VERSION ""

NS_ :

BS_:

BU_: PowertrainControlModule AtmosphericSensor SafetyRestraintSystem2 Aftertreatment_2_GasOutlet Aftertreatment_2_GasIntake DieselParticulateFilterControl Turbocharger SafetyRestraintSystem1 CabDisplay2 Aftertreatment_1_GasOutlet Aftertreatment_1_GasIntake OnBoardDataLogger OffBoardDiagnosticTool2 OffBoardDiagnosticTool1 FileServer ParkingBrakeController SeatController2 FanDriveController SteeringColumnUnit CommunicationUnitRadio CommunicationUnitSatellite CommunicationUnitCellular PropulsionBatteryCharger ChassisController2 ChassisController1 EngineValveControl AuxiliaryHeater2 AuxiliaryHeater1 ClutchUnit RampControl InformationSystem1 SuspensionSystemController2 OilSensor VehicleDynamicStability ExhaustEmissionController TransmissionDisplay2 TransmissionDisplay1 ClimateControl2 WaterPumpController RearAxleSteeringController LightingOperatorControl SeatController1 IgnitionController2 IgnitionController1 TirePressureController CabController2 CabController1 PneumaticSystemController SuspensionSystemController1 HydraulicPumpController EnduranceBrakingSystem RetarderExhaustEngine2 OnBoardDiagnosticUnit HeadwayController RetarderExhaustEngine1 CabDisplay1 ManagementComputer VirtualTerminal OffVehicleGateway PowerTakeOffFront HitchControl AuxiliaryValveControl BodyController TractorTrailerBridge1 StarterSystem ElectricalSystem VehicleSecurity VehicleNavigation AerodynamicControl ElectricalChargingSystem ClimateControl1 TripRecorder InstrumentCluster SuspensionDriveAxle2 SuspensionDriveAxle1 SuspensionSteerAxle SteeringController FuelSystem CruiseControl RetarderDriveline RetarderEngine BrakesDriveAxle2 BrakesDriveAxle1 BrakesSystemController BrakesSteerAxle AxleDrive2 AxleDrive1 AxleSteering PowerTakeOff ShiftConsoleSecondary ShiftConsolePrimary Transmission2 Transmission1 Engine2 Engine1

BO_ 2566697982 FPOC: 64 Vector__XXX
 SG_ FusedOutput32Current : 496|16@1+ (0.005,0) [0|321.275] "A" Vector__XXX
 SG_ FusedOutput31Current : 480|16@1+ (0.005,0) [0|321.275] "A" Vector__XXX
 SG_ FusedOutput30Current : 464|16@1+ (0.005,0) [0|321.275] "A" Vector__XXX
 SG_ FusedOutput29Current : 448|16@1+ (0.005,0) [0|321.275] "A" Vector__XXX
 SG_ FusedOutput28Current : 432|16@1+ (0.005,0) [0|321.275] "A" Vector__XXX
 SG_ FusedOutput27Current : 416|16@1+ (0.005,0) [0|321.275] "A" Vector__XXX
 SG_ FusedOutput26Current : 400|16@1+ (0.005,0) [0|321.275] "A" Vector__XXX
 SG_ FusedOutput25Current : 384|16@1+ (0.005,0) [0|321.275] "A" Vector__XXX
 SG_ FusedOutput24Current : 368|16@1+ (0.005,0) [0|321.275] "A" Vector__XXX
 SG_ FusedOutput23Current : 352|16@1+ (0.005,0) [0|321.275] "A" Vector__XXX
 SG_ FusedOutput22Current : 336|16@1+ (0.005,0) [0|321.275] "A" Vector__XXX
 SG_ FusedOutput21Current : 320|16@1+ (0.005,0) [0|321.275] "A" Vector__XXX
 SG_ FusedOutput20Current : 304|16@1+ (0.005,0) [0|321.275] "A" Vector__XXX
 SG_ FusedOutput19Current : 288|16@1+ (0.005,0) [0|321.275] "A" Vector__XXX
 SG_ FusedOutput18Current : 272|16@1+ (0.005,0) [0|321.275] "A" Vector__XXX
 SG_ FusedOutput17Current : 256|16@1+ (0.005,0) [0|321.275] "A" Vector__XXX
 SG_ FusedOutput16Current : 240|16@1+ (0.005,0) [0|321.275] "A" Vector__XXX
 SG_ FusedOutput15Current : 224|16@1+ (0.005,0) [0|321.275] "A" Vector__XXX
 SG_ FusedOutput14Current : 208|16@1+ (0.005,0) [0|321.275] "A" Vector__XXX
 SG_ FusedOutput13Current : 192|16@1+ (0.005,0) [0|321.275] "A" Vector__XXX
 SG_ FusedOutput12Current : 176|16@1+ (0.005,0) [0|321.275] "A" Vector__XXX
 SG_ FusedOutput11Current : 160|16@1+ (0.005,0) [0|321.275] "A" Vector__XXX
 SG_ FusedOutput10Current : 144|16@1+ (0.005,0) [0|321.275] "A" Vector__XXX
 SG_ FusedOutput9Current : 128|16@1+ (0.005,0) [0|321.275] "A" Vector__XXX
 SG_ FusedOutput8Current : 112|16@1+ (0.005,0) [0|321.275] "A" Vector__XXX
 SG_ FusedOutput7Current : 96|16@1+ (0.005,0) [0|321.275] "A" Vector__XXX
 SG_ FusedOutput6Current : 80|16@1+ (0.005,0) [0|321.275] "A" Vector__XXX
 SG_ FusedOutput5Current : 64|16@1+ (0.005,0) [0|321.275] "A" Vector__XXX
 SG_ FusedOutput4Current : 48|16@1+ (0.005,0) [0|321.275] "A" Vector__XXX
 SG_ FusedOutput3Current : 32|16@1+ (0.005,0) [0|321.275] "A" Vector__XXX
 SG_ FusedOutput2Current : 16|16@1+ (0.005,0) [0|321.275] "A" Vector__XXX
 SG_ FusedOutput1Current : 0|16@1+ (0.005,0) [0|321.275] "A" Vector__XXX

BO_ 2566697726 SPOC1: 64 Vector__XXX
 SG_ SwitchedOutput32Current : 496|16@1+ (0.005,0) [0|321.275] "A" Vector__XXX
 SG_ SwitchedOutput31Current : 480|16@1+ (0.005,0) [0|321.275] "A" Vector__XXX
 SG_ SwitchedOutput30Current : 464|16@1+ (0.005,0) [0|321.275] "A" Vector__XXX
 SG_ SwitchedOutput29Current : 448|16@1+ (0.005,0) [0|321.275] "A" Vector__XXX
 SG_ SwitchedOutput28Current : 432|16@1+ (0.005,0) [0|321.275] "A" Vector__XXX
 SG_ SwitchedOutput27Current : 416|16@1+ (0.005,0) [0|321.275] "A" Vector__XXX
 SG_ SwitchedOutput26Current : 400|16@1+ (0.005,0) [0|321.275] "A" Vector__XXX
 SG_ SwitchedOutput25Current : 384|16@1+ (0.005,0) [0|321.275] "A" Vector__XXX
 SG_ SwitchedOutput24Current : 368|16@1+ (0.005,0) [0|321.275] "A" Vector__XXX
 SG_ SwitchedOutput23Current : 352|16@1+ (0.005,0) [0|321.275] "A" Vector__XXX
 SG_ SwitchedOutput22Current : 336|16@1+ (0.005,0) [0|321.275] "A" Vector__XXX
 SG_ SwitchedOutput21Current : 320|16@1+ (0.005,0) [0|321.275] "A" Vector__XXX
 SG_ SwitchedOutput20Current : 304|16@1+ (0.005,0) [0|321.275] "A" Vector__XXX
 SG_ SwitchedOutput19Current : 288|16@1+ (0.005,0) [0|321.275] "A" Vector__XXX
 SG_ SwitchedOutput18Current : 272|16@1+ (0.005,0) [0|321.275] "A" Vector__XXX
 SG_ SwitchedOutput17Current : 256|16@1+ (0.005,0) [0|321.275] "A" Vector__XXX
 SG_ SwitchedOutput16Current : 240|16@1+ (0.005,0) [0|321.275] "A" Vector__XXX
 SG_ SwitchedOutput15Current : 224|16@1+ (0.005,0) [0|321.275] "A" Vector__XXX
 SG_ SwitchedOutput14Current : 208|16@1+ (0.005,0) [0|321.275] "A" Vector__XXX
 SG_ SwitchedOutput13Current : 192|16@1+ (0.005,0) [0|321.275] "A" Vector__XXX
 SG_ SwitchedOutput12Current : 176|16@1+ (0.005,0) [0|321.275] "A" Vector__XXX
 SG_ SwitchedOutput11Current : 160|16@1+ (0.005,0) [0|321.275] "A" Vector__XXX
 SG_ SwitchedOutput10Current : 144|16@1+ (0.005,0) [0|321.275] "A" Vector__XXX
 SG_ SwitchedOutput9Current : 128|16@1+ (0.005,0) [0|321.275] "A" Vector__XXX
 SG_ SwitchedOutput8Current : 112|16@1+ (0.005,0) [0|321.275] "A" Vector__XXX
 SG_ SwitchedOutput7Current : 96|16@1+ (0.005,0) [0|321.275] "A" Vector__XXX
 SG_ SwitchedOutput6Current : 80|16@1+ (0.005,0) [0|321.275] "A" Vector__XXX
 SG_ SwitchedOutput5Current : 64|16@1+ (0.005,0) [0|321.275] "A" Vector__XXX
 SG_ SwitchedOutput4Current : 48|16@1+ (0.005,0) [0|321.275] "A" Vector__XXX
 SG_ SwitchedOutput3Current : 32|16@1+ (0.005,0) [0|321.275] "A" Vector__XXX
 SG_ SwitchedOutput2Current : 16|16@1+ (0.005,0) [0|321.275] "A" Vector__XXX
 SG_ SwitchedOutput1Current : 0|16@1+ (0.005,0) [0|321.275] "A" Vector__XXX

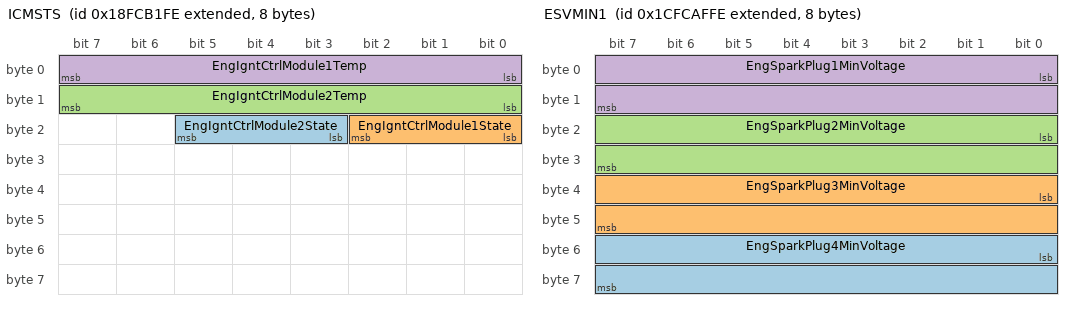
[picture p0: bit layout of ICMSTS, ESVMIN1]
BO_ 2566697470 ICMSTS: 8 Vector__XXX
 SG_ EngIgntCtrlModule2State : 19|3@1+ (1,0) [0|7] "" Vector__XXX
 SG_ EngIgntCtrlModule1State : 16|3@1+ (1,0) [0|7] "" Vector__XXX
 SG_ EngIgntCtrlModule2Temp : 8|8@1+ (1,-40) [-40|210] "°C" Vector__XXX
 SG_ EngIgntCtrlModule1Temp : 0|8@1+ (1,-40) [-40|210] "°C" Vector__XXX

BO_ 2633806078 EICMH: 8 Vector__XXX
 SG_ EngIgntCtrlModule2TimeRemaining : 32|32@1+ (0.05,0) [0|210554060.75] "h" Vector__XXX
 SG_ EngIgntCtrlModule1TimeRemaining : 0|32@1+ (0.05,0) [0|210554060.75] "h" Vector__XXX

BO_ 2633805822 ESVMIN1: 8 Vector__XXX
 SG_ EngSparkPlug4MinVoltage : 48|16@1+ (1,0) [0|64255] "V" Vector__XXX
 SG_ EngSparkPlug3MinVoltage : 32|16@1+ (1,0) [0|64255] "V" Vector__XXX
 SG_ EngSparkPlug2MinVoltage : 16|16@1+ (1,0) [0|64255] "V" Vector__XXX
 SG_ EngSparkPlug1MinVoltage : 0|16@1+ (1,0) [0|64255] "V" Vector__XXX

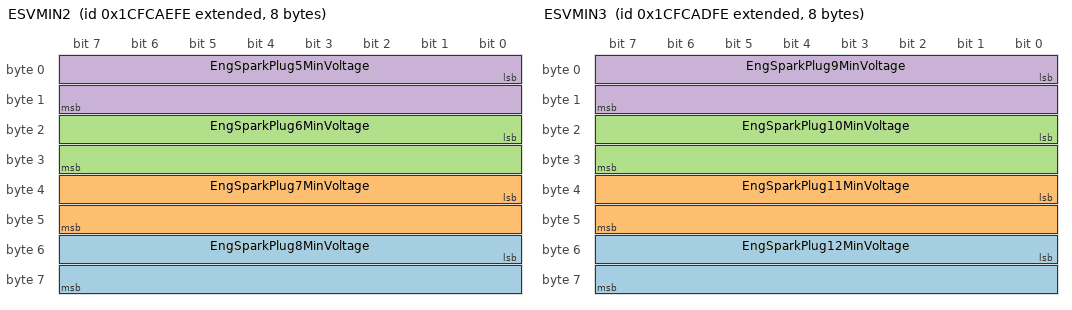
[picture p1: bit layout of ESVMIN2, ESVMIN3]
BO_ 2633805566 ESVMIN2: 8 Vector__XXX
 SG_ EngSparkPlug8MinVoltage : 48|16@1+ (1,0) [0|64255] "V" Vector__XXX
 SG_ EngSparkPlug7MinVoltage : 32|16@1+ (1,0) [0|64255] "V" Vector__XXX
 SG_ EngSparkPlug6MinVoltage : 16|16@1+ (1,0) [0|64255] "V" Vector__XXX
 SG_ EngSparkPlug5MinVoltage : 0|16@1+ (1,0) [0|64255] "V" Vector__XXX

BO_ 2633805310 ESVMIN3: 8 Vector__XXX
 SG_ EngSparkPlug12MinVoltage : 48|16@1+ (1,0) [0|64255] "V" Vector__XXX
 SG_ EngSparkPlug11MinVoltage : 32|16@1+ (1,0) [0|64255] "V" Vector__XXX
 SG_ EngSparkPlug10MinVoltage : 16|16@1+ (1,0) [0|64255] "V" Vector__XXX
 SG_ EngSparkPlug9MinVoltage : 0|16@1+ (1,0) [0|64255] "V" Vector__XXX

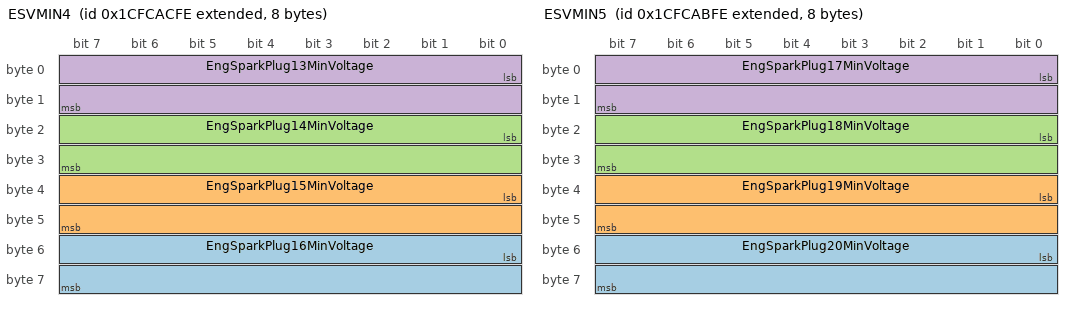
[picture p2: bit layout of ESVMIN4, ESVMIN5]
BO_ 2633805054 ESVMIN4: 8 Vector__XXX
 SG_ EngSparkPlug16MinVoltage : 48|16@1+ (1,0) [0|64255] "V" Vector__XXX
 SG_ EngSparkPlug15MinVoltage : 32|16@1+ (1,0) [0|64255] "V" Vector__XXX
 SG_ EngSparkPlug14MinVoltage : 16|16@1+ (1,0) [0|64255] "V" Vector__XXX
 SG_ EngSparkPlug13MinVoltage : 0|16@1+ (1,0) [0|64255] "V" Vector__XXX

BO_ 2633804798 ESVMIN5: 8 Vector__XXX
 SG_ EngSparkPlug20MinVoltage : 48|16@1+ (1,0) [0|64255] "V" Vector__XXX
 SG_ EngSparkPlug19MinVoltage : 32|16@1+ (1,0) [0|64255] "V" Vector__XXX
 SG_ EngSparkPlug18MinVoltage : 16|16@1+ (1,0) [0|64255] "V" Vector__XXX
 SG_ EngSparkPlug17MinVoltage : 0|16@1+ (1,0) [0|64255] "V" Vector__XXX

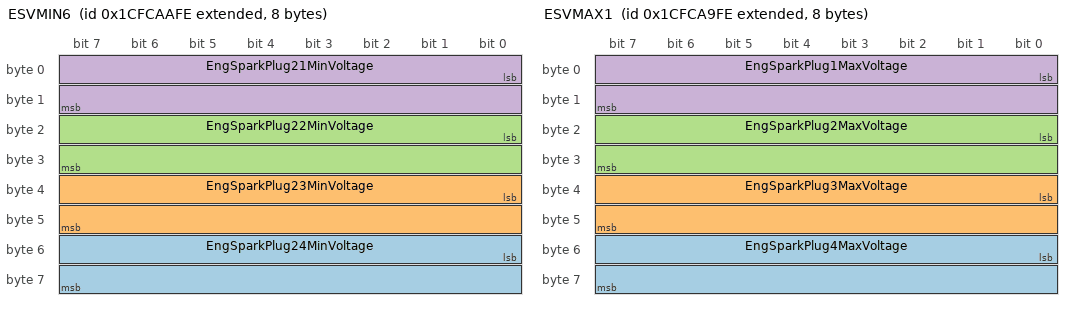
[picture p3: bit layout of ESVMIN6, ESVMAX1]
BO_ 2633804542 ESVMIN6: 8 Vector__XXX
 SG_ EngSparkPlug24MinVoltage : 48|16@1+ (1,0) [0|64255] "V" Vector__XXX
 SG_ EngSparkPlug23MinVoltage : 32|16@1+ (1,0) [0|64255] "V" Vector__XXX
 SG_ EngSparkPlug22MinVoltage : 16|16@1+ (1,0) [0|64255] "V" Vector__XXX
 SG_ EngSparkPlug21MinVoltage : 0|16@1+ (1,0) [0|64255] "V" Vector__XXX

BO_ 2633804286 ESVMAX1: 8 Vector__XXX
 SG_ EngSparkPlug4MaxVoltage : 48|16@1+ (1,0) [0|64255] "V" Vector__XXX
 SG_ EngSparkPlug3MaxVoltage : 32|16@1+ (1,0) [0|64255] "V" Vector__XXX
 SG_ EngSparkPlug2MaxVoltage : 16|16@1+ (1,0) [0|64255] "V" Vector__XXX
 SG_ EngSparkPlug1MaxVoltage : 0|16@1+ (1,0) [0|64255] "V" Vector__XXX

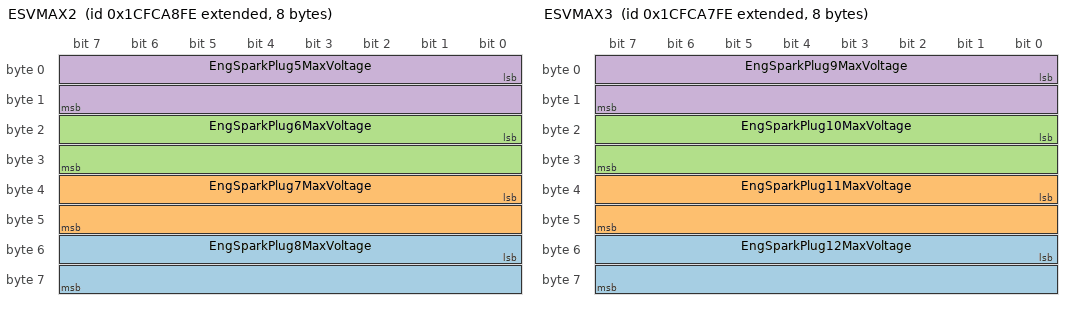
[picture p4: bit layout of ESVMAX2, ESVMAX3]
BO_ 2633804030 ESVMAX2: 8 Vector__XXX
 SG_ EngSparkPlug8MaxVoltage : 48|16@1+ (1,0) [0|64255] "V" Vector__XXX
 SG_ EngSparkPlug7MaxVoltage : 32|16@1+ (1,0) [0|64255] "V" Vector__XXX
 SG_ EngSparkPlug6MaxVoltage : 16|16@1+ (1,0) [0|64255] "V" Vector__XXX
 SG_ EngSparkPlug5MaxVoltage : 0|16@1+ (1,0) [0|64255] "V" Vector__XXX

BO_ 2633803774 ESVMAX3: 8 Vector__XXX
 SG_ EngSparkPlug12MaxVoltage : 48|16@1+ (1,0) [0|64255] "V" Vector__XXX
 SG_ EngSparkPlug11MaxVoltage : 32|16@1+ (1,0) [0|64255] "V" Vector__XXX
 SG_ EngSparkPlug10MaxVoltage : 16|16@1+ (1,0) [0|64255] "V" Vector__XXX
 SG_ EngSparkPlug9MaxVoltage : 0|16@1+ (1,0) [0|64255] "V" Vector__XXX

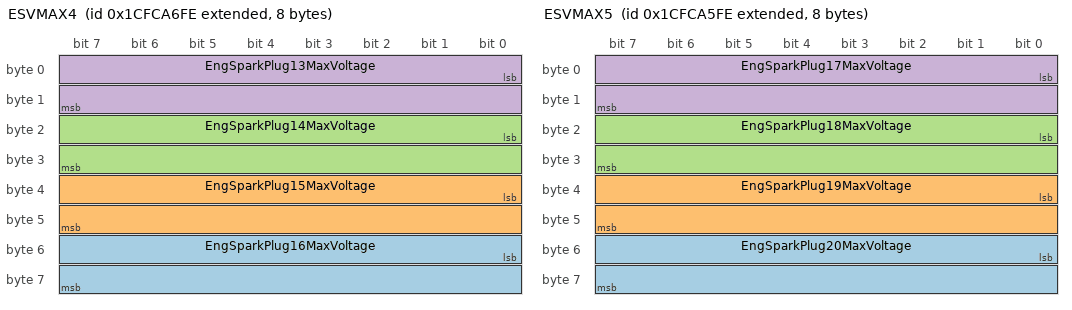
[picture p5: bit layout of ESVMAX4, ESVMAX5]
BO_ 2633803518 ESVMAX4: 8 Vector__XXX
 SG_ EngSparkPlug16MaxVoltage : 48|16@1+ (1,0) [0|64255] "V" Vector__XXX
 SG_ EngSparkPlug15MaxVoltage : 32|16@1+ (1,0) [0|64255] "V" Vector__XXX
 SG_ EngSparkPlug14MaxVoltage : 16|16@1+ (1,0) [0|64255] "V" Vector__XXX
 SG_ EngSparkPlug13MaxVoltage : 0|16@1+ (1,0) [0|64255] "V" Vector__XXX

BO_ 2633803262 ESVMAX5: 8 Vector__XXX
 SG_ EngSparkPlug20MaxVoltage : 48|16@1+ (1,0) [0|64255] "V" Vector__XXX
 SG_ EngSparkPlug19MaxVoltage : 32|16@1+ (1,0) [0|64255] "V" Vector__XXX
 SG_ EngSparkPlug18MaxVoltage : 16|16@1+ (1,0) [0|64255] "V" Vector__XXX
 SG_ EngSparkPlug17MaxVoltage : 0|16@1+ (1,0) [0|64255] "V" Vector__XXX

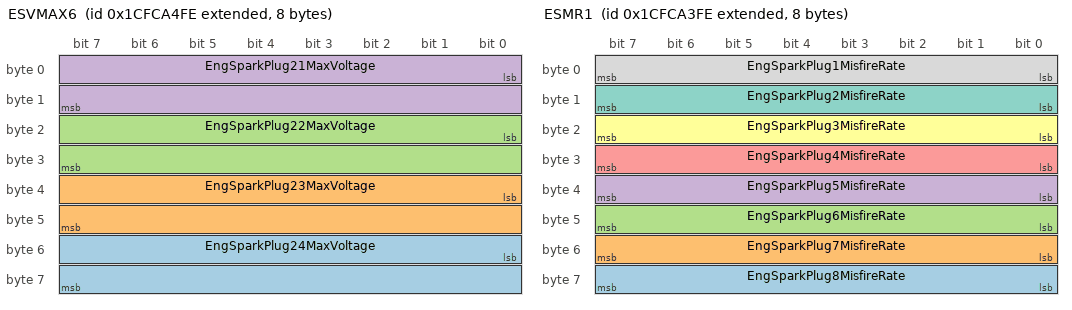
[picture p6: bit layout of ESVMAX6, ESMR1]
BO_ 2633803006 ESVMAX6: 8 Vector__XXX
 SG_ EngSparkPlug24MaxVoltage : 48|16@1+ (1,0) [0|64255] "V" Vector__XXX
 SG_ EngSparkPlug23MaxVoltage : 32|16@1+ (1,0) [0|64255] "V" Vector__XXX
 SG_ EngSparkPlug22MaxVoltage : 16|16@1+ (1,0) [0|64255] "V" Vector__XXX
 SG_ EngSparkPlug21MaxVoltage : 0|16@1+ (1,0) [0|64255] "V" Vector__XXX

BO_ 2633802750 ESMR1: 8 Vector__XXX
 SG_ EngSparkPlug8MisfireRate : 56|8@1+ (0.4,0) [0|100] "%" Vector__XXX
 SG_ EngSparkPlug7MisfireRate : 48|8@1+ (0.4,0) [0|100] "%" Vector__XXX
 SG_ EngSparkPlug6MisfireRate : 40|8@1+ (0.4,0) [0|100] "%" Vector__XXX
 SG_ EngSparkPlug5MisfireRate : 32|8@1+ (0.4,0) [0|100] "%" Vector__XXX
 SG_ EngSparkPlug4MisfireRate : 24|8@1+ (0.4,0) [0|100] "%" Vector__XXX
 SG_ EngSparkPlug3MisfireRate : 16|8@1+ (0.4,0) [0|100] "%" Vector__XXX
 SG_ EngSparkPlug2MisfireRate : 8|8@1+ (0.4,0) [0|100] "%" Vector__XXX
 SG_ EngSparkPlug1MisfireRate : 0|8@1+ (0.4,0) [0|100] "%" Vector__XXX

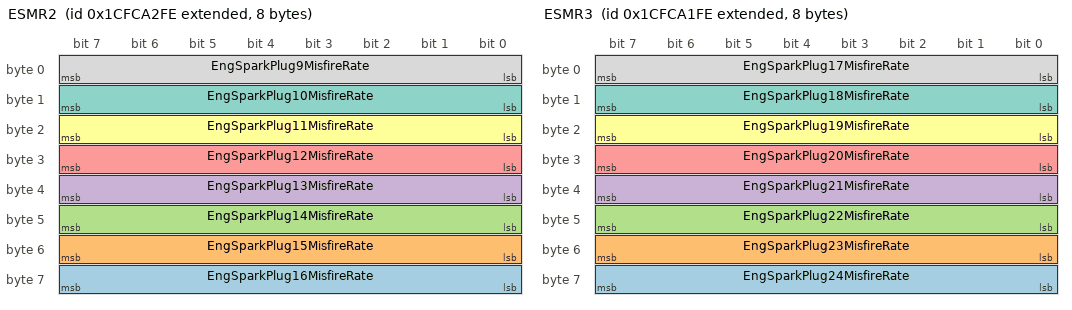
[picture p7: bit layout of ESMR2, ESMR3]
BO_ 2633802494 ESMR2: 8 Vector__XXX
 SG_ EngSparkPlug16MisfireRate : 56|8@1+ (0.4,0) [0|100] "%" Vector__XXX
 SG_ EngSparkPlug15MisfireRate : 48|8@1+ (0.4,0) [0|100] "%" Vector__XXX
 SG_ EngSparkPlug14MisfireRate : 40|8@1+ (0.4,0) [0|100] "%" Vector__XXX
 SG_ EngSparkPlug13MisfireRate : 32|8@1+ (0.4,0) [0|100] "%" Vector__XXX
 SG_ EngSparkPlug12MisfireRate : 24|8@1+ (0.4,0) [0|100] "%" Vector__XXX
 SG_ EngSparkPlug11MisfireRate : 16|8@1+ (0.4,0) [0|100] "%" Vector__XXX
 SG_ EngSparkPlug10MisfireRate : 8|8@1+ (0.4,0) [0|100] "%" Vector__XXX
 SG_ EngSparkPlug9MisfireRate : 0|8@1+ (0.4,0) [0|100] "%" Vector__XXX

BO_ 2633802238 ESMR3: 8 Vector__XXX
 SG_ EngSparkPlug24MisfireRate : 56|8@1+ (0.4,0) [0|100] "%" Vector__XXX
 SG_ EngSparkPlug23MisfireRate : 48|8@1+ (0.4,0) [0|100] "%" Vector__XXX
 SG_ EngSparkPlug22MisfireRate : 40|8@1+ (0.4,0) [0|100] "%" Vector__XXX
 SG_ EngSparkPlug21MisfireRate : 32|8@1+ (0.4,0) [0|100] "%" Vector__XXX
 SG_ EngSparkPlug20MisfireRate : 24|8@1+ (0.4,0) [0|100] "%" Vector__XXX
 SG_ EngSparkPlug19MisfireRate : 16|8@1+ (0.4,0) [0|100] "%" Vector__XXX
 SG_ EngSparkPlug18MisfireRate : 8|8@1+ (0.4,0) [0|100] "%" Vector__XXX
 SG_ EngSparkPlug17MisfireRate : 0|8@1+ (0.4,0) [0|100] "%" Vector__XXX

BO_ 2633801982 MFEH: 8 Vector__XXX
 SG_ EngTtlHoursOfDieselFuelOperation : 32|32@1+ (0.05,0) [0|210554060.75] "h" Vector__XXX
 SG_ EngTotalHoursOfGasFuelOperation : 0|32@1+ (0.05,0) [0|210554060.75] "h" Vector__XXX

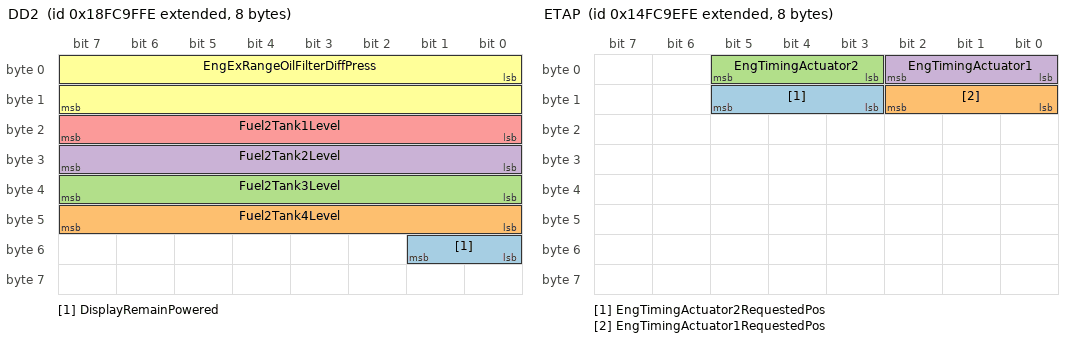
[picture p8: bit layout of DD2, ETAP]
BO_ 2566692862 DD2: 8 Vector__XXX
 SG_ DisplayRemainPowered : 48|2@1+ (1,0) [0|3] "" Vector__XXX
 SG_ Fuel2Tank4Level : 40|8@1+ (0.4,0) [0|100] "%" Vector__XXX
 SG_ Fuel2Tank3Level : 32|8@1+ (0.4,0) [0|100] "%" Vector__XXX
 SG_ Fuel2Tank2Level : 24|8@1+ (0.4,0) [0|100] "%" Vector__XXX
 SG_ Fuel2Tank1Level : 16|8@1+ (0.4,0) [0|100] "%" Vector__XXX
 SG_ EngExRangeOilFilterDiffPress : 0|16@1+ (0.0078125,-250) [-250|251.99] "kPa" Vector__XXX

BO_ 2499583742 ETAP: 8 Vector__XXX
 SG_ EngTimingActuator2RequestedPos : 11|3@1+ (1,0) [0|7] "" Vector__XXX
 SG_ EngTimingActuator1RequestedPos : 8|3@1+ (1,0) [0|7] "" Vector__XXX
 SG_ EngTimingActuator2 : 3|3@1+ (1,0) [0|7] "" Vector__XXX
 SG_ EngTimingActuator1 : 0|3@1+ (1,0) [0|7] "" Vector__XXX

BO_ 2499583486 ETAPC: 8 Vector__XXX
 SG_ EngTimingActuator2PosCmd : 3|3@1+ (1,0) [0|7] "" Vector__XXX
 SG_ EngTimingActuator1PosCmd : 0|3@1+ (1,0) [0|7] "" Vector__XXX

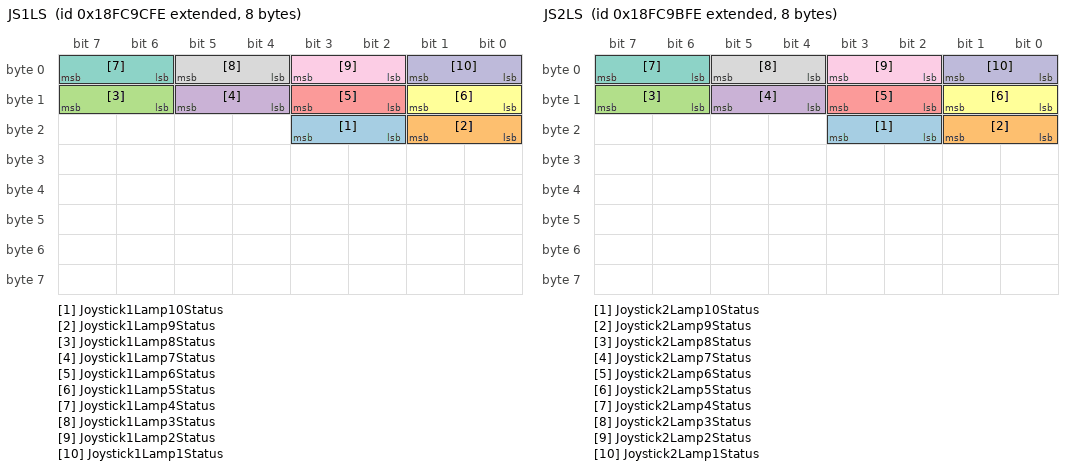
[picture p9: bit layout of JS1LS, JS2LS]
BO_ 2566692094 JS1LS: 8 Vector__XXX
 SG_ Joystick1Lamp10Status : 18|2@1+ (1,0) [0|3] "" Vector__XXX
 SG_ Joystick1Lamp9Status : 16|2@1+ (1,0) [0|3] "" Vector__XXX
 SG_ Joystick1Lamp8Status : 14|2@1+ (1,0) [0|3] "" Vector__XXX
 SG_ Joystick1Lamp7Status : 12|2@1+ (1,0) [0|3] "" Vector__XXX
 SG_ Joystick1Lamp6Status : 10|2@1+ (1,0) [0|3] "" Vector__XXX
 SG_ Joystick1Lamp5Status : 8|2@1+ (1,0) [0|3] "" Vector__XXX
 SG_ Joystick1Lamp4Status : 6|2@1+ (1,0) [0|3] "" Vector__XXX
 SG_ Joystick1Lamp3Status : 4|2@1+ (1,0) [0|3] "" Vector__XXX
 SG_ Joystick1Lamp2Status : 2|2@1+ (1,0) [0|3] "" Vector__XXX
 SG_ Joystick1Lamp1Status : 0|2@1+ (1,0) [0|3] "" Vector__XXX

BO_ 2566691838 JS2LS: 8 Vector__XXX
 SG_ Joystick2Lamp10Status : 18|2@1+ (1,0) [0|3] "" Vector__XXX
 SG_ Joystick2Lamp9Status : 16|2@1+ (1,0) [0|3] "" Vector__XXX
 SG_ Joystick2Lamp8Status : 14|2@1+ (1,0) [0|3] "" Vector__XXX
 SG_ Joystick2Lamp7Status : 12|2@1+ (1,0) [0|3] "" Vector__XXX
 SG_ Joystick2Lamp6Status : 10|2@1+ (1,0) [0|3] "" Vector__XXX
 SG_ Joystick2Lamp5Status : 8|2@1+ (1,0) [0|3] "" Vector__XXX
 SG_ Joystick2Lamp4Status : 6|2@1+ (1,0) [0|3] "" Vector__XXX
 SG_ Joystick2Lamp3Status : 4|2@1+ (1,0) [0|3] "" Vector__XXX
 SG_ Joystick2Lamp2Status : 2|2@1+ (1,0) [0|3] "" Vector__XXX
 SG_ Joystick2Lamp1Status : 0|2@1+ (1,0) [0|3] "" Vector__XXX

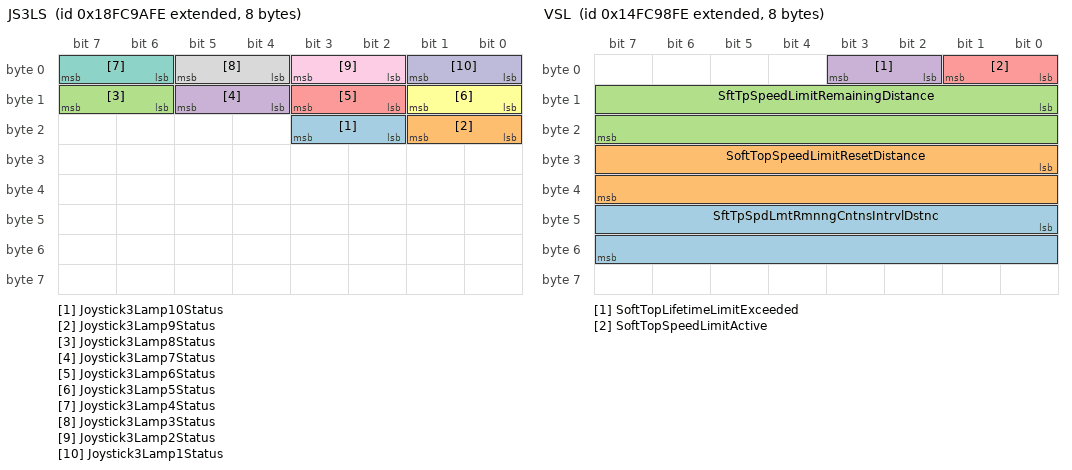
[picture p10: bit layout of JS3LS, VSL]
BO_ 2566691582 JS3LS: 8 Vector__XXX
 SG_ Joystick3Lamp10Status : 18|2@1+ (1,0) [0|3] "" Vector__XXX
 SG_ Joystick3Lamp9Status : 16|2@1+ (1,0) [0|3] "" Vector__XXX
 SG_ Joystick3Lamp8Status : 14|2@1+ (1,0) [0|3] "" Vector__XXX
 SG_ Joystick3Lamp7Status : 12|2@1+ (1,0) [0|3] "" Vector__XXX
 SG_ Joystick3Lamp6Status : 10|2@1+ (1,0) [0|3] "" Vector__XXX
 SG_ Joystick3Lamp5Status : 8|2@1+ (1,0) [0|3] "" Vector__XXX
 SG_ Joystick3Lamp4Status : 6|2@1+ (1,0) [0|3] "" Vector__XXX
 SG_ Joystick3Lamp3Status : 4|2@1+ (1,0) [0|3] "" Vector__XXX
 SG_ Joystick3Lamp2Status : 2|2@1+ (1,0) [0|3] "" Vector__XXX
 SG_ Joystick3Lamp1Status : 0|2@1+ (1,0) [0|3] "" Vector__XXX

BO_ 2566691326 AUI: 8 Vector__XXX
 SG_ AssemblyUnitIdentification : 8|8@1+ (1,0) [0|255] "" Vector__XXX
 SG_ NmbrOfAssmblyUntIdntfctionFields : 0|8@1+ (1,0) [0|250] "" Vector__XXX

BO_ 2499582206 VSL: 8 Vector__XXX
 SG_ SftTpSpdLmtRmnngCntnsIntrvlDstnc : 40|16@1+ (1,0) [0|64255] "km" Vector__XXX
 SG_ SoftTopSpeedLimitResetDistance : 24|16@1+ (1,0) [0|64255] "km" Vector__XXX
 SG_ SftTpSpeedLimitRemainingDistance : 8|16@1+ (1,0) [0|64255] "km" Vector__XXX
 SG_ SoftTopLifetimeLimitExceeded : 2|2@1+ (1,0) [0|3] "" Vector__XXX
 SG_ SoftTopSpeedLimitActive : 0|2@1+ (1,0) [0|3] "" Vector__XXX

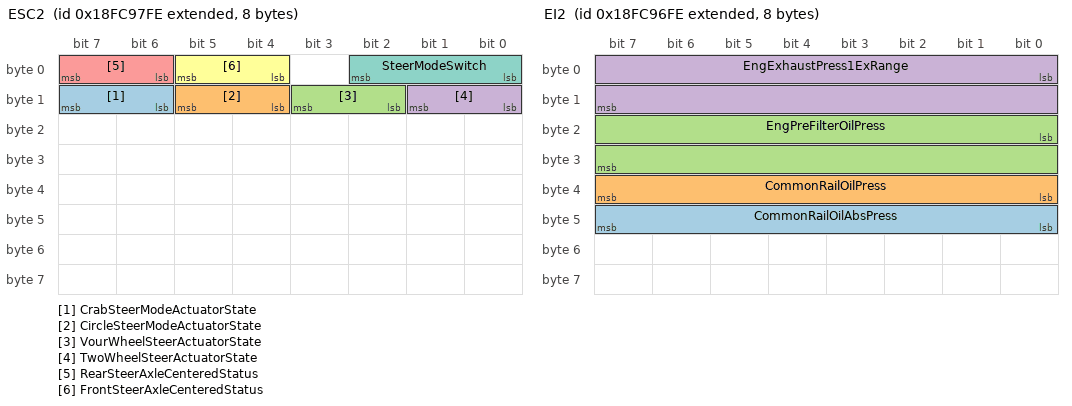
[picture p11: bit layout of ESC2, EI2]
BO_ 2566690814 ESC2: 8 Vector__XXX
 SG_ CrabSteerModeActuatorState : 14|2@1+ (1,0) [0|3] "" Vector__XXX
 SG_ CircleSteerModeActuatorState : 12|2@1+ (1,0) [0|3] "" Vector__XXX
 SG_ VourWheelSteerActuatorState : 10|2@1+ (1,0) [0|3] "" Vector__XXX
 SG_ TwoWheelSteerActuatorState : 8|2@1+ (1,0) [0|3] "" Vector__XXX
 SG_ RearSteerAxleCenteredStatus : 6|2@1+ (1,0) [0|3] "" Vector__XXX
 SG_ FrontSteerAxleCenteredStatus : 4|2@1+ (1,0) [0|3] "" Vector__XXX
 SG_ SteerModeSwitch : 0|3@1+ (1,0) [0|7] "" Vector__XXX

BO_ 2566690558 EI2: 8 Vector__XXX
 SG_ CommonRailOilAbsPress : 40|8@1+ (4,0) [0|1000] "kPa" Vector__XXX
 SG_ CommonRailOilPress : 32|8@1+ (4,0) [0|1000] "kPa" Vector__XXX
 SG_ EngPreFilterOilPress : 16|16@1+ (0.1,0) [0|6425.5] "kPa" Vector__XXX
 SG_ EngExhaustPress1ExRange : 0|16@1+ (0.125,0) [0|8031.875] "kPa" Vector__XXX

BO_ 2365363710 ECPMSI: 8 Vector__XXX
 SG_ EngCylPrssMonitor2PreliminaryFMI : 8|5@1+ (1,0) [0|31] "" Vector__XXX
 SG_ EngCylPrssMonitor1PreliminaryFMI : 0|5@1+ (1,0) [0|31] "" Vector__XXX

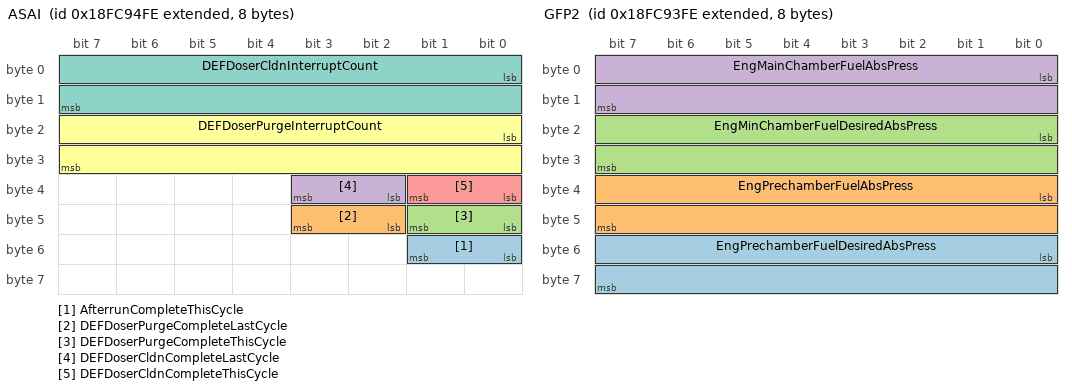
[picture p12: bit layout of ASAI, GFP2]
BO_ 2566690046 ASAI: 8 Vector__XXX
 SG_ AfterrunCompleteThisCycle : 48|2@1+ (1,0) [0|3] "" Vector__XXX
 SG_ DEFDoserPurgeCompleteLastCycle : 42|2@1+ (1,0) [0|3] "" Vector__XXX
 SG_ DEFDoserPurgeCompleteThisCycle : 40|2@1+ (1,0) [0|3] "" Vector__XXX
 SG_ DEFDoserCldnCompleteLastCycle : 34|2@1+ (1,0) [0|3] "" Vector__XXX
 SG_ DEFDoserCldnCompleteThisCycle : 32|2@1+ (1,0) [0|3] "" Vector__XXX
 SG_ DEFDoserPurgeInterruptCount : 16|16@1+ (1,0) [0|64255] "" Vector__XXX
 SG_ DEFDoserCldnInterruptCount : 0|16@1+ (1,0) [0|64255] "" Vector__XXX

BO_ 2566689790 GFP2: 8 Vector__XXX
 SG_ EngPrechamberFuelDesiredAbsPress : 48|16@1+ (0.1,0) [0|6425.5] "kPa" Vector__XXX
 SG_ EngPrechamberFuelAbsPress : 32|16@1+ (0.1,0) [0|6425.5] "kPa" Vector__XXX
 SG_ EngMinChamberFuelDesiredAbsPress : 16|16@1+ (0.1,0) [0|6425.5] "kPa" Vector__XXX
 SG_ EngMainChamberFuelAbsPress : 0|16@1+ (0.1,0) [0|6425.5] "kPa" Vector__XXX

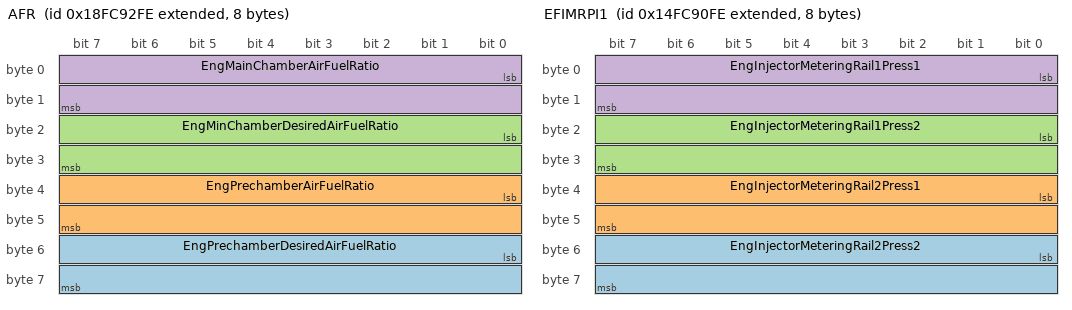
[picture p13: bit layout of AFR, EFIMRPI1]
BO_ 2566689534 AFR: 8 Vector__XXX
 SG_ EngPrechamberDesiredAirFuelRatio : 48|16@1+ (0.001,0) [0|64.255] "" Vector__XXX
 SG_ EngPrechamberAirFuelRatio : 32|16@1+ (0.001,0) [0|64.255] "" Vector__XXX
 SG_ EngMinChamberDesiredAirFuelRatio : 16|16@1+ (0.001,0) [0|64.255] "" Vector__XXX
 SG_ EngMainChamberAirFuelRatio : 0|16@1+ (0.001,0) [0|64.255] "" Vector__XXX

BO_ 2566689278 EEN: 8 Vector__XXX
 SG_ EngExhaustDesiredNOx : 16|16@1+ (0.05,-200) [-200|3012.75] "ppm" Vector__XXX
 SG_ EngExhaustNOx : 0|16@1+ (0.05,-200) [-200|3012.75] "ppm" Vector__XXX

BO_ 2499580158 EFIMRPI1: 8 Vector__XXX
 SG_ EngInjectorMeteringRail2Press2 : 48|16@1+ (0.00390625,0) [0|250.996] "MPa" Vector__XXX
 SG_ EngInjectorMeteringRail2Press1 : 32|16@1+ (0.00390625,0) [0|250.996] "MPa" Vector__XXX
 SG_ EngInjectorMeteringRail1Press2 : 16|16@1+ (0.00390625,0) [0|250.996] "MPa" Vector__XXX
 SG_ EngInjectorMeteringRail1Press1 : 0|16@1+ (0.00390625,0) [0|250.996] "MPa" Vector__XXX

BO_ 2432471038 AF3: 8 Vector__XXX
 SG_ GasFuelAccumulatorTemp : 24|8@1+ (1,-40) [-40|210] "°C" Vector__XXX
 SG_ EngFuelVaporizer1DischargeTemp : 16|8@1+ (1,-40) [-40|210] "°C" Vector__XXX
 SG_ EngGasFuelSupplyPress : 0|16@1+ (0.00390625,0) [0|250.996] "MPa" Vector__XXX

BO_ 2566688510 CFF: 8 Vector__XXX

BO_ 2566688254 PII: 8 Vector__XXX
 SG_ ProductIdentificationModel : 16|8@1+ (1,0) [0|0] "" Vector__XXX
 SG_ ProductIdentificationBrand : 8|8@1+ (1,0) [0|0] "" Vector__XXX
 SG_ ProductIdentificationCode : 0|8@1+ (1,0) [0|0] "" Vector__XXX

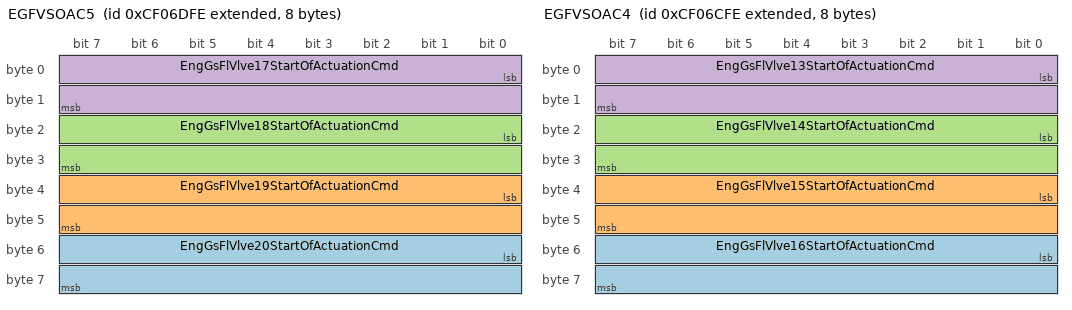
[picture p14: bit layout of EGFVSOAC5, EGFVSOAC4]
BO_ 2364567038 EGFVSOAC5: 8 Vector__XXX
 SG_ EngGsFlVlve20StartOfActuationCmd : 48|16@1+ (0.0078125,-400) [-400|101.99] "deg" Vector__XXX
 SG_ EngGsFlVlve19StartOfActuationCmd : 32|16@1+ (0.0078125,-400) [-400|101.99] "deg" Vector__XXX
 SG_ EngGsFlVlve18StartOfActuationCmd : 16|16@1+ (0.0078125,-400) [-400|101.99] "deg" Vector__XXX
 SG_ EngGsFlVlve17StartOfActuationCmd : 0|16@1+ (0.0078125,-400) [-400|101.99] "deg" Vector__XXX

BO_ 2364566782 EGFVSOAC4: 8 Vector__XXX
 SG_ EngGsFlVlve16StartOfActuationCmd : 48|16@1+ (0.0078125,-400) [-400|101.99] "deg" Vector__XXX
 SG_ EngGsFlVlve15StartOfActuationCmd : 32|16@1+ (0.0078125,-400) [-400|101.99] "deg" Vector__XXX
 SG_ EngGsFlVlve14StartOfActuationCmd : 16|16@1+ (0.0078125,-400) [-400|101.99] "deg" Vector__XXX
 SG_ EngGsFlVlve13StartOfActuationCmd : 0|16@1+ (0.0078125,-400) [-400|101.99] "deg" Vector__XXX

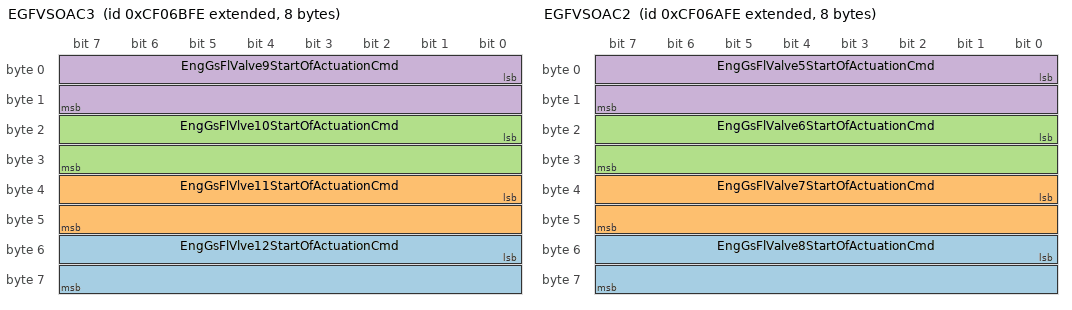
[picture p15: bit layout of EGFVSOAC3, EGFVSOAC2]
BO_ 2364566526 EGFVSOAC3: 8 Vector__XXX
 SG_ EngGsFlVlve12StartOfActuationCmd : 48|16@1+ (0.0078125,-400) [-400|101.99] "deg" Vector__XXX
 SG_ EngGsFlVlve11StartOfActuationCmd : 32|16@1+ (0.0078125,-400) [-400|101.99] "deg" Vector__XXX
 SG_ EngGsFlVlve10StartOfActuationCmd : 16|16@1+ (0.0078125,-400) [-400|101.99] "deg" Vector__XXX
 SG_ EngGsFlValve9StartOfActuationCmd : 0|16@1+ (0.0078125,-400) [-400|101.99] "deg" Vector__XXX

BO_ 2364566270 EGFVSOAC2: 8 Vector__XXX
 SG_ EngGsFlValve8StartOfActuationCmd : 48|16@1+ (0.0078125,-400) [-400|101.99] "deg" Vector__XXX
 SG_ EngGsFlValve7StartOfActuationCmd : 32|16@1+ (0.0078125,-400) [-400|101.99] "deg" Vector__XXX
 SG_ EngGsFlValve6StartOfActuationCmd : 16|16@1+ (0.0078125,-400) [-400|101.99] "deg" Vector__XXX
 SG_ EngGsFlValve5StartOfActuationCmd : 0|16@1+ (0.0078125,-400) [-400|101.99] "deg" Vector__XXX

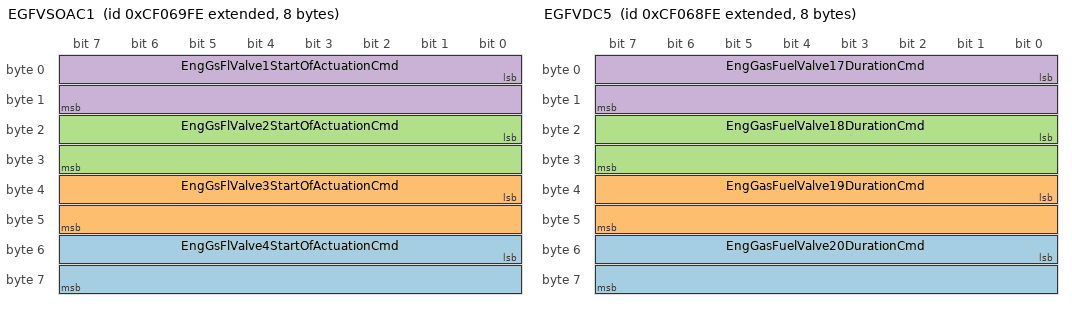
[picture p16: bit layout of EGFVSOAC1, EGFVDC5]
BO_ 2364566014 EGFVSOAC1: 8 Vector__XXX
 SG_ EngGsFlValve4StartOfActuationCmd : 48|16@1+ (0.0078125,-400) [-400|101.99] "deg" Vector__XXX
 SG_ EngGsFlValve3StartOfActuationCmd : 32|16@1+ (0.0078125,-400) [-400|101.99] "deg" Vector__XXX
 SG_ EngGsFlValve2StartOfActuationCmd : 16|16@1+ (0.0078125,-400) [-400|101.99] "deg" Vector__XXX
 SG_ EngGsFlValve1StartOfActuationCmd : 0|16@1+ (0.0078125,-400) [-400|101.99] "deg" Vector__XXX

BO_ 2364565758 EGFVDC5: 8 Vector__XXX
 SG_ EngGasFuelValve20DurationCmd : 48|16@1+ (2,0) [0|128510] "µs" Vector__XXX
 SG_ EngGasFuelValve19DurationCmd : 32|16@1+ (2,0) [0|128510] "µs" Vector__XXX
 SG_ EngGasFuelValve18DurationCmd : 16|16@1+ (2,0) [0|128510] "µs" Vector__XXX
 SG_ EngGasFuelValve17DurationCmd : 0|16@1+ (2,0) [0|128510] "µs" Vector__XXX

BO_ 2364565502 EGFVDC4: 8 Vector__XXX
 SG_ EngGasFuelValve16DurationCmd : 48|16@1+ (2,0) [0|128510] "µs" Vector__XXX
 SG_ EngGasFuelValve15DurationCmd : 32|16@1+ (2,0) [0|128510] "µs" Vector__XXX
 SG_ EngGasFuelValve14DurationCmd : 16|16@1+ (2,0) [0|128510] "µs" Vector__XXX
 SG_ EngGasFuelValve13DurationCmd : 0|16@1+ (2,0) [0|128510] "µs" Vector__XXX

BO_ 2364565246 EGFVDC3: 8 Vector__XXX
 SG_ EngGasFuelValve12DurationCmd : 48|16@1+ (2,0) [0|128510] "µs" Vector__XXX
 SG_ EngGasFuelValve11DurationCmd : 32|16@1+ (2,0) [0|128510] "µs" Vector__XXX
 SG_ EngGasFuelValve10DurationCmd : 16|16@1+ (2,0) [0|128510] "µs" Vector__XXX
 SG_ EngGasFuelValve9DurationCmd : 0|16@1+ (2,0) [0|128510] "µs" Vector__XXX

BO_ 2364564990 EGFVDC2: 8 Vector__XXX
 SG_ EngGasFuelValve8DurationCmd : 48|16@1+ (2,0) [0|128510] "µs" Vector__XXX
 SG_ EngGasFuelValve7DurationCmd : 32|16@1+ (2,0) [0|128510] "µs" Vector__XXX
 SG_ EngGasFuelValve6DurationCmd : 16|16@1+ (2,0) [0|128510] "µs" Vector__XXX
 SG_ EngGasFuelValve5DurationCmd : 0|16@1+ (2,0) [0|128510] "µs" Vector__XXX

BO_ 2364564734 EGFVDC1: 8 Vector__XXX
 SG_ EngGasFuelValve4DurationCmd : 48|16@1+ (2,0) [0|128510] "µs" Vector__XXX
 SG_ EngGasFuelValve3DurationCmd : 32|16@1+ (2,0) [0|128510] "µs" Vector__XXX
 SG_ EngGasFuelValve2DurationCmd : 16|16@1+ (2,0) [0|128510] "µs" Vector__XXX
 SG_ EngGasFuelValve1DurationCmd : 0|16@1+ (2,0) [0|128510] "µs" Vector__XXX

BO_ 2364564478 GFI5: 8 Vector__XXX
 SG_ EngGsFlVlvNmnlStrtOfActuationCmd : 16|16@1+ (0.0078125,-400) [-400|101.99] "deg" Vector__XXX
 SG_ EngGsFuelValveNominalDurationCmd : 0|16@1+ (2,0) [0|128510] "µs" Vector__XXX

BO_ 2297455358 ETC12: 8 Vector__XXX
 SG_ TransDirectionalOutputShaftSpeed : 32|16@1+ (1,-32127) [-32127|32128] "rpm" Vector__XXX
 SG_ TransHydrostaticLoop2Press : 16|16@1+ (1,0) [0|64255] "kPa" Vector__XXX
 SG_ TransHydrostaticLoop1Press : 0|16@1+ (1,0) [0|64255] "kPa" Vector__XXX

BO_ 2498781694 ECCAI20: 8 Vector__XXX
 SG_ EngCyl20AvrageCombustionDuration : 48|16@1+ (0.0078125,0) [0|501.99] "deg" Vector__XXX
 SG_ EngCyl20AvrgCntrOfCmbstionTiming : 32|16@1+ (0.0078125,-250) [-250|250.992] "deg" Vector__XXX
 SG_ EngCyl20AvrgStrtOfCmbstionTiming : 16|16@1+ (0.0078125,-250) [-250|250.992] "deg" Vector__XXX
 SG_ EngCyl20IndctdMeanEffectivePress : 0|16@1+ (0.0001220703125,-1) [-1|6.84362793] "MPa" Vector__XXX

BO_ 2498781438 ECCAI19: 8 Vector__XXX
 SG_ EngCyl19AvrageCombustionDuration : 48|16@1+ (0.0078125,0) [0|501.99] "deg" Vector__XXX
 SG_ EngCyl19AvrgCntrOfCmbstionTiming : 32|16@1+ (0.0078125,-250) [-250|250.992] "deg" Vector__XXX
 SG_ EngCyl19AvrgStrtOfCmbstionTiming : 16|16@1+ (0.0078125,-250) [-250|250.992] "deg" Vector__XXX
 SG_ EngCyl19IndctdMeanEffectivePress : 0|16@1+ (0.0001220703125,-1) [-1|6.84362793] "MPa" Vector__XXX

BO_ 2498781182 ECCAI18: 8 Vector__XXX
 SG_ EngCyl18AvrageCombustionDuration : 48|16@1+ (0.0078125,0) [0|501.99] "deg" Vector__XXX
 SG_ EngCyl18AvrgCntrOfCmbstionTiming : 32|16@1+ (0.0078125,-250) [-250|250.992] "deg" Vector__XXX
 SG_ EngCyl18AvrgStrtOfCmbstionTiming : 16|16@1+ (0.0078125,-250) [-250|250.992] "deg" Vector__XXX
 SG_ EngCyl18IndctdMeanEffectivePress : 0|16@1+ (0.0001220703125,-1) [-1|6.84362793] "MPa" Vector__XXX

BO_ 2498780926 ECCAI17: 8 Vector__XXX
 SG_ EngCyl17AvrageCombustionDuration : 48|16@1+ (0.0078125,0) [0|501.99] "deg" Vector__XXX
 SG_ EngCyl17AvrgCntrOfCmbstionTiming : 32|16@1+ (0.0078125,-250) [-250|250.992] "deg" Vector__XXX
 SG_ EngCyl17AvrgStrtOfCmbstionTiming : 16|16@1+ (0.0078125,-250) [-250|250.992] "deg" Vector__XXX
 SG_ EngCyl17IndctdMeanEffectivePress : 0|16@1+ (0.0001220703125,-1) [-1|6.84362793] "MPa" Vector__XXX

BO_ 2498780670 ECCAI16: 8 Vector__XXX
 SG_ EngCyl16AvrageCombustionDuration : 48|16@1+ (0.0078125,0) [0|501.99] "deg" Vector__XXX
 SG_ EngCyl16AvrgCntrOfCmbstionTiming : 32|16@1+ (0.0078125,-250) [-250|250.992] "deg" Vector__XXX
 SG_ EngCyl16AvrgStrtOfCmbstionTiming : 16|16@1+ (0.0078125,-250) [-250|250.992] "deg" Vector__XXX
 SG_ EngCyl16IndctdMeanEffectivePress : 0|16@1+ (0.0001220703125,-1) [-1|6.84362793] "MPa" Vector__XXX

BO_ 2498780414 ECCAI15: 8 Vector__XXX
 SG_ EngCyl15AvrageCombustionDuration : 48|16@1+ (0.0078125,0) [0|501.99] "deg" Vector__XXX
 SG_ EngCyl15AvrgCntrOfCmbstionTiming : 32|16@1+ (0.0078125,-250) [-250|250.992] "deg" Vector__XXX
 SG_ EngCyl15AvrgStrtOfCmbstionTiming : 16|16@1+ (0.0078125,-250) [-250|250.992] "deg" Vector__XXX
 SG_ EngCyl15IndctdMeanEffectivePress : 0|16@1+ (0.0001220703125,-1) [-1|6.84362793] "MPa" Vector__XXX

BO_ 2498780158 ECCAI14: 8 Vector__XXX
 SG_ EngCyl14AvrageCombustionDuration : 48|16@1+ (0.0078125,0) [0|501.99] "deg" Vector__XXX
 SG_ EngCyl14AvrgCntrOfCmbstionTiming : 32|16@1+ (0.0078125,-250) [-250|250.992] "deg" Vector__XXX
 SG_ EngCyl14AvrgStrtOfCmbstionTiming : 16|16@1+ (0.0078125,-250) [-250|250.992] "deg" Vector__XXX
 SG_ EngCyl14IndctdMeanEffectivePress : 0|16@1+ (0.0001220703125,-1) [-1|6.84362793] "MPa" Vector__XXX

BO_ 2498779902 ECCAI13: 8 Vector__XXX
 SG_ EngCyl13AvrageCombustionDuration : 48|16@1+ (0.0078125,0) [0|501.99] "deg" Vector__XXX
 SG_ EngCyl13AvrgCntrOfCmbstionTiming : 32|16@1+ (0.0078125,-250) [-250|250.992] "deg" Vector__XXX
 SG_ EngCyl13AvrgStrtOfCmbstionTiming : 16|16@1+ (0.0078125,-250) [-250|250.992] "deg" Vector__XXX
 SG_ EngCyl13IndctdMeanEffectivePress : 0|16@1+ (0.0001220703125,-1) [-1|6.84362793] "MPa" Vector__XXX

BO_ 2498779646 ECCAI12: 8 Vector__XXX
 SG_ EngCyl12AvrageCombustionDuration : 48|16@1+ (0.0078125,0) [0|501.99] "deg" Vector__XXX
 SG_ EngCyl12AvrgCntrOfCmbstionTiming : 32|16@1+ (0.0078125,-250) [-250|250.992] "deg" Vector__XXX
 SG_ EngCyl12AvrgStrtOfCmbstionTiming : 16|16@1+ (0.0078125,-250) [-250|250.992] "deg" Vector__XXX
 SG_ EngCyl12IndctdMeanEffectivePress : 0|16@1+ (0.0001220703125,-1) [-1|6.84362793] "MPa" Vector__XXX

BO_ 2498779390 ECCAI11: 8 Vector__XXX
 SG_ EngCyl11AvrageCombustionDuration : 48|16@1+ (0.0078125,0) [0|501.99] "deg" Vector__XXX
 SG_ EngCyl11AvrgCntrOfCmbstionTiming : 32|16@1+ (0.0078125,-250) [-250|250.992] "deg" Vector__XXX
 SG_ EngCyl11AvrgStrtOfCmbstionTiming : 16|16@1+ (0.0078125,-250) [-250|250.992] "deg" Vector__XXX
 SG_ EngCyl11IndctdMeanEffectivePress : 0|16@1+ (0.0001220703125,-1) [-1|6.84362793] "MPa" Vector__XXX

BO_ 2498779134 ECCAI10: 8 Vector__XXX
 SG_ EngCyl10AvrageCombustionDuration : 48|16@1+ (0.0078125,0) [0|501.99] "deg" Vector__XXX
 SG_ EngCyl10AvrgCntrOfCmbstionTiming : 32|16@1+ (0.0078125,-250) [-250|250.992] "deg" Vector__XXX
 SG_ EngCyl10AvrgStrtOfCmbstionTiming : 16|16@1+ (0.0078125,-250) [-250|250.992] "deg" Vector__XXX
 SG_ EngCyl10IndctdMeanEffectivePress : 0|16@1+ (0.0001220703125,-1) [-1|6.84362793] "MPa" Vector__XXX

BO_ 2498778878 ECCAI9: 8 Vector__XXX
 SG_ EngCyl9AverageCombustionDuration : 48|16@1+ (0.0078125,0) [0|501.99] "deg" Vector__XXX
 SG_ EngCyl9AvrgCntrOfCmbustionTiming : 32|16@1+ (0.0078125,-250) [-250|250.992] "deg" Vector__XXX
 SG_ EngCyl9AvrgStrtOfCmbustionTiming : 16|16@1+ (0.0078125,-250) [-250|250.992] "deg" Vector__XXX
 SG_ EngCyl9IndctedMeanEffectivePress : 0|16@1+ (0.0001220703125,-1) [-1|6.84362793] "MPa" Vector__XXX

BO_ 2566757118 EBS24: 8 Vector__XXX

BO_ 2559246078 RGE12: 8 Vector__XXX

BO_ 2559180542 RGE24: 8 Vector__XXX

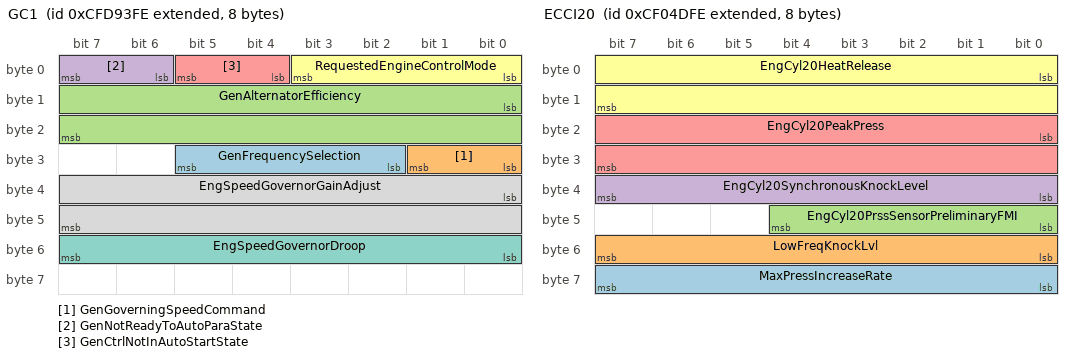
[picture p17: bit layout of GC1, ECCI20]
BO_ 2365428734 GC1: 8 Vector__XXX
 SG_ GenFrequencySelection : 26|4@1+ (1,0) [0|15] "" Vector__XXX
 SG_ GenGoverningSpeedCommand : 24|2@1+ (1,0) [0|3] "" Vector__XXX
 SG_ GenAlternatorEfficiency : 8|16@1+ (0.0025,0) [0|100] "%" Vector__XXX
 SG_ GenNotReadyToAutoParaState : 6|2@1+ (1,0) [0|3] "" Vector__XXX
 SG_ GenCtrlNotInAutoStartState : 4|2@1+ (1,0) [0|3] "" Vector__XXX
 SG_ RequestedEngineControlMode : 0|4@1+ (1,0) [0|15] "" Vector__XXX
 SG_ EngSpeedGovernorDroop : 48|8@1+ (0.04,0) [0|10] "%" Vector__XXX
 SG_ EngSpeedGovernorGainAdjust : 32|16@1+ (1,-32128) [-32128|32127] "" Vector__XXX

BO_ 2566702846 DM57: 8 Vector__XXX
 SG_ EngOBDWarmUpSequence : 0|2@1+ (1,0) [0|3] "" Vector__XXX

BO_ 2566703102 DM56: 208 Vector__XXX
 SG_ CertificationEngineFamilyName : 64|64@1+ (1,0) [0|255] "" Vector__XXX
 SG_ ModelYear : 0|64@1+ (1,0) [0|255] "" Vector__XXX

BO_ 2566705918 DM54: 22 Vector__XXX
 SG_ DTC1 : 16|32@1+ (1,0) [0|4294967295] "" Vector__XXX
 SG_ FlashProtectLamp : 8|2@1+ (1,0) [0|3] "" Vector__XXX
 SG_ FlashAmberWarningLamp : 10|2@1+ (1,0) [0|3] "" Vector__XXX
 SG_ FlashRedStopLamp : 12|2@1+ (1,0) [0|3] "" Vector__XXX
 SG_ FlashMalfuncIndicatorLamp : 14|2@1+ (1,0) [0|3] "" Vector__XXX
 SG_ ProtectLampStatus : 0|2@1+ (1,0) [0|3] "" Vector__XXX
 SG_ AmberWarningLampStatus : 2|2@1+ (1,0) [0|3] "" Vector__XXX
 SG_ RedStopLampState : 4|2@1+ (1,0) [0|3] "" Vector__XXX
 SG_ MalfunctionIndicatorLampStatus : 6|2@1+ (1,0) [0|3] "" Vector__XXX
 SG_ DTC5 : 144|32@1+ (1,0) [0|4294967295] "" Vector__XXX
 SG_ DTC4 : 112|32@1+ (1,0) [0|4294967295] "" Vector__XXX
 SG_ DTC3 : 80|32@1+ (1,0) [0|4294967295] "" Vector__XXX
 SG_ DTC2 : 48|32@1+ (1,0) [0|4294967295] "" Vector__XXX

BO_ 2566705662 DM53: 22 Vector__XXX
 SG_ DTC1 : 16|32@1+ (1,0) [0|4294967295] "" Vector__XXX
 SG_ FlashProtectLamp : 8|2@1+ (1,0) [0|3] "" Vector__XXX
 SG_ FlashAmberWarningLamp : 10|2@1+ (1,0) [0|3] "" Vector__XXX
 SG_ FlashRedStopLamp : 12|2@1+ (1,0) [0|3] "" Vector__XXX
 SG_ FlashMalfuncIndicatorLamp : 14|2@1+ (1,0) [0|3] "" Vector__XXX
 SG_ ProtectLampStatus : 0|2@1+ (1,0) [0|3] "" Vector__XXX
 SG_ AmberWarningLampStatus : 2|2@1+ (1,0) [0|3] "" Vector__XXX
 SG_ RedStopLampState : 4|2@1+ (1,0) [0|3] "" Vector__XXX
 SG_ MalfunctionIndicatorLampStatus : 6|2@1+ (1,0) [0|3] "" Vector__XXX
 SG_ DTC5 : 144|32@1+ (1,0) [0|4294967295] "" Vector__XXX
 SG_ DTC4 : 112|32@1+ (1,0) [0|4294967295] "" Vector__XXX
 SG_ DTC3 : 80|32@1+ (1,0) [0|4294967295] "" Vector__XXX
 SG_ DTC2 : 48|32@1+ (1,0) [0|4294967295] "" Vector__XXX

BO_ 2566706174 DM55: 0 Vector__XXX

BO_ 2349465342 SRASI: 8 Vector__XXX
 SG_ StaticRollAngleStatus : 8|3@1+ (1,0) [0|7] "" Vector__XXX
 SG_ StaticRollAngle : 0|8@1+ (1,-125) [-90|90] "deg" Vector__XXX

BO_ 2498777086 ECCAI2: 8 Vector__XXX
 SG_ EngCyl2AverageCombustionDuration : 48|16@1+ (0.0078125,0) [0|501.99] "deg" Vector__XXX
 SG_ EngCyl2AvrgCntrOfCmbustionTiming : 32|16@1+ (0.0078125,-250) [-250|250.992] "deg" Vector__XXX
 SG_ EngCyl2AvrgStrtOfCmbustionTiming : 16|16@1+ (0.0078125,-250) [-250|250.992] "deg" Vector__XXX
 SG_ EngCyl2IndctedMeanEffectivePress : 0|16@1+ (0.0001220703125,-1) [-1|6.84362793] "MPa" Vector__XXX

BO_ 2498776830 ECCAI1: 8 Vector__XXX
 SG_ EngCyl1AverageCombustionDuration : 48|16@1+ (0.0078125,0) [0|501.99] "deg" Vector__XXX
 SG_ EngCyl1AvrgCntrOfCmbustionTiming : 32|16@1+ (0.0078125,-250) [-250|250.992] "deg" Vector__XXX
 SG_ EngCyl1AvrgStrtOfCmbustionTiming : 16|16@1+ (0.0078125,-250) [-250|250.992] "deg" Vector__XXX
 SG_ EngCyl1IndctedMeanEffectivePress : 0|16@1+ (0.0001220703125,-1) [-1|6.84362793] "MPa" Vector__XXX

BO_ 2364558846 ECCI20: 8 Vector__XXX
 SG_ MaxPressIncreaseRate : 56|8@1+ (16,0) [0|4000] "kPa/deg crank angle" Vector__XXX
 SG_ LowFreqKnockLvl : 48|8@1+ (1,0) [0|250] "%" Vector__XXX
 SG_ EngCyl20PrssSensorPreliminaryFMI : 40|5@1+ (1,0) [0|31] "" Vector__XXX
 SG_ EngCyl20SynchronousKnockLevel : 32|8@1+ (1,0) [0|250] "%" Vector__XXX
 SG_ EngCyl20PeakPress : 16|16@1+ (0.0009765625,0) [0|62.74902344] "MPa" Vector__XXX
 SG_ EngCyl20HeatRelease : 0|16@1+ (0.0001220703125,-1) [-1|6.84362793] "kJ/l" Vector__XXX

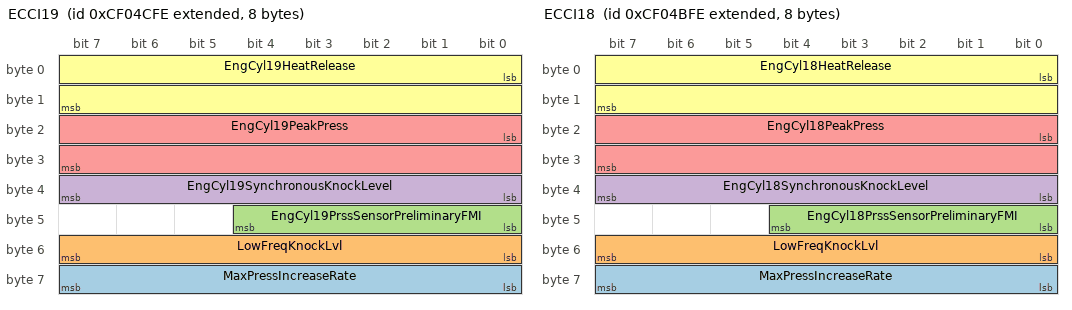
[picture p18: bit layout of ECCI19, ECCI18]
BO_ 2364558590 ECCI19: 8 Vector__XXX
 SG_ MaxPressIncreaseRate : 56|8@1+ (16,0) [0|4000] "kPa/deg crank angle" Vector__XXX
 SG_ LowFreqKnockLvl : 48|8@1+ (1,0) [0|250] "%" Vector__XXX
 SG_ EngCyl19PrssSensorPreliminaryFMI : 40|5@1+ (1,0) [0|31] "" Vector__XXX
 SG_ EngCyl19SynchronousKnockLevel : 32|8@1+ (1,0) [0|250] "%" Vector__XXX
 SG_ EngCyl19PeakPress : 16|16@1+ (0.0009765625,0) [0|62.74902344] "MPa" Vector__XXX
 SG_ EngCyl19HeatRelease : 0|16@1+ (0.0001220703125,-1) [-1|6.84362793] "kJ/l" Vector__XXX

BO_ 2364558334 ECCI18: 8 Vector__XXX
 SG_ MaxPressIncreaseRate : 56|8@1+ (16,0) [0|4000] "kPa/deg crank angle" Vector__XXX
 SG_ LowFreqKnockLvl : 48|8@1+ (1,0) [0|250] "%" Vector__XXX
 SG_ EngCyl18PrssSensorPreliminaryFMI : 40|5@1+ (1,0) [0|31] "" Vector__XXX
 SG_ EngCyl18SynchronousKnockLevel : 32|8@1+ (1,0) [0|250] "%" Vector__XXX
 SG_ EngCyl18PeakPress : 16|16@1+ (0.0009765625,0) [0|62.74902344] "MPa" Vector__XXX
 SG_ EngCyl18HeatRelease : 0|16@1+ (0.0001220703125,-1) [-1|6.84362793] "kJ/l" Vector__XXX

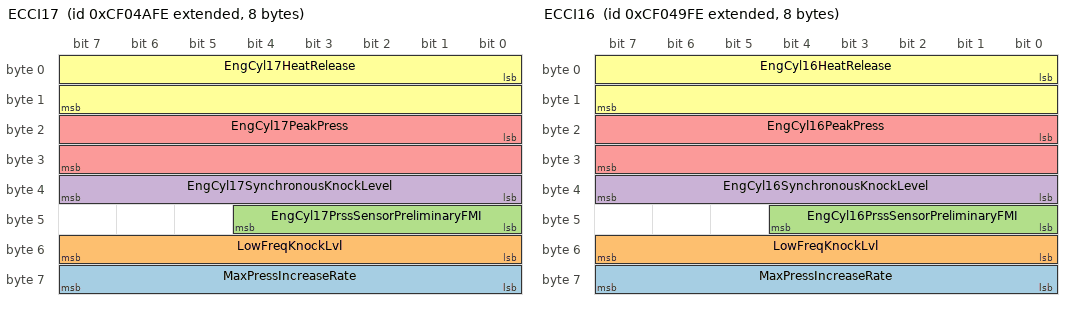
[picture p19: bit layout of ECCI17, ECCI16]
BO_ 2364558078 ECCI17: 8 Vector__XXX
 SG_ MaxPressIncreaseRate : 56|8@1+ (16,0) [0|4000] "kPa/deg crank angle" Vector__XXX
 SG_ LowFreqKnockLvl : 48|8@1+ (1,0) [0|250] "%" Vector__XXX
 SG_ EngCyl17PrssSensorPreliminaryFMI : 40|5@1+ (1,0) [0|31] "" Vector__XXX
 SG_ EngCyl17SynchronousKnockLevel : 32|8@1+ (1,0) [0|250] "%" Vector__XXX
 SG_ EngCyl17PeakPress : 16|16@1+ (0.0009765625,0) [0|62.74902344] "MPa" Vector__XXX
 SG_ EngCyl17HeatRelease : 0|16@1+ (0.0001220703125,-1) [-1|6.84362793] "kJ/l" Vector__XXX

BO_ 2364557822 ECCI16: 8 Vector__XXX
 SG_ MaxPressIncreaseRate : 56|8@1+ (16,0) [0|4000] "kPa/deg crank angle" Vector__XXX
 SG_ LowFreqKnockLvl : 48|8@1+ (1,0) [0|250] "%" Vector__XXX
 SG_ EngCyl16PrssSensorPreliminaryFMI : 40|5@1+ (1,0) [0|31] "" Vector__XXX
 SG_ EngCyl16SynchronousKnockLevel : 32|8@1+ (1,0) [0|250] "%" Vector__XXX
 SG_ EngCyl16PeakPress : 16|16@1+ (0.0009765625,0) [0|62.74902344] "MPa" Vector__XXX
 SG_ EngCyl16HeatRelease : 0|16@1+ (0.0001220703125,-1) [-1|6.84362793] "kJ/l" Vector__XXX

CM_ BO_ 2566697982 "Fused Power Output Current
Fused power output current reports the measured electrical current flowing out of all fused outputs on the Power Distribution Module (PDM).";
CM_ SG_ 2566697982 FusedOutput32Current "Measured electrical current flowing out of Power Distribution Module (PDM) Fused Output #32.";
CM_ SG_ 2566697982 FusedOutput31Current "Measured electrical current flowing out of Power Distribution Module (PDM) Fused Output #31.";
CM_ SG_ 2566697982 FusedOutput30Current "Measured electrical current flowing out of Power Distribution Module (PDM) Fused Output #30.";
CM_ SG_ 2566697982 FusedOutput29Current "Measured electrical current flowing out of Power Distribution Module (PDM) Fused Output #29.";
CM_ SG_ 2566697982 FusedOutput28Current "Measured electrical current flowing out of Power Distribution Module (PDM) Fused Output #28.";
CM_ SG_ 2566697982 FusedOutput27Current "Measured electrical current flowing out of Power Distribution Module (PDM) Fused Output #27.";
CM_ SG_ 2566697982 FusedOutput26Current "Measured electrical current flowing out of Power Distribution Module (PDM) Fused Output #26.";
CM_ SG_ 2566697982 FusedOutput25Current "Measured electrical current flowing out of Power Distribution Module (PDM) Fused Output #25.";
CM_ SG_ 2566697982 FusedOutput24Current "Measured electrical current flowing out of Power Distribution Module (PDM) Fused Output #24.";
CM_ SG_ 2566697982 FusedOutput23Current "Measured electrical current flowing out of Power Distribution Module (PDM) Fused Output #23.";
CM_ SG_ 2566697982 FusedOutput22Current "Measured electrical current flowing out of Power Distribution Module (PDM) Fused Output #22.";
CM_ SG_ 2566697982 FusedOutput21Current "Measured electrical current flowing out of Power Distribution Module (PDM) Fused Output #21.";
CM_ SG_ 2566697982 FusedOutput20Current "Measured electrical current flowing out of Power Distribution Module (PDM) Fused Output #20.";
CM_ SG_ 2566697982 FusedOutput19Current "Measured electrical current flowing out of Power Distribution Module (PDM) Fused Output #19.";
CM_ SG_ 2566697982 FusedOutput18Current "Measured electrical current flowing out of Power Distribution Module (PDM) Fused Output #18.";
CM_ SG_ 2566697982 FusedOutput17Current "Measured electrical current flowing out of Power Distribution Module (PDM) Fused Output #17.";
CM_ SG_ 2566697982 FusedOutput16Current "Measured electrical current flowing out of Power Distribution Module (PDM) Fused Output #16.";
CM_ SG_ 2566697982 FusedOutput15Current "Measured electrical current flowing out of Power Distribution Module (PDM) Fused Output #15.";
CM_ SG_ 2566697982 FusedOutput14Current "Measured electrical current flowing out of Power Distribution Module (PDM) Fused Output #14.";
CM_ SG_ 2566697982 FusedOutput13Current "Measured electrical current flowing out of Power Distribution Module (PDM) Fused Output #13.";
CM_ SG_ 2566697982 FusedOutput12Current "Measured electrical current flowing out of Power Distribution Module (PDM) Fused Output #12.";
CM_ SG_ 2566697982 FusedOutput11Current "Measured electrical current flowing out of Power Distribution Module (PDM) Fused Output #11.";
CM_ SG_ 2566697982 FusedOutput10Current "Measured electrical current flowing out of Power Distribution Module (PDM) Fused Output #10.";
CM_ SG_ 2566697982 FusedOutput9Current "Measured electrical current flowing out of Power Distribution Module (PDM) Fused Output #9.";
CM_ SG_ 2566697982 FusedOutput8Current "Measured electrical current flowing out of Power Distribution Module (PDM) Fused Output #8.";
CM_ SG_ 2566697982 FusedOutput7Current "Measured electrical current flowing out of Power Distribution Module (PDM) Fused Output #7.";
CM_ SG_ 2566697982 FusedOutput6Current "Measured electrical current flowing out of Power Distribution Module (PDM) Fused Output #6.";
CM_ SG_ 2566697982 FusedOutput5Current "Measured electrical current flowing out of Power Distribution Module (PDM) Fused Output #5.";
CM_ SG_ 2566697982 FusedOutput4Current "Measured electrical current flowing out of Power Distribution Module (PDM) Fused Output #4.";
CM_ SG_ 2566697982 FusedOutput3Current "Measured electrical current flowing out of Power Distribution Module (PDM) Fused Output #3.";
CM_ SG_ 2566697982 FusedOutput2Current "Measured electrical current flowing out of Power Distribution Module (PDM) Fused Output #2.";
CM_ SG_ 2566697982 FusedOutput1Current "Measured electrical current flowing out of Power Distribution Module (PDM) Fused Output #1.";
CM_ BO_ 2566697726 "Switched Power Output Current
Switched power output current reports the measured electrical current flowing out of all switched
outputs on the Power Distribution Module (PDM).";
CM_ SG_ 2566697726 SwitchedOutput32Current "Measured electrical current flowing out of Power Distribution Module (PDM) Switched Output #32.";
CM_ SG_ 2566697726 SwitchedOutput31Current "Measured electrical current flowing out of Power Distribution Module (PDM) Switched Output #31.";
CM_ SG_ 2566697726 SwitchedOutput30Current "Measured electrical current flowing out of Power Distribution Module (PDM) Switched Output #30.";
CM_ SG_ 2566697726 SwitchedOutput29Current "Measured electrical current flowing out of Power Distribution Module (PDM) Switched Output #29.";
CM_ SG_ 2566697726 SwitchedOutput28Current "Measured electrical current flowing out of Power Distribution Module (PDM) Switched Output #28.";
CM_ SG_ 2566697726 SwitchedOutput27Current "Measured electrical current flowing out of Power Distribution Module (PDM) Switched Output #27.";
CM_ SG_ 2566697726 SwitchedOutput26Current "Measured electrical current flowing out of Power Distribution Module (PDM) Switched Output #26.";
CM_ SG_ 2566697726 SwitchedOutput25Current "Measured electrical current flowing out of Power Distribution Module (PDM) Switched Output #25.";
CM_ SG_ 2566697726 SwitchedOutput24Current "Measured electrical current flowing out of Power Distribution Module (PDM) Switched Output #24.";
CM_ SG_ 2566697726 SwitchedOutput23Current "Measured electrical current flowing out of Power Distribution Module (PDM) Switched Output #23.";
CM_ SG_ 2566697726 SwitchedOutput22Current "Measured electrical current flowing out of Power Distribution Module (PDM) Switched Output #22.";
CM_ SG_ 2566697726 SwitchedOutput21Current "Measured electrical current flowing out of Power Distribution Module (PDM) Switched Output #21.";
CM_ SG_ 2566697726 SwitchedOutput20Current "Measured electrical current flowing out of Power Distribution Module (PDM) Switched Output #20.";
CM_ SG_ 2566697726 SwitchedOutput19Current "Measured electrical current flowing out of Power Distribution Module (PDM) Switched Output #19.";
CM_ SG_ 2566697726 SwitchedOutput18Current "Measured electrical current flowing out of Power Distribution Module (PDM) Switched Output #18.";
CM_ SG_ 2566697726 SwitchedOutput17Current "Measured electrical current flowing out of Power Distribution Module (PDM) Switched Output #17.";
CM_ SG_ 2566697726 SwitchedOutput16Current "Measured electrical current flowing out of Power Distribution Module (PDM) Switched Output #16.";
CM_ SG_ 2566697726 SwitchedOutput15Current "Measured electrical current flowing out of Power Distribution Module (PDM) Switched Output #15.";
CM_ SG_ 2566697726 SwitchedOutput14Current "Measured electrical current flowing out of Power Distribution Module (PDM) Switched Output #14.";
CM_ SG_ 2566697726 SwitchedOutput13Current "Measured electrical current flowing out of Power Distribution Module (PDM) Switched Output #13.";
CM_ SG_ 2566697726 SwitchedOutput12Current "Measured electrical current flowing out of Power Distribution Module (PDM) Switched Output #12.";
CM_ SG_ 2566697726 SwitchedOutput11Current "Measured electrical current flowing out of Power Distribution Module (PDM) Switched Output #11.";
CM_ SG_ 2566697726 SwitchedOutput10Current "Measured electrical current flowing out of Power Distribution Module (PDM) Switched Output #10.";
CM_ SG_ 2566697726 SwitchedOutput9Current "Measured electrical current flowing out of Power Distribution Module (PDM) Switched Output #9.";
CM_ SG_ 2566697726 SwitchedOutput8Current "Measured electrical current flowing out of Power Distribution Module (PDM) Switched Output #8.";
CM_ SG_ 2566697726 SwitchedOutput7Current "Measured electrical current flowing out of Power Distribution Module (PDM) Switched Output #7.";
CM_ SG_ 2566697726 SwitchedOutput6Current "Measured electrical current flowing out of Power Distribution Module (PDM) Switched Output #6.";
CM_ SG_ 2566697726 SwitchedOutput5Current "Measured electrical current flowing out of Power Distribution Module (PDM) Switched Output #5.";
CM_ SG_ 2566697726 SwitchedOutput4Current "Measured electrical current flowing out of Power Distribution Module (PDM) Switched Output #4.";
CM_ SG_ 2566697726 SwitchedOutput3Current "Measured electrical current flowing out of Power Distribution Module (PDM) Switched Output #3.";
CM_ SG_ 2566697726 SwitchedOutput2Current "Measured electrical current flowing out of Power Distribution Module (PDM) Switched Output #2.";
CM_ SG_ 2566697726 SwitchedOutput1Current "Measured electrical current flowing out of Power Distribution Module (PDM) Switched Output #1.";
CM_ BO_ 2566697470 "Engine Ignition Control Module Status
Contains Operating Status, Control State, and Physical Status of the Engine Ignition Control Module";
CM_ SG_ 2566697470 EngIgntCtrlModule2State "This parameter is used to indicate the current state of Engine Ignition Control Module 2.
000 - Disabled (by user)
001 - Shutdown (due to alarm)
010 - Stalled (waiting for timing signals)
011 - Firing Ignition in Test Mode
100 - Firing Ignition ...";
CM_ SG_ 2566697470 EngIgntCtrlModule1State "This parameter is used to indicate the current state of Engine Ignition Control Module 1.
000 - Disabled (by user)
001 - Shutdown (due to alarm)
010 - Stalled (waiting for timing signals)
011 - Firing Ignition in Test Mode
100 - Firing Ignition ...";
CM_ SG_ 2566697470 EngIgntCtrlModule2Temp "Measured internal temperature of the Engine Ignition Control Module 2 circuitry.";
CM_ SG_ 2566697470 EngIgntCtrlModule1Temp "Measured internal temperature of the Engine Ignition Control Module 1 circuitry.";
CM_ BO_ 2633806078 "Engine Ignition Controller Maintenance Hours
Contains Maintenance Hours of the Engine Ignition Control Module";
CM_ SG_ 2633806078 EngIgntCtrlModule2TimeRemaining "This parameter reports the time remaining before maintenance should be performed on engine ignition control module instance 2.  Upon maintenance, the time is reset to its starting value using Reset PGN 56832, Ignition Control Maintenance Hours ...";
CM_ SG_ 2633806078 EngIgntCtrlModule1TimeRemaining "This parameter reports the time remaining before maintenance should be performed on engine ignition control module instance 1.  Upon maintenance, the time is reset to its starting value using Reset PGN 56832, Ignition Control Maintenance Hours ...";
CM_ BO_ 2633805822 "Engine Spark Minimum Voltage 1
The PGN contains information about minimum spark voltage values for cylinders 1 through 4. This is the secondary voltage of the combustion event.
This PGN may be used together with PGN 64887 which conveys the average ...";
CM_ SG_ 2633805822 EngSparkPlug4MinVoltage "The smallest measured spark voltage of all measured spark events on Cylinder #4 since the last time this tracking data was reset.  It is reset using Reset PGN 56832, Engine Spark Plug Secondary Voltage Tracking Reset SPN 6218.";
CM_ SG_ 2633805822 EngSparkPlug3MinVoltage "The smallest measured spark voltage of all measured spark events on Cylinder #3 since the last time this tracking data was reset.  It is reset using Reset PGN 56832, Engine Spark Plug Secondary Voltage Tracking Reset SPN 6218.";
CM_ SG_ 2633805822 EngSparkPlug2MinVoltage "The smallest measured spark voltage of all measured spark events on Cylinder #2 since the last time this tracking data was reset.  It is reset using Reset PGN 56832, Engine Spark Plug Secondary Voltage Tracking Reset SPN 6218.";
CM_ SG_ 2633805822 EngSparkPlug1MinVoltage "The smallest measured spark voltage of all measured spark events on Cylinder #1 since the last time this tracking data was reset.  It is reset using Reset PGN 56832, Engine Spark Plug Secondary Voltage Tracking Reset SPN 6218.";
CM_ BO_ 2633805566 "Engine Spark Minimum Voltage 2
The PGN contains information about minimum spark voltage values for cylinders 5 through 8. This is the secondary voltage of the combustion event.
This PGN may be used together with PGN 64886 which conveys the average ...";
CM_ SG_ 2633805566 EngSparkPlug8MinVoltage "The smallest measured spark voltage of all measured spark events on Cylinder #8 since the last time this tracking data was reset.  It is reset using Reset PGN 56832, Engine Spark Plug Secondary Voltage Tracking Reset SPN 6218.";
CM_ SG_ 2633805566 EngSparkPlug7MinVoltage "The smallest measured spark voltage of all measured spark events on Cylinder #7 since the last time this tracking data was reset.  It is reset using Reset PGN 56832, Engine Spark Plug Secondary Voltage Tracking Reset SPN 6218.";
CM_ SG_ 2633805566 EngSparkPlug6MinVoltage "The smallest measured spark voltage of all measured spark events on Cylinder #6 since the last time this tracking data was reset.  It is reset using Reset PGN 56832, Engine Spark Plug Secondary Voltage Tracking Reset SPN 6218.";
CM_ SG_ 2633805566 EngSparkPlug5MinVoltage "The smallest measured spark voltage of all measured spark events on Cylinder #5 since the last time this tracking data was reset.  It is reset using Reset PGN 56832, Engine Spark Plug Secondary Voltage Tracking Reset SPN 6218.";
CM_ BO_ 2633805310 "Engine Spark Minimum Voltage 3
The PGN contains information about minimum spark voltage values for cylinders 9 through 12. This is the secondary voltage of the combustion event.
This PGN may be used together with PGN 64885 which conveys the ...";
CM_ SG_ 2633805310 EngSparkPlug12MinVoltage "The smallest measured spark voltage of all measured spark events on Cylinder #12 since the last time this tracking data was reset.  It is reset using Reset PGN 56832, Engine Spark Plug Secondary Voltage Tracking Reset SPN 6218.";
CM_ SG_ 2633805310 EngSparkPlug11MinVoltage "The smallest measured spark voltage of all measured spark events on Cylinder #11 since the last time this tracking data was reset.  It is reset using Reset PGN 56832, Engine Spark Plug Secondary Voltage Tracking Reset SPN 6218.";
CM_ SG_ 2633805310 EngSparkPlug10MinVoltage "The smallest measured spark voltage of all measured spark events on Cylinder #10 since the last time this tracking data was reset.  It is reset using Reset PGN 56832, Engine Spark Plug Secondary Voltage Tracking Reset SPN 6218.";
CM_ SG_ 2633805310 EngSparkPlug9MinVoltage "The smallest measured spark voltage of all measured spark events on Cylinder #9 since the last time this tracking data was reset.  It is reset using Reset PGN 56832, Engine Spark Plug Secondary Voltage Tracking Reset SPN 6218.";
CM_ BO_ 2633805054 "Engine Spark Minimum Voltage 4
The PGN contains information about minimum spark voltage values for cylinders 13 through 16. This is the secondary voltage of the combustion event.
This PGN may be used together with PGN 64884 which conveys the ...";
CM_ SG_ 2633805054 EngSparkPlug16MinVoltage "The smallest measured spark voltage of all measured spark events on Cylinder #16 since the last time this tracking data was reset.  It is reset using Reset PGN 56832, Engine Spark Plug Secondary Voltage Tracking Reset SPN 6218.";
CM_ SG_ 2633805054 EngSparkPlug15MinVoltage "The smallest measured spark voltage of all measured spark events on Cylinder #15 since the last time this tracking data was reset.  It is reset using Reset PGN 56832, Engine Spark Plug Secondary Voltage Tracking Reset SPN 6218.";
CM_ SG_ 2633805054 EngSparkPlug14MinVoltage "The smallest measured spark voltage of all measured spark events on Cylinder #14 since the last time this tracking data was reset.  It is reset using Reset PGN 56832, Engine Spark Plug Secondary Voltage Tracking Reset SPN 6218.";
CM_ SG_ 2633805054 EngSparkPlug13MinVoltage "The smallest measured spark voltage of all measured spark events on Cylinder #13 since the last time this tracking data was reset.  It is reset using Reset PGN 56832, Engine Spark Plug Secondary Voltage Tracking Reset SPN 6218.";
CM_ BO_ 2633804798 "Engine Spark Minimum Voltage 5
The PGN contains information about minimum spark voltage values for cylinders 17 through 20. This is the secondary voltage of the combustion event.
This PGN may be used together with PGN 64883 which conveys the ...";
CM_ SG_ 2633804798 EngSparkPlug20MinVoltage "The smallest measured spark voltage of all measured spark events on Cylinder #20 since the last time this tracking data was reset.  It is reset using Reset PGN 56832, Engine Spark Plug Secondary Voltage Tracking Reset SPN 6218.";
CM_ SG_ 2633804798 EngSparkPlug19MinVoltage "The smallest measured spark voltage of all measured spark events on Cylinder #19 since the last time this tracking data was reset.  It is reset using Reset PGN 56832, Engine Spark Plug Secondary Voltage Tracking Reset SPN 6218.";
CM_ SG_ 2633804798 EngSparkPlug18MinVoltage "The smallest measured spark voltage of all measured spark events on Cylinder #18 since the last time this tracking data was reset.  It is reset using Reset PGN 56832, Engine Spark Plug Secondary Voltage Tracking Reset SPN 6218.";
CM_ SG_ 2633804798 EngSparkPlug17MinVoltage "The smallest measured spark voltage of all measured spark events on Cylinder #17 since the last time this tracking data was reset.  It is reset using Reset PGN 56832, Engine Spark Plug Secondary Voltage Tracking Reset SPN 6218.";
CM_ BO_ 2633804542 "Engine Spark Minimum Voltage 6
The PGN contains information about minimum spark voltage values for cylinders 21 through 24. This is the secondary voltage of the combustion event.
This PGN may be used together with PGN 64882 which conveys the ...";
CM_ SG_ 2633804542 EngSparkPlug24MinVoltage "The smallest measured spark voltage of all measured spark events on Cylinder #24 since the last time this tracking data was reset.  It is reset using Reset PGN 56832, Engine Spark Plug Secondary Voltage Tracking Reset SPN 6218.";
CM_ SG_ 2633804542 EngSparkPlug23MinVoltage "The smallest measured spark voltage of all measured spark events on Cylinder #23 since the last time this tracking data was reset.  It is reset using Reset PGN 56832, Engine Spark Plug Secondary Voltage Tracking Reset SPN 6218.";
CM_ SG_ 2633804542 EngSparkPlug22MinVoltage "The smallest measured spark voltage of all measured spark events on Cylinder #22 since the last time this tracking data was reset.  It is reset using Reset PGN 56832, Engine Spark Plug Secondary Voltage Tracking Reset SPN 6218.";
CM_ SG_ 2633804542 EngSparkPlug21MinVoltage "The smallest measured spark voltage of all measured spark events on Cylinder #21 since the last time this tracking data was reset.  It is reset using Reset PGN 56832, Engine Spark Plug Secondary Voltage Tracking Reset SPN 6218.";
CM_ BO_ 2633804286 "Engine Spark Maximum Voltage 1
The PGN contains information about maximum spark voltage values for cylinders 1 through 4. This is the secondary voltage of the combustion event.
This PGN may be used together with PGN 64887 which conveys the average ...";
CM_ SG_ 2633804286 EngSparkPlug4MaxVoltage "The largest measured spark voltage of all measured spark events on Cylinder #4 since the last time this tracking data was reset.  It is reset using Reset PGN 56832, Engine Spark Plug Secondary Voltage Tracking Reset SPN 6218.";
CM_ SG_ 2633804286 EngSparkPlug3MaxVoltage "The largest measured spark voltage of all measured spark events on Cylinder #3 since the last time this tracking data was reset.  It is reset using Reset PGN 56832, Engine Spark Plug Secondary Voltage Tracking Reset SPN 6218.";
CM_ SG_ 2633804286 EngSparkPlug2MaxVoltage "The largest measured spark voltage of all measured spark events on Cylinder #2 since the last time this tracking data was reset.  It is reset using Reset PGN 56832, Engine Spark Plug Secondary Voltage Tracking Reset SPN 6218.";
CM_ SG_ 2633804286 EngSparkPlug1MaxVoltage "The largest measured spark voltage of all measured spark events on Cylinder #1 since the last time this tracking data was reset.  It is reset using Reset PGN 56832, Engine Spark Plug Secondary Voltage Tracking Reset SPN 6218.";
CM_ BO_ 2633804030 "Engine Spark Maximum Voltage 2
The PGN contains information about maximum spark voltage values for cylinders 5 through 8. This is the secondary voltage of the combustion event.
This PGN may be used together with PGN 64886 which conveys the average ...";
CM_ SG_ 2633804030 EngSparkPlug8MaxVoltage "The largest measured spark voltage of all measured spark events on Cylinder #8 since the last time this tracking data was reset.  It is reset using Reset PGN 56832, Engine Spark Plug Secondary Voltage Tracking Reset SPN 6218.";
CM_ SG_ 2633804030 EngSparkPlug7MaxVoltage "The largest measured spark voltage of all measured spark events on Cylinder #7 since the last time this tracking data was reset.  It is reset using Reset PGN 56832, Engine Spark Plug Secondary Voltage Tracking Reset SPN 6218.";
CM_ SG_ 2633804030 EngSparkPlug6MaxVoltage "The largest measured spark voltage of all measured spark events on Cylinder #6 since the last time this tracking data was reset.  It is reset using Reset PGN 56832, Engine Spark Plug Secondary Voltage Tracking Reset SPN 6218.";
CM_ SG_ 2633804030 EngSparkPlug5MaxVoltage "The largest measured spark voltage of all measured spark events on Cylinder #5 since the last time this tracking data was reset.  It is reset using Reset PGN 56832, Engine Spark Plug Secondary Voltage Tracking Reset SPN 6218.";
CM_ BO_ 2633803774 "Engine Spark Maximum Voltage 3
The PGN contains information about maximum spark voltage values for cylinders 9 through 12. This is the secondary voltage of the combustion event.
This PGN may be used together with PGN 64885 which conveys the ...";
CM_ SG_ 2633803774 EngSparkPlug12MaxVoltage "The largest measured spark voltage of all measured spark events on Cylinder #12 since the last time this tracking data was reset.  It is reset using Reset PGN 56832, Engine Spark Plug Secondary Voltage Tracking Reset SPN 6218.";
CM_ SG_ 2633803774 EngSparkPlug11MaxVoltage "The largest measured spark voltage of all measured spark events on Cylinder #11 since the last time this tracking data was reset.  It is reset using Reset PGN 56832, Engine Spark Plug Secondary Voltage Tracking Reset SPN 6218.";
CM_ SG_ 2633803774 EngSparkPlug10MaxVoltage "The largest measured spark voltage of all measured spark events on Cylinder #10 since the last time this tracking data was reset.  It is reset using Reset PGN 56832, Engine Spark Plug Secondary Voltage Tracking Reset SPN 6218.";
CM_ SG_ 2633803774 EngSparkPlug9MaxVoltage "The largest measured spark voltage of all measured spark events on Cylinder #9 since the last time this tracking data was reset.  It is reset using Reset PGN 56832, Engine Spark Plug Secondary Voltage Tracking Reset SPN 6218.";
CM_ BO_ 2633803518 "Engine Spark Maximum Voltage 4
The PGN contains information about maximum spark voltage values for cylinders 13 through 16.
This is the secondary voltage of the combustion event.
This PGN may be used together with PGN 64884 which conveys the ...";
CM_ SG_ 2633803518 EngSparkPlug16MaxVoltage "The largest measured spark voltage of all measured spark events on Cylinder #16 since the last time this tracking data was reset.  It is reset using Reset PGN 56832, Engine Spark Plug Secondary Voltage Tracking Reset SPN 6218.";
CM_ SG_ 2633803518 EngSparkPlug15MaxVoltage "The largest measured spark voltage of all measured spark events on Cylinder #15 since the last time this tracking data was reset.  It is reset using Reset PGN 56832, Engine Spark Plug Secondary Voltage Tracking Reset SPN 6218.";
CM_ SG_ 2633803518 EngSparkPlug14MaxVoltage "The largest measured spark voltage of all measured spark events on Cylinder #14 since the last time this tracking data was reset.  It is reset using Reset PGN 56832, Engine Spark Plug Secondary Voltage Tracking Reset SPN 6218.";
CM_ SG_ 2633803518 EngSparkPlug13MaxVoltage "The largest measured spark voltage of all measured spark events on Cylinder #13 since the last time this tracking data was reset.  It is reset using Reset PGN 56832, Engine Spark Plug Secondary Voltage Tracking Reset SPN 6218.";
CM_ BO_ 2633803262 "Engine Spark Maximum Voltage 5
The PGN contains information about maximum spark voltage values for cylinders 17 through 20.
This is the secondary voltage of the combustion event.
This PGN may be used together with PGN 64883 which conveys the ...";
CM_ SG_ 2633803262 EngSparkPlug20MaxVoltage "The largest measured spark voltage of all measured spark events on Cylinder #20 since the last time this tracking data was reset.  It is reset using Reset PGN 56832, Engine Spark Plug Secondary Voltage Tracking Reset SPN 6218.";
CM_ SG_ 2633803262 EngSparkPlug19MaxVoltage "The largest measured spark voltage of all measured spark events on Cylinder #19 since the last time this tracking data was reset.  It is reset using Reset PGN 56832, Engine Spark Plug Secondary Voltage Tracking Reset SPN 6218.";
CM_ SG_ 2633803262 EngSparkPlug18MaxVoltage "The largest measured spark voltage of all measured spark events on Cylinder #18 since the last time this tracking data was reset.  It is reset using Reset PGN 56832, Engine Spark Plug Secondary Voltage Tracking Reset SPN 6218.";
CM_ SG_ 2633803262 EngSparkPlug17MaxVoltage "The largest measured spark voltage of all measured spark events on Cylinder #17 since the last time this tracking data was reset.  It is reset using Reset PGN 56832, Engine Spark Plug Secondary Voltage Tracking Reset SPN 6218.";
CM_ BO_ 2633803006 "Engine Spark Maximum Voltage 6
The PGN contains information about maximum spark voltage values for cylinders 21 through 24.
This is the secondary voltage of the combustion event.
This PGN may be used together with PGN 64882 which conveys the ...";
CM_ SG_ 2633803006 EngSparkPlug24MaxVoltage "The largest measured spark voltage of all measured spark events on Cylinder #24 since the last time this tracking data was reset.  It is reset using Reset PGN 56832, Engine Spark Plug Secondary Voltage Tracking Reset SPN 6218.";
CM_ SG_ 2633803006 EngSparkPlug23MaxVoltage "The largest measured spark voltage of all measured spark events on Cylinder #23 since the last time this tracking data was reset.  It is reset using Reset PGN 56832, Engine Spark Plug Secondary Voltage Tracking Reset SPN 6218.";
CM_ SG_ 2633803006 EngSparkPlug22MaxVoltage "The largest measured spark voltage of all measured spark events on Cylinder #22 since the last time this tracking data was reset.  It is reset using Reset PGN 56832, Engine Spark Plug Secondary Voltage Tracking Reset SPN 6218.";
CM_ SG_ 2633803006 EngSparkPlug21MaxVoltage "The largest measured spark voltage of all measured spark events on Cylinder #21 since the last time this tracking data was reset.  It is reset using Reset PGN 56832, Engine Spark Plug Secondary Voltage Tracking Reset SPN 6218.";
CM_ BO_ 2633802750 "Engine Spark Misfire Rate 1
The PGN contains information about spark misfire rate for cylinders 1 through 8. The misfire rate is conveyed as the number of cylinder spark misfires divided by the number of in spark ignition events on the same ...";
CM_ SG_ 2633802750 EngSparkPlug8MisfireRate "The spark misfire rate for Cylinder #8. The misfire rate is conveyed as the percentage of total cylinder spark misfires compared to the total number of ignition events on Cylinder #8 since the last time this tracking data was reset.  Any averaging ...";
CM_ SG_ 2633802750 EngSparkPlug7MisfireRate "The spark misfire rate for Cylinder #7. The misfire rate is conveyed as the percentage of total cylinder spark misfires compared to the total number of ignition events on Cylinder #7 since the last time this tracking data was reset.  Any averaging ...";
CM_ SG_ 2633802750 EngSparkPlug6MisfireRate "The spark misfire rate for Cylinder #6. The misfire rate is conveyed as the percentage of total cylinder spark misfires compared to the total number of ignition events on Cylinder #6 since the last time this tracking data was reset.  Any averaging ...";
CM_ SG_ 2633802750 EngSparkPlug5MisfireRate "The spark misfire rate for Cylinder #5. The misfire rate is conveyed as the percentage of total cylinder spark misfires compared to the total number of ignition events on Cylinder #5 since the last time this tracking data was reset.  Any averaging ...";
CM_ SG_ 2633802750 EngSparkPlug4MisfireRate "The spark misfire rate for Cylinder #4. The misfire rate is conveyed as the percentage of total cylinder spark misfires compared to the total number of ignition events on Cylinder #4 since the last time this tracking data was reset.  Any averaging ...";
CM_ SG_ 2633802750 EngSparkPlug3MisfireRate "The spark misfire rate for Cylinder #3. The misfire rate is conveyed as the percentage of total cylinder spark misfires compared to the total number of ignition events on Cylinder #3 since the last time this tracking data was reset.  Any averaging ...";
CM_ SG_ 2633802750 EngSparkPlug2MisfireRate "The spark misfire rate for Cylinder #2. The misfire rate is conveyed as the percentage of total cylinder spark misfires compared to the total number of ignition events on Cylinder #2 since the last time this tracking data was reset.  Any averaging ...";
CM_ SG_ 2633802750 EngSparkPlug1MisfireRate "The spark misfire rate for Cylinder #1. The misfire rate is conveyed as the percentage of total cylinder spark misfires compared to the total number of ignition events on Cylinder #1 since the last time this tracking data was reset.  Any averaging ...";
CM_ BO_ 2633802494 "Engine Spark Misfire Rate 2
The PGN contains information about spark misfire rate for cylinders 9 through 16. The misfire rate is conveyed as the number of cylinder spark misfires divided by the number of in spark ignition events on the same ...";
CM_ SG_ 2633802494 EngSparkPlug16MisfireRate "The spark misfire rate for Cylinder #16. The misfire rate is conveyed as the percentage of total cylinder spark misfires compared to the total number of ignition events on Cylinder #16 since the last time this tracking data was reset.  Any averaging ...";
CM_ SG_ 2633802494 EngSparkPlug15MisfireRate "The spark misfire rate for Cylinder #15. The misfire rate is conveyed as the percentage of total cylinder spark misfires compared to the total number of ignition events on Cylinder #15 since the last time this tracking data was reset.  Any averaging ...";
CM_ SG_ 2633802494 EngSparkPlug14MisfireRate "The spark misfire rate for Cylinder #14. The misfire rate is conveyed as the percentage of total cylinder spark misfires compared to the total number of ignition events on Cylinder #14 since the last time this tracking data was reset.  Any averaging ...";
CM_ SG_ 2633802494 EngSparkPlug13MisfireRate "The spark misfire rate for Cylinder #13. The misfire rate is conveyed as the percentage of total cylinder spark misfires compared to the total number of ignition events on Cylinder #13 since the last time this tracking data was reset.  Any averaging ...";
CM_ SG_ 2633802494 EngSparkPlug12MisfireRate "The spark misfire rate for Cylinder #12. The misfire rate is conveyed as the percentage of total cylinder spark misfires compared to the total number of ignition events on Cylinder #12 since the last time this tracking data was reset.  Any averaging ...";
CM_ SG_ 2633802494 EngSparkPlug11MisfireRate "The spark misfire rate for Cylinder #11. The misfire rate is conveyed as the percentage of total cylinder spark misfires compared to the total number of ignition events on Cylinder #11 since the last time this tracking data was reset.  Any averaging ...";
CM_ SG_ 2633802494 EngSparkPlug10MisfireRate "The spark misfire rate for Cylinder #10. The misfire rate is conveyed as the percentage of total cylinder spark misfires compared to the total number of ignition events on Cylinder #10 since the last time this tracking data was reset.  Any averaging ...";
CM_ SG_ 2633802494 EngSparkPlug9MisfireRate "The spark misfire rate for Cylinder #9. The misfire rate is conveyed as the percentage of total cylinder spark misfires compared to the total number of ignition events on Cylinder #9 since the last time this tracking data was reset.  Any averaging ...";
CM_ BO_ 2633802238 "Engine Spark Misfire Rate 3
The PGN contains information about spark misfire rate for cylinders 17 through 24. The misfire rate is conveyed as the number of cylinder spark misfires divided by the number of in spark ignition events on the same ...";
CM_ SG_ 2633802238 EngSparkPlug24MisfireRate "The spark misfire rate for Cylinder #24. The misfire rate is conveyed as the percentage of total cylinder spark misfires compared to the total number of ignition events on Cylinder #24 since the last time this tracking data was reset.  Any averaging ...";
CM_ SG_ 2633802238 EngSparkPlug23MisfireRate "The spark misfire rate for Cylinder #23. The misfire rate is conveyed as the percentage of total cylinder spark misfires compared to the total number of ignition events on Cylinder #23 since the last time this tracking data was reset.  Any averaging ...";
CM_ SG_ 2633802238 EngSparkPlug22MisfireRate "The spark misfire rate for Cylinder #22. The misfire rate is conveyed as the percentage of total cylinder spark misfires compared to the total number of ignition events on Cylinder #22 since the last time this tracking data was reset.  Any averaging ...";
CM_ SG_ 2633802238 EngSparkPlug21MisfireRate "The spark misfire rate for Cylinder #21. The misfire rate is conveyed as the percentage of total cylinder spark misfires compared to the total number of ignition events on Cylinder #21 since the last time this tracking data was reset.  Any averaging ...";
CM_ SG_ 2633802238 EngSparkPlug20MisfireRate "The spark misfire rate for Cylinder #20. The misfire rate is conveyed as the percentage of total cylinder spark misfires compared to the total number of ignition events on Cylinder #20 since the last time this tracking data was reset.  Any averaging ...";
CM_ SG_ 2633802238 EngSparkPlug19MisfireRate "The spark misfire rate for Cylinder #19. The misfire rate is conveyed as the percentage of total cylinder spark misfires compared to the total number of ignition events on Cylinder #19 since the last time this tracking data was reset.  Any averaging ...";
CM_ SG_ 2633802238 EngSparkPlug18MisfireRate "The spark misfire rate for Cylinder #18. The misfire rate is conveyed as the percentage of total cylinder spark misfires compared to the total number of ignition events on Cylinder #18 since the last time this tracking data was reset.  Any averaging ...";
CM_ SG_ 2633802238 EngSparkPlug17MisfireRate "The spark misfire rate for Cylinder #17. The misfire rate is conveyed as the percentage of total cylinder spark misfires compared to the total number of ignition events on Cylinder #17 since the last time this tracking data was reset.  Any averaging ...";
CM_ BO_ 2633801982 "Multi-fuel Engine Hours
Engine hours parameters for multi-fuel engines";
CM_ SG_ 2633801982 EngTtlHoursOfDieselFuelOperation "Accumulated time of operation of engine when diesel fuel is used.  This parameter should be used only in multi-fuel engines.  See SPN 247 for single fuel engines and for total hours for multi-fuel engines.";
CM_ SG_ 2633801982 EngTotalHoursOfGasFuelOperation "Accumulated time of operation of engine when gaseous fuel is used.  This parameter should be used only in multi-fuel engines.  See SPN 247 for single fuel engines and for total hours for multi-fuel engines.";
CM_ BO_ 2566692862 "Dash Display 2
Dash Display for Status Information";
CM_ SG_ 2566692862 DisplayRemainPowered "Indicates the ECU needs the display (i.e. monitor device) to continue to remain powered after ignition key off. An ECU would use this when the ECU needs the display to remain powered after key off so the ECU can communicate to the operator while the ...";
CM_ SG_ 2566692862 Fuel2Tank4Level "Fuel level in tank 4 containing the second fuel type.";
CM_ SG_ 2566692862 Fuel2Tank3Level "Fuel level in tank 3 containing the second fuel type.";
CM_ SG_ 2566692862 Fuel2Tank2Level "Fuel level in tank 2 containing the second fuel type.";
CM_ SG_ 2566692862 Fuel2Tank1Level "Fuel level in tank 1 containing the second fuel type.
.";
CM_ SG_ 2566692862 EngExRangeOilFilterDiffPress "Change in engine oil differential pressure measured across the oil filter element. The differential pressure is the measured as the pressure at the filter intake with respect to the pressure at the filter outlet. This differential pressure ...";
CM_ BO_ 2499583742 "Engine Timing Actuator Position
Used to transmit position information of Engine Timing actuator 1 and 2";
CM_ SG_ 2499583742 EngTimingActuator2RequestedPos "The requested position of actuator 2 on the Engine Timing System, as determined by external system such as operator, monitoring or protection system. Requested position is sent to the Control Module sending the command the Engine Timing System ...";
CM_ SG_ 2499583742 EngTimingActuator1RequestedPos "The requested position of actuator 1 on the Engine Timing System, as determined by external system such as operator, monitoring, or protection system. Requested position is sent to the Control Module sending the command the Engine Timing System ...";
CM_ SG_ 2499583742 EngTimingActuator2 "The detected position of actuator 2 on the Engine Timing System, where the system has different timing positions depending on current operating status of the engine. Timing positions may be used to determine intake and outlet valve timings.
000 - ...";
CM_ SG_ 2499583742 EngTimingActuator1 "The detected position of actuator 1 on the Engine Timing System, where the system has different timing positions depending on current operating status of the engine. Timing positions may be used to determine intake and outlet valve timings.
000 - ...";
CM_ BO_ 2499583486 "Engine Timing Actuator Position Command
Used to trasmit the commanded position of Engine Timing actuator 1 and 2.";
CM_ SG_ 2499583486 EngTimingActuator2PosCmd "The commanded position of actuator 2 on the engine timing system by Engine Control Module.  The engine timing system has different timing positions and the timing positions may be used to determine intake and outlet valve timings.
000 - Reserved
 ...";
CM_ SG_ 2499583486 EngTimingActuator1PosCmd "The commanded position of actuator 1 on the engine timing system by Engine Control Module.  The engine timing system has different timing positions and the timing positions may be used to determine intake and outlet valve timings.
000 - Reserved
 ...";
CM_ BO_ 2566692094 "Joystick 1 Lamp Status
Feedback message to report the actual status of lamps on Joystick 1";
CM_ SG_ 2566692094 Joystick1Lamp10Status "Report the actual value of Joystick 1 Lamp 10

00 - Off
01 - On
10 - Flashing
11 - Not available";
CM_ SG_ 2566692094 Joystick1Lamp9Status "Report the actual value of Joystick 1 Lamp 9

00 - Off
01 - On
10 - Flashing
11 - Not available";
CM_ SG_ 2566692094 Joystick1Lamp8Status "Report the actual value of Joystick 1 Lamp 8

00 - Off
01 - On
10 - Flashing
11 - Not available";
CM_ SG_ 2566692094 Joystick1Lamp7Status "Report the actual value of Joystick 1 Lamp 7

00 - Off
01 - On
10 - Flashing
11 - Not available";
CM_ SG_ 2566692094 Joystick1Lamp6Status "Report the actual value of Joystick 1 Lamp 6

00 - Off
01 - On
10 - Flashing
11 - Not available";
CM_ SG_ 2566692094 Joystick1Lamp5Status "Report the actual value of Joystick 1 Lamp 5

00 - Off
01 - On
10 - Flashing
11 - Not available";
CM_ SG_ 2566692094 Joystick1Lamp4Status "Report the actual value of Joystick 1 Lamp 4

00 - Off
01 - On
10 - Flashing
11 - Not available";
CM_ SG_ 2566692094 Joystick1Lamp3Status "Report the actual value of Joystick 1 Lamp 3

00 - Off
01 - On
10 - Flashing
11 - Not available";
CM_ SG_ 2566692094 Joystick1Lamp2Status "Report the actual value of Joystick 1 Lamp 2

00 - Off
01 - On
10 - Flashing
11 - Not available";
CM_ SG_ 2566692094 Joystick1Lamp1Status "Report the actual value of Joystick 1 Lamp 1

00 - Off
01 - On
10 - Flashing
11 - Not available";
CM_ BO_ 2566691838 "Joystick 2 Lamp Status
Feedback message to report the actual status of lamps on Joystick 2";
CM_ SG_ 2566691838 Joystick2Lamp10Status "Report the actual value of Joystick 2 Lamp 10

00 - Off
01 - On
10 - Flashing
11 - Not available";
CM_ SG_ 2566691838 Joystick2Lamp9Status "Report the actual value of Joystick 2 Lamp 9

00 - Off
01 - On
10 - Flashing
11 - Not available";
CM_ SG_ 2566691838 Joystick2Lamp8Status "Report the actual value of Joystick 2 Lamp 8

00 - Off
01 - On
10 - Flashing
11 - Not available";
CM_ SG_ 2566691838 Joystick2Lamp7Status "Report the actual value of Joystick 2 Lamp 7

00 - Off
01 - On
10 - Flashing
11 - Not available";
CM_ SG_ 2566691838 Joystick2Lamp6Status "Report the actual value of Joystick 2 Lamp 6

00 - Off
01 - On
10 - Flashing
11 - Not available";
CM_ SG_ 2566691838 Joystick2Lamp5Status "Report the actual value of Joystick 2 Lamp 5

00 - Off
01 - On
10 - Flashing
11 - Not available";
CM_ SG_ 2566691838 Joystick2Lamp4Status "Report the actual value of Joystick 2 Lamp 4

00 - Off
01 - On
10 - Flashing
11 - Not available";
CM_ SG_ 2566691838 Joystick2Lamp3Status "Report the actual value of Joystick 2 Lamp 3

00 - Off
01 - On
10 - Flashing
11 - Not available";
CM_ SG_ 2566691838 Joystick2Lamp2Status "Report the actual value of Joystick 2 Lamp 2

00 - Off
01 - On
10 - Flashing
11 - Not available";
CM_ SG_ 2566691838 Joystick2Lamp1Status "Report the actual value of Joystick 2 Lamp 1

00 - Off
01 - On
10 - Flashing
11 - Not available";
CM_ BO_ 2566691582 "Joystick 3 Lamp Status
Feedback message to report the actual status of lamps on Joystick 3";
CM_ SG_ 2566691582 Joystick3Lamp10Status "Report the actual value of Joystick 3 Lamp 10

00 - Off
01 - On
10 - Flashing
11 - Not available";
CM_ SG_ 2566691582 Joystick3Lamp9Status "Report the actual value of Joystick 3 Lamp 9

00 - Off
01 - On
10 - Flashing
11 - Not available";
CM_ SG_ 2566691582 Joystick3Lamp8Status "Report the actual value of Joystick 3 Lamp 8

00 - Off
01 - On
10 - Flashing
11 - Not available";
CM_ SG_ 2566691582 Joystick3Lamp7Status "Report the actual value of Joystick 3 Lamp 7

00 - Off
01 - On
10 - Flashing
11 - Not available";
CM_ SG_ 2566691582 Joystick3Lamp6Status "Report the actual value of Joystick 3 Lamp 6

00 - Off
01 - On
10 - Flashing
11 - Not available";
CM_ SG_ 2566691582 Joystick3Lamp5Status "Report the actual value of Joystick 3 Lamp 5

00 - Off
01 - On
10 - Flashing
11 - Not available";
CM_ SG_ 2566691582 Joystick3Lamp4Status "Report the actual value of Joystick 3 Lamp 4

00 - Off
01 - On
10 - Flashing
11 - Not available";
CM_ SG_ 2566691582 Joystick3Lamp3Status "Report the actual value of Joystick 3 Lamp 3

00 - Off
01 - On
10 - Flashing
11 - Not available";
CM_ SG_ 2566691582 Joystick3Lamp2Status "Report the actual value of Joystick 3 Lamp 2

00 - Off
01 - On
10 - Flashing
11 - Not available";
CM_ SG_ 2566691582 Joystick3Lamp1Status "Report the actual value of Joystick 3 Lamp 1

00 - Off
01 - On
10 - Flashing
11 - Not available";
CM_ BO_ 2566691326 "Assembly Unit Identification
Used to transmit the identification of the assemblies fitted onto a component.
NOTE - The assembly unit identification field is variable in length. An ASCII “*” is used as a delimiter to separate multiple ...";
CM_ SG_ 2566691326 AssemblyUnitIdentification "A combination of alphanumeric characters representing the Identification number of an assembly unit installed on a component.  Multiple assembly unit IDs can be transmitted by appropriately setting Number of Assembly Unit Identification Fields (SPN ...";
CM_ SG_ 2566691326 NmbrOfAssmblyUntIdntfctionFields "Number of Assembly Unit Identification designators represented in the Assembly Unit Identification parameter group.";
CM_ BO_ 2499582206 "Vehicle Speed Limiter
Vehicle speed limiter information, including Soft Top Speed Limit information";
CM_ SG_ 2499582206 SftTpSpdLmtRmnngCntnsIntrvlDstnc "Indicates the remaining distance that the vehicle can continuously travel at the Soft Top Speed Limit.  This parameter will decrement while the Soft Top Speed Limit Active (SPN 6370) is 1 and will reset to its maximum allowed value when the Soft Top ...";
CM_ SG_ 2499582206 SoftTopSpeedLimitResetDistance "This parameter will decrement as long as the vehicle is moving. When this parameter reaches 0, it will be reset to its maximum value and continue to decrement.";
CM_ SG_ 2499582206 SftTpSpeedLimitRemainingDistance "Indicates the remaining distance that the vehicle can travel at the Soft Top Speed Limit within the larger reset window. The reset window may be distance (possibly indicated by SPN 6373), time, or something else as determined by the manufacturer.
 ...";
CM_ SG_ 2499582206 SoftTopLifetimeLimitExceeded "Greenhouse Gas Regulations limit the overall distance that Soft Top Speed can be used in relation to the total distance traveled. This parameter indicates the allowable ratio has been exceeded and Soft Top Speed is unavailable. It will become ...";
CM_ SG_ 2499582206 SoftTopSpeedLimitActive "Indicates that the current Maximum Vehicle Speed Limit (SPN 74) has been temporarily increased to the Soft Top Speed Limit. Under certain conditions, the legal speed limit allowed by the Greenhouse Gas Regulations can be increased to a speed ...";
CM_ BO_ 2566690814 "Electronic Steering Control 2
Group containing parameters relevant to the electronic control of an all wheel steering system, allowing the selection and actuation of different steer modes";
CM_ SG_ 2566690814 CrabSteerModeActuatorState "Signal which indicates the current state of the actuator that control the crab steering mode

00 - Crab Steer Mode actuator inactive
01 - Crab Steer Mode actuator active
10 - Error
11 - Not Available";
CM_ SG_ 2566690814 CircleSteerModeActuatorState "Signal which indicates the current state of the actuator that control the circle steering mode

00 - Circle Steer Mode actuator inactive
01 - Circle Steer Mode actuator active
10 - Error
11 - Not Available";
CM_ SG_ 2566690814 VourWheelSteerActuatorState "Signal which indicates the current state of the actuator that control the 4 wheel steering mode

00 - 4 Wheel Steer actuator inactive
01 - 4 Wheel Steer actuator active
10 - Error
11 - Not Available";
CM_ SG_ 2566690814 TwoWheelSteerActuatorState "The current state of the actuator that control the 2 wheel steering mode

00 - 2 Wheel Steer actuator inactive
01 - 2 Wheel Steer actuator active
10 - Error
11 - Not Available";
CM_ SG_ 2566690814 RearSteerAxleCenteredStatus "The status of the rear steering axle being centered. The axle is centered if the axle's centerline is parallel to the vehicle's X-axis, where the vehicle's X-axis is as defined in SAE J670
00 - Rear Axle Centered
01 - Rear Axle Not Centered
10 - ...";
CM_ SG_ 2566690814 FrontSteerAxleCenteredStatus "The status of the front steering axle being centered. The axle is centered if the axle's centerline is parallel to the vehicle's X-axis, where the vehicle's X-axis is as defined in SAE J670
00 - Front Axle Centered
01 - Front Axle Not Centered
10 ...";
CM_ SG_ 2566690814 SteerModeSwitch "Switch used as an input to the electronic steering controller to determine the operator's requested steering mode
000 - 2 Wheel Steer Mode
001 - Circle Steer Mode
011 - Crab Steer Mode
100-101 - Reserved for future use
110 - Error
111 - Not ...";
CM_ BO_ 2566690558 "Engine Information 2
Second PGN conveying engine information.";
CM_ SG_ 2566690558 CommonRailOilAbsPress "Absolute pressure of oil in common rail's lubrication system as provided by oil pump.";
CM_ SG_ 2566690558 CommonRailOilPress "Gage pressure of oil in common rail's lubrication system as provided by oil pump.";
CM_ SG_ 2566690558 EngPreFilterOilPress "Gage pressure of the engine oil before the oil reaches the oil filter. See SPN 1208 for alternate resolution.";
CM_ SG_ 2566690558 EngExhaustPress1ExRange "Gage pressure of the exhaust gasses as measured at the turbine intake of the turbocharger. This SPN to be used for inline engines or exhaust bank 1 of multiple bank engines.  

See SPN 1209 for alternate resolution.";
CM_ BO_ 2365363710 "Engine Cylinder Pressure Monitor Status Information
Used to trasmit the status information of Cylinder Pressure Monitor Unit.";
CM_ SG_ 2365363710 EngCylPrssMonitor2PreliminaryFMI "Used to identify the applicable J1939-73 FMI detected in the Engine Cylinder Pressure Monitor 2.  When there is no failure FMI 31 is sent. In the case of multiple failures the most severe is communicated.";
CM_ SG_ 2365363710 EngCylPrssMonitor1PreliminaryFMI "Used to identify the applicable J1939-73 FMI detected in the Engine Cylinder Pressure Monitor 1.  When there is no failure FMI 31 is sent. In the case of multiple failures the most severe is communicated.";
CM_ BO_ 2566690046 "Aftertreatment System Abuse Information
Current status of aftertreatment system cooldown and purge routines.";
CM_ SG_ 2566690046 AfterrunCompleteThisCycle "Indication of after-run routine completion in the current power cycle.
\"Complete This Cycle\" parameters are used to indicate to the engine controller that is powering the aftertreatment controller via relay that it is ok to remove power.
00 - Not ...";
CM_ SG_ 2566690046 DEFDoserPurgeCompleteLastCycle "Indication of purge routine completion in the previous power cycle
00 - Not complete
01 - Complete
10 - Error
11 - Not Supported
Note:  One purpose for tracking the status of the Diesel Exhaust Fluid doser purge on the previous cycle is related ...";
CM_ SG_ 2566690046 DEFDoserPurgeCompleteThisCycle "Indication of purge routine completion in the current power cycle.
\"Complete This Cycle\" parameters are used to indicate to the engine controller that is powering the aftertreatment controller via relay that it is ok to remove power.
00 - Not ...";
CM_ SG_ 2566690046 DEFDoserCldnCompleteLastCycle "Indication of cooldown routine completion in the previous power cycle.
00 - Not complete
01 - Complete
10 - Error
11 - Not Supported
Note:  One purpose for tracking the status of the Diesel Exhaust Fluid doser purge on the previous cycle is ...";
CM_ SG_ 2566690046 DEFDoserCldnCompleteThisCycle "Indication of cooldown routine completion in the current power cycle.
\"Complete This Cycle\" parameters are used to indicate to the engine controller that is powering the aftertreatment controller via relay that it is ok to remove power.
00 - Not ...";
CM_ SG_ 2566690046 DEFDoserPurgeInterruptCount "Non-volatile record of the number of interrupted purge routines since the last clear event.  The counter shall be reset by PGN 56832 request.";
CM_ SG_ 2566690046 DEFDoserCldnInterruptCount "Non-volatile record of the number of interrupted cooldown routines since the last clear event.  The counter shall be reset by PGN 56832 request.";
CM_ BO_ 2566689790 "Gaseous Fuel Pressure 2
Information on Gas fuel pressure";
CM_ SG_ 2566689790 EngPrechamberFuelDesiredAbsPress "Desired absolute pressure of the gaseous fuel in the separate cylinder pre-chamber rail. This parameter is intended for applications with pre and main chamber fuel systems, which report the pressure of more than one type of fuel.";
CM_ SG_ 2566689790 EngPrechamberFuelAbsPress "Absolute pressure of the gaseous fuel for the separate cylinder pre-chamber rail. This parameter is intended for applications, which use a pre and main chamber fuel systems, which report the pressure of more than one type of fuel.";
CM_ SG_ 2566689790 EngMinChamberFuelDesiredAbsPress "Desired absolute pressure of the gaseous fuel for the main chamber of the cylinder. This parameter is intended for applications with pre and main chamber fuel systems, which report the pressure of more than one type of fuel.Engine";
CM_ SG_ 2566689790 EngMainChamberFuelAbsPress "Absolute pressure of the gaseous fuel for the main chamber of the cylinder. This parameter is intended for applications, which use a pre and main chamber fuel systems, which report the pressure of more than one type of fuel.";
CM_ BO_ 2566689534 "Air Fuel Ratio
This PGN provides Air Fuel Ratio Information";
CM_ SG_ 2566689534 EngPrechamberDesiredAirFuelRatio "Desired air to fuel ratio of the charge entering the cylinder prechamber.";
CM_ SG_ 2566689534 EngPrechamberAirFuelRatio "Actual air to fuel ratio of the charge entering the cylinder prechamber.";
CM_ SG_ 2566689534 EngMinChamberDesiredAirFuelRatio "Desired air to fuel ratio of the charge entering the cylinder main chamber.";
CM_ SG_ 2566689534 EngMainChamberAirFuelRatio "Actual air to fuel ratio of the charge entering the cylinder main chamber.";
CM_ BO_ 2566689278 "Engine Exhaust NOx
This PGN provides cumulative Exhaust NOx information for engines using multiple sensors.";
CM_ SG_ 2566689278 EngExhaustDesiredNOx "Desired NOx concentration in the engine exhaust, prior to any aftertreatment of the exhaust.";
CM_ SG_ 2566689278 EngExhaustNOx "Calculated NOx concentration for the total engine exhaust, prior to any aftertreatment of the exhaust.  This parameter is primarily intended for engines that have separate NOx sensors in separate exhaust manifolds, but the engine does not have an ...";
CM_ BO_ 2499580158 "Engine Fuel Injector Metering Rail Pressure Information 1
Used to transmit the rail pressure information as measured by different rail pressure sensors.";
CM_ SG_ 2499580158 EngInjectorMeteringRail2Press2 "The pressure of fuel measured by second rail pressure sensor in the metering rail 2 as delivered from the supply pump to the injector metering intake.
Note:  This is for the rail pressure from the 2nd rail pressure sensor.  This may be different ...";
CM_ SG_ 2499580158 EngInjectorMeteringRail2Press1 "The pressure of fuel measured by first rail pressure sensor in the metering rail 2 as delivered from the supply pump to the injector metering intake.
Note:  This is for the rail pressure from the 1st rail pressure sensor.  This may be different ...";
CM_ SG_ 2499580158 EngInjectorMeteringRail1Press2 "The pressure of fuel measured by the second rail pressure sensor in the primary, or first, metering rail as delivered from the supply pump to the injector metering intake.
Note:  This is for the rail pressure from the 2nd rail pressure sensor ...";
CM_ SG_ 2499580158 EngInjectorMeteringRail1Press1 "The pressure of fuel measured by first rail pressure sensor in the primary, or first, metering rail as delivered from the supply pump to the injector metering intake.
Note:  This is for the rail pressure from the 1st rail pressure sensor.  This may ...";
CM_ BO_ 2432471038 "Alternate Fuel 3";
CM_ SG_ 2432471038 GasFuelAccumulatorTemp "Gaseous fuel temperature at the outlet of the Gas Filter.";
CM_ SG_ 2432471038 EngFuelVaporizer1DischargeTemp "The temperature of the fuel in its gaseous state at the outlet of the first fuel vaporizer";
CM_ SG_ 2432471038 EngGasFuelSupplyPress "Pressure of gaseous fuel supply to fuel metering device in systems where the pressure range defined for SPN 159 is not sufficient.";
CM_ BO_ 2566688510 "Control Function Functionalities
This message identifies all the functionalities, functionality generation and functionality options, supported by this control function.";
CM_ BO_ 2566688254 "Product Identification Information
Used by a Control Function to provide information in which product the Control Function is mounted.";
CM_ SG_ 2566688254 ProductIdentificationModel "The Product Identification Model specifies a unique product within a Brand.

Examples of Models are:
For Electronic components: SG2600, BT, ICC 230.
For Balers: Big Baler 230AB, XC 130 CV.
For Sprayers: 238i, 1962i, Explorer D.
Etc.";
CM_ SG_ 2566688254 ProductIdentificationBrand "The Product Identification Brand specifies the brand of a product.
 
The combination of the Product Identification Code and the Product Identification Brand shall make the product unique in the world.";
CM_ SG_ 2566688254 ProductIdentificationCode "The Product Identification Code as assigned by the manufacturer corresponds with the identification number on the type plate of a product. For vehicles this number may be the same as the VIN (Vehicle Identification Number) . For stand alone systems ...";
CM_ BO_ 2364567038 "Engine Gaseous Fuel Valve Start of Actuation Command 5
Used to transmit the gaseous fuel valve start of activation command information for valve 17 to valve 20.";
CM_ SG_ 2364567038 EngGsFlVlve20StartOfActuationCmd "The angle, relative to the TDC of cylinder 20, with 0 being the TDC before the power stroke commences, at the which gaseous fuel valve 20 is activated to open.
Timings after TDC are referred with positive values and timings before TDC are referred ...";
CM_ SG_ 2364567038 EngGsFlVlve19StartOfActuationCmd "The angle, relative to the TDC of cylinder 19, with 0 being the TDC before the power stroke commences, at the which gaseous fuel valve 19 is activated to open.
Timings after TDC are referred with positive values and timings before TDC are referred ...";
CM_ SG_ 2364567038 EngGsFlVlve18StartOfActuationCmd "The angle, relative to the TDC of cylinder 18, with 0 being the TDC before the power stroke commences, at the which gaseous fuel valve 18 is activated to open.
Timings after TDC are referred with positive values and timings before TDC are referred ...";
CM_ SG_ 2364567038 EngGsFlVlve17StartOfActuationCmd "The angle, relative to the TDC of cylinder 17, with 0 being the TDC before the power stroke commences, at the which gaseous fuel valve 17 is activated to open.
Timings after TDC are referred with positive values and timings before TDC are referred ...";
CM_ BO_ 2364566782 "Engine Gaseous Fuel Valve Start of Actuation Command 4
Used to transmit the gaseous fuel valve start of activation command information for valve 13 to valve 16.";
CM_ SG_ 2364566782 EngGsFlVlve16StartOfActuationCmd "The angle, relative to the TDC of cylinder 16, with 0 being the TDC before the power stroke commences, at the which gaseous fuel valve 16 is activated to open.
Timings after TDC are referred with positive values and timings before TDC are referred ...";
CM_ SG_ 2364566782 EngGsFlVlve15StartOfActuationCmd "The angle, relative to the TDC of cylinder 15, with 0 being the TDC before the power stroke commences, at the which gaseous fuel valve 15 is activated to open.
Timings after TDC are referred with positive values and timings before TDC are referred ...";
CM_ SG_ 2364566782 EngGsFlVlve14StartOfActuationCmd "The angle, relative to the TDC of cylinder 14, with 0 being the TDC before the power stroke commences, at the which gaseous fuel valve 14 is activated to open.
Timings after TDC are referred with positive values and timings before TDC are referred ...";
CM_ SG_ 2364566782 EngGsFlVlve13StartOfActuationCmd "The angle, relative to the TDC of cylinder 13, with 0 being the TDC before the power stroke commences, at the which gaseous fuel valve 13 is activated to open.
Timings after TDC are referred with positive values and timings before TDC are referred ...";
CM_ BO_ 2364566526 "Engine Gaseous Fuel Valve Start of Actuation Command 3
Used to transmit the gaseous fuel valve start of activation command information for valve 9 to valve 12.";
CM_ SG_ 2364566526 EngGsFlVlve12StartOfActuationCmd "The angle, relative to the TDC of cylinder 12, with 0 being the TDC before the power stroke commences, at the which gaseous fuel valve 12 is activated to open.
Timings after TDC are referred with positive values and timings before TDC are referred ...";
CM_ SG_ 2364566526 EngGsFlVlve11StartOfActuationCmd "The angle, relative to the TDC of cylinder 11, with 0 being the TDC before the power stroke commences, at the which gaseous fuel valve 11 is activated to open.
Timings after TDC are referred with positive values and timings before TDC are referred ...";
CM_ SG_ 2364566526 EngGsFlVlve10StartOfActuationCmd "The angle, relative to the TDC of cylinder 10, with 0 being the TDC before the power stroke commences, at the which gaseous fuel valve 10 is activated to open.
Timings after TDC are referred with positive values and timings before TDC are referred ...";
CM_ SG_ 2364566526 EngGsFlValve9StartOfActuationCmd "The angle, relative to the TDC of cylinder 9, with 0 being the TDC before the power stroke commences, at the which gaseous fuel valve 9 is activated to open.
Timings after TDC are referred with positive values and timings before TDC are referred ...";
CM_ BO_ 2364566270 "Engine Gaseous Fuel Valve Start of Actuation Command 2
Used to transmit the gaseous fuel valve start of activation command information for valve 5 to valve 8.";
CM_ SG_ 2364566270 EngGsFlValve8StartOfActuationCmd "The angle, relative to the TDC of cylinder 8, with 0 being the TDC before the power stroke commences, at the which gaseous fuel valve 8 is activated to open.
Timings after TDC are referred with positive values and timings before TDC are referred ...";
CM_ SG_ 2364566270 EngGsFlValve7StartOfActuationCmd "The angle, relative to the TDC of cylinder 7, with 0 being the TDC before the power stroke commences, at the which gaseous fuel valve 7 is activated to open.
Timings after TDC are referred with positive values and timings before TDC are referred ...";
CM_ SG_ 2364566270 EngGsFlValve6StartOfActuationCmd "The angle, relative to the TDC of cylinder 6, with 0 being the TDC before the power stroke commences, at the which gaseous fuel valve 6 is activated to open.
Timings after TDC are referred with positive values and timings before TDC are referred ...";
CM_ SG_ 2364566270 EngGsFlValve5StartOfActuationCmd "The angle, relative to the TDC of cylinder 5, with 0 being the TDC before the power stroke commences, at the which gaseous fuel valve 5 is activated to open.
Timings after TDC are referred with positive values and timings before TDC are referred ...";
CM_ BO_ 2364566014 "Engine Gaseous Fuel Valve Start of Actuation Command 1
Used to transmit the gaseous fuel valve start of activation command information for valve 1 to valve 4.";
CM_ SG_ 2364566014 EngGsFlValve4StartOfActuationCmd "The angle, relative to the TDC of cylinder 4, with 0 being the TDC before the power stroke commences, at the which gaseous fuel valve 4 is activated to open.
Timings after TDC are referred with positive values and timings before TDC are referred ...";
CM_ SG_ 2364566014 EngGsFlValve3StartOfActuationCmd "The angle, relative to the TDC of cylinder 3, with 0 being the TDC before the power stroke commences, at the which gaseous fuel valve 3 is activated to open.
Timings after TDC are referred with positive values and timings before TDC are referred ...";
CM_ SG_ 2364566014 EngGsFlValve2StartOfActuationCmd "The angle, relative to the TDC of cylinder 2, with 0 being the TDC before the power stroke commences, at the which gaseous fuel valve 2 is activated to open.
Timings after TDC are referred with positive values and timings before TDC are referred ...";
CM_ SG_ 2364566014 EngGsFlValve1StartOfActuationCmd "The angle, relative to the TDC of cylinder 1, with 0 being the TDC before the power stroke commences, at the which gaseous fuel valve 1 is activated to open.
Timings after TDC are referred with positive values and timings before TDC are referred ...";
CM_ BO_ 2364565758 "Engine Gaseous Fuel Valve Duration Command 5
Used to transmit the gaseous fuel valve duration command information for valve 17 to valve 20.";
CM_ SG_ 2364565758 EngGasFuelValve20DurationCmd "Amount of time the gaseous fuel valve 20 is activated.";
CM_ SG_ 2364565758 EngGasFuelValve19DurationCmd "Amount of time the gaseous fuel valve 19 is activated.";
CM_ SG_ 2364565758 EngGasFuelValve18DurationCmd "Amount of time the gaseous fuel valve 18 is activated.";
CM_ SG_ 2364565758 EngGasFuelValve17DurationCmd "Amount of time the gaseous fuel valve 17 is activated.";
CM_ BO_ 2364565502 "Engine Gaseous Fuel Valve Duration Command 4
Used to transmit the gaseous fuel valve duration command information for valve 13 to valve 16.";
CM_ SG_ 2364565502 EngGasFuelValve16DurationCmd "Amount of time the gaseous fuel valve 16 is activated.";
CM_ SG_ 2364565502 EngGasFuelValve15DurationCmd "Amount of time the gaseous fuel valve 15 is activated.";
CM_ SG_ 2364565502 EngGasFuelValve14DurationCmd "Amount of time the gaseous fuel valve 14 is activated.";
CM_ SG_ 2364565502 EngGasFuelValve13DurationCmd "Amount of time the gaseous fuel valve 13 is activated.";
CM_ BO_ 2364565246 "Engine Gaseous Fuel Valve Duration Command 3
Used to transmit the gaseous fuel valve duration command information for valve 9 to valve 12.";
CM_ SG_ 2364565246 EngGasFuelValve12DurationCmd "Amount of time the gaseous fuel valve 12 is activated.";
CM_ SG_ 2364565246 EngGasFuelValve11DurationCmd "Amount of time the gaseous fuel valve 11 is activated.";
CM_ SG_ 2364565246 EngGasFuelValve10DurationCmd "Amount of time the gaseous fuel valve 10 is activated.";
CM_ SG_ 2364565246 EngGasFuelValve9DurationCmd "Amount of time the gaseous fuel valve 9 is activated.";
CM_ BO_ 2364564990 "Engine Gaseous Fuel Valve Duration Command 2
Used to transmit the gaseous fuel valve duration command information for valve 5 to valve 8.";
CM_ SG_ 2364564990 EngGasFuelValve8DurationCmd "Amount of time the gaseous fuel valve 8 is activated.";
CM_ SG_ 2364564990 EngGasFuelValve7DurationCmd "Amount of time the gaseous fuel valve 7 is activated.";
CM_ SG_ 2364564990 EngGasFuelValve6DurationCmd "Amount of time the gaseous fuel valve 6 is activated.";
CM_ SG_ 2364564990 EngGasFuelValve5DurationCmd "Amount of time the gaseous fuel valve 5 is activated.";
CM_ BO_ 2364564734 "Engine Gaseous Fuel Valve Duration Command 1
Used to transmit the gaseous fuel valve duration command information for valve 1 to valve 4.";
CM_ SG_ 2364564734 EngGasFuelValve4DurationCmd "Amount of time the gaseous fuel valve 4 is activated.";
CM_ SG_ 2364564734 EngGasFuelValve3DurationCmd "Amount of time the gaseous fuel valve 3 is activated.";
CM_ SG_ 2364564734 EngGasFuelValve2DurationCmd "Amount of time the gaseous fuel valve 2 is activated.";
CM_ SG_ 2364564734 EngGasFuelValve1DurationCmd "Amount of time the gaseous fuel valve 1 is activated.";
CM_ BO_ 2364564478 "Fuel Information 5 (Gaseous)
Used to transmit the gaseous fuel valve command information.";
CM_ SG_ 2364564478 EngGsFlVlvNmnlStrtOfActuationCmd "The angle, relative to the TDC of each cylinder, with 0 being the TDC before the power stroke commences, at the which gaseous fuel valves are activated to open.  It's a nominal value used for all the gaseous fuel valves in the engine.
Timings after ...";
CM_ SG_ 2364564478 EngGsFuelValveNominalDurationCmd "Amount of time the gaseous fuel valves are activated.  It's a nominal value used for all the gaseous fuel valves in the engine.

Note: Please see SPNs 6658 - 6677 for duration command for each gaseous fuel valves";
CM_ BO_ 2297455358 "Electronic Transmission Controller #12
Electronic Transmission Controller #12";
CM_ SG_ 2297455358 TransDirectionalOutputShaftSpeed "The rotational velocity and direction of the output shaft. Positive values are used for forward vehicle motion, negative values for reverse vehicle motion.

SPN 191 should be used when direction is not used.";
CM_ SG_ 2297455358 TransHydrostaticLoop2Press "Oil pressure in the transmission hydrostatic loop #2 between the pump and motor.";
CM_ SG_ 2297455358 TransHydrostaticLoop1Press "Oil pressure in the transmission hydrostatic loop #1 between the pump and motor.";
CM_ BO_ 2498781694 "Engine Cylinder 20 Combustion Average Information
Used to transmit the average of combustion parameters of Engine Cylinder 20.
This PGN is transmitted at a defined ratio of the engine speed. The transmission rate is dependent on
SPN 6394 - Number ...";
CM_ SG_ 2498781694 EngCyl20AvrageCombustionDuration "Average duration of combustion calculated over defined number of combustion cycles for engine cylinder 20 with reference to the crank angle.  Combustion duration is the difference between end of combustion and start of combustion expressed, in this ...";
CM_ SG_ 2498781694 EngCyl20AvrgCntrOfCmbstionTiming "Average timing calculated over defined number of combustion cycles for the center of combustion in engine cylinder 20 with reference to the crank angle.  Center of Combustion is used to indicate the combustion efficiency.  When the combustion ...";
CM_ SG_ 2498781694 EngCyl20AvrgStrtOfCmbstionTiming "Average start of combustion timing calculated over defined number of combustion cycles for engine cylinder 20 with reference to the crank angle.  When the combustion happens after the TDC (Top Dead Center) of this cylinder, the timing is referred in ...";
CM_ SG_ 2498781694 EngCyl20IndctdMeanEffectivePress "Average cylinder pressure calculated over defined number of combustion cycles for engine cylinder 20.  Negative range is to cover thermodynamic behavior during misfire.";
CM_ BO_ 2498781438 "Engine Cylinder 19 Combustion Average Information
Used to transmit the average of combustion parameters of Engine Cylinder 19.
This PGN is transmitted at a defined ratio of the engine speed. The transmission rate is dependent on
SPN 6394 - Number ...";
CM_ SG_ 2498781438 EngCyl19AvrageCombustionDuration "Average duration of combustion calculated over defined number of combustion cycles for engine cylinder 19 with reference to the crank angle.  Combustion duration is the difference between end of combustion and start of combustion expressed, in this ...";
CM_ SG_ 2498781438 EngCyl19AvrgCntrOfCmbstionTiming "Average timing calculated over defined number of combustion cycles for the center of combustion in engine cylinder 19 with reference to the crank angle.  Center of Combustion is used to indicate the combustion efficiency.  When the combustion ...";
CM_ SG_ 2498781438 EngCyl19AvrgStrtOfCmbstionTiming "Average start of combustion timing calculated over defined number of combustion cycles for engine cylinder 19 with reference to the crank angle.  When the combustion happens after the TDC (Top Dead Center) of this cylinder, the timing is referred in ...";
CM_ SG_ 2498781438 EngCyl19IndctdMeanEffectivePress "Average cylinder pressure calculated over defined number of combustion cycles for engine cylinder 19.  Negative range is to cover thermodynamic behavior during misfire.";
CM_ BO_ 2498781182 "Engine Cylinder 18 Combustion Average Information
Used to transmit the average of combustion parameters of Engine Cylinder 18.
This PGN is transmitted at a defined ratio of the engine speed. The transmission rate is dependent on
SPN 6394 - Number ...";
CM_ SG_ 2498781182 EngCyl18AvrageCombustionDuration "Average duration of combustion calculated over defined number of combustion cycles for engine cylinder 18 with reference to the crank angle.  Combustion duration is the difference between end of combustion and start of combustion expressed, in this ...";
CM_ SG_ 2498781182 EngCyl18AvrgCntrOfCmbstionTiming "Average timing calculated over defined number of combustion cycles for the center of combustion in engine cylinder 18 with reference to the crank angle.  Center of Combustion is used to indicate the combustion efficiency.  When the combustion ...";
CM_ SG_ 2498781182 EngCyl18AvrgStrtOfCmbstionTiming "Average start of combustion timing calculated over defined number of combustion cycles for engine cylinder 18 with reference to the crank angle.  When the combustion happens after the TDC (Top Dead Center) of this cylinder, the timing is referred in ...";
CM_ SG_ 2498781182 EngCyl18IndctdMeanEffectivePress "Average cylinder pressure calculated over defined number of combustion cycles for engine cylinder 18.  Negative range is to cover thermodynamic behavior during misfire.";
CM_ BO_ 2498780926 "Engine Cylinder 17 Combustion Average Information
Used to transmit the average of combustion parameters of Engine Cylinder 17.
This PGN is transmitted at a defined ratio of the engine speed. The transmission rate is dependent on
SPN 6394 - Number ...";
CM_ SG_ 2498780926 EngCyl17AvrageCombustionDuration "Average duration of combustion calculated over defined number of combustion cycles for engine cylinder 17 with reference to the crank angle.  Combustion duration is the difference between end of combustion and start of combustion expressed, in this ...";
CM_ SG_ 2498780926 EngCyl17AvrgCntrOfCmbstionTiming "Average timing calculated over defined number of combustion cycles for the center of combustion in engine cylinder 17 with reference to the crank angle.  Center of Combustion is used to indicate the combustion efficiency.  When the combustion ...";
CM_ SG_ 2498780926 EngCyl17AvrgStrtOfCmbstionTiming "Average start of combustion timing calculated over defined number of combustion cycles for engine cylinder 17 with reference to the crank angle.  When the combustion happens after the TDC (Top Dead Center) of this cylinder, the timing is referred in ...";
CM_ SG_ 2498780926 EngCyl17IndctdMeanEffectivePress "Average cylinder pressure calculated over defined number of combustion cycles for engine cylinder 17.  Negative range is to cover thermodynamic behavior during misfire.";
CM_ BO_ 2498780670 "Engine Cylinder 16 Combustion Average Information
Used to transmit the average of combustion parameters of Engine Cylinder 16.
This PGN is transmitted at a defined ratio of the engine speed. The transmission rate is dependent on
SPN 6394 - Number ...";
CM_ SG_ 2498780670 EngCyl16AvrageCombustionDuration "Average duration of combustion calculated over defined number of combustion cycles for engine cylinder 16 with reference to the crank angle.  Combustion duration is the difference between end of combustion and start of combustion expressed, in this ...";
CM_ SG_ 2498780670 EngCyl16AvrgCntrOfCmbstionTiming "Average timing calculated over defined number of combustion cycles for the center of combustion in engine cylinder 16 with reference to the crank angle.  Center of Combustion is used to indicate the combustion efficiency.  When the combustion ...";
CM_ SG_ 2498780670 EngCyl16AvrgStrtOfCmbstionTiming "Average start of combustion timing calculated over defined number of combustion cycles for engine cylinder 16 with reference to the crank angle.  When the combustion happens after the TDC (Top Dead Center) of this cylinder, the timing is referred in ...";
CM_ SG_ 2498780670 EngCyl16IndctdMeanEffectivePress "Average cylinder pressure calculated over defined number of combustion cycles for engine cylinder 16.  Negative range is to cover thermodynamic behavior during misfire.";
CM_ BO_ 2498780414 "Engine Cylinder 15 Combustion Average Information
Used to transmit the average of combustion parameters of Engine Cylinder 15.
This PGN is transmitted at a defined ratio of the engine speed. The transmission rate is dependent on
SPN 6394 - Number ...";
CM_ SG_ 2498780414 EngCyl15AvrageCombustionDuration "Average duration of combustion calculated over defined number of combustion cycles for engine cylinder 15 with reference to the crank angle.  Combustion duration is the difference between end of combustion and start of combustion expressed, in this ...";
CM_ SG_ 2498780414 EngCyl15AvrgCntrOfCmbstionTiming "Average timing calculated over defined number of combustion cycles for the center of combustion in engine cylinder 15 with reference to the crank angle.  Center of Combustion is used to indicate the combustion efficiency.  When the combustion ...";
CM_ SG_ 2498780414 EngCyl15AvrgStrtOfCmbstionTiming "Average start of combustion timing calculated over defined number of combustion cycles for engine cylinder 15 with reference to the crank angle.  When the combustion happens after the TDC (Top Dead Center) of this cylinder, the timing is referred in ...";
CM_ SG_ 2498780414 EngCyl15IndctdMeanEffectivePress "Average cylinder pressure calculated over defined number of combustion cycles for engine cylinder 15.  Negative range is to cover thermodynamic behavior during misfire.";
CM_ BO_ 2498780158 "Engine Cylinder 14 Combustion Average Information
Used to transmit the average of combustion parameters of Engine Cylinder 14.
This PGN is transmitted at a defined ratio of the engine speed. The transmission rate is dependent on
SPN 6394 - Number ...";
CM_ SG_ 2498780158 EngCyl14AvrageCombustionDuration "Average duration of combustion calculated over defined number of combustion cycles for engine cylinder 14 with reference to the crank angle.  Combustion duration is the difference between end of combustion and start of combustion expressed, in this ...";
CM_ SG_ 2498780158 EngCyl14AvrgCntrOfCmbstionTiming "Average timing calculated over defined number of combustion cycles for the center of combustion in engine cylinder 14 with reference to the crank angle.  Center of Combustion is used to indicate the combustion efficiency.  When the combustion ...";
CM_ SG_ 2498780158 EngCyl14AvrgStrtOfCmbstionTiming "Average start of combustion timing calculated over defined number of combustion cycles for engine cylinder 14 with reference to the crank angle.  When the combustion happens after the TDC (Top Dead Center) of this cylinder, the timing is referred in ...";
CM_ SG_ 2498780158 EngCyl14IndctdMeanEffectivePress "Average cylinder pressure calculated over defined number of combustion cycles for engine cylinder 14.  Negative range is to cover thermodynamic behavior during misfire.";
CM_ BO_ 2498779902 "Engine Cylinder 13 Combustion Average Information
Used to transmit the average of combustion parameters of Engine Cylinder 13.
This PGN is transmitted at a defined ratio of the engine speed. The transmission rate is dependent on
SPN 6394 - Number ...";
CM_ SG_ 2498779902 EngCyl13AvrageCombustionDuration "Average duration of combustion calculated over defined number of combustion cycles for engine cylinder 13 with reference to the crank angle.  Combustion duration is the difference between end of combustion and start of combustion expressed, in this ...";
CM_ SG_ 2498779902 EngCyl13AvrgCntrOfCmbstionTiming "Average timing calculated over defined number of combustion cycles for the center of combustion in engine cylinder 13 with reference to the crank angle.  Center of Combustion is used to indicate the combustion efficiency.  When the combustion ...";
CM_ SG_ 2498779902 EngCyl13AvrgStrtOfCmbstionTiming "Average start of combustion timing calculated over defined number of combustion cycles for engine cylinder 13 with reference to the crank angle.  When the combustion happens after the TDC (Top Dead Center) of this cylinder, the timing is referred in ...";
CM_ SG_ 2498779902 EngCyl13IndctdMeanEffectivePress "Average cylinder pressure calculated over defined number of combustion cycles for engine cylinder 13.  Negative range is to cover thermodynamic behavior during misfire.";
CM_ BO_ 2498779646 "Engine Cylinder 12 Combustion Average Information
Used to transmit the average of combustion parameters of Engine Cylinder 12.
This PGN is transmitted at a defined ratio of the engine speed. The transmission rate is dependent on
SPN 6394 - Number ...";
CM_ SG_ 2498779646 EngCyl12AvrageCombustionDuration "Average duration of combustion calculated over defined number of combustion cycles for engine cylinder 12 with reference to the crank angle.  Combustion duration is the difference between end of combustion and start of combustion expressed, in this ...";
CM_ SG_ 2498779646 EngCyl12AvrgCntrOfCmbstionTiming "Average timing calculated over defined number of combustion cycles for the center of combustion in engine cylinder 12 with reference to the crank angle.  Center of Combustion is used to indicate the combustion efficiency.  When the combustion ...";
CM_ SG_ 2498779646 EngCyl12AvrgStrtOfCmbstionTiming "Average start of combustion timing calculated over defined number of combustion cycles for engine cylinder 12 with reference to the crank angle.  When the combustion happens after the TDC (Top Dead Center) of this cylinder, the timing is referred in ...";
CM_ SG_ 2498779646 EngCyl12IndctdMeanEffectivePress "Average cylinder pressure calculated over defined number of combustion cycles for engine cylinder 12.  Negative range is to cover thermodynamic behavior during misfire.";
CM_ BO_ 2498779390 "Engine Cylinder 11 Combustion Average Information
Used to transmit the average of combustion parameters of Engine Cylinder 11.
This PGN is transmitted at a defined ratio of the engine speed. The transmission rate is dependent on
SPN 6394 - Number ...";
CM_ SG_ 2498779390 EngCyl11AvrageCombustionDuration "Average duration of combustion calculated over defined number of combustion cycles for engine cylinder 11 with reference to the crank angle.  Combustion duration is the difference between end of combustion and start of combustion expressed, in this ...";
CM_ SG_ 2498779390 EngCyl11AvrgCntrOfCmbstionTiming "Average timing calculated over defined number of combustion cycles for the center of combustion in engine cylinder 11 with reference to the crank angle.  Center of Combustion is used to indicate the combustion efficiency.  When the combustion ...";
CM_ SG_ 2498779390 EngCyl11AvrgStrtOfCmbstionTiming "Average start of combustion timing calculated over defined number of combustion cycles for engine cylinder 11 with reference to the crank angle.  When the combustion happens after the TDC (Top Dead Center) of this cylinder, the timing is referred in ...";
CM_ SG_ 2498779390 EngCyl11IndctdMeanEffectivePress "Average cylinder pressure calculated over defined number of combustion cycles for engine cylinder 11.  Negative range is to cover thermodynamic behavior during misfire.";
CM_ BO_ 2498779134 "Engine Cylinder 10 Combustion Average Information
Used to transmit the average of combustion parameters of Engine Cylinder 10.
This PGN is transmitted at a defined ratio of the engine speed. The transmission rate is dependent on
SPN 6394 - Number ...";
CM_ SG_ 2498779134 EngCyl10AvrageCombustionDuration "Average duration of combustion calculated over defined number of combustion cycles for engine cylinder 10 with reference to the crank angle.  Combustion duration is the difference between end of combustion and start of combustion expressed, in this ...";
CM_ SG_ 2498779134 EngCyl10AvrgCntrOfCmbstionTiming "Average timing calculated over defined number of combustion cycles for the center of combustion in engine cylinder 10 with reference to the crank angle.  Center of Combustion is used to indicate the combustion efficiency.  When the combustion ...";
CM_ SG_ 2498779134 EngCyl10AvrgStrtOfCmbstionTiming "Average start of combustion timing calculated over defined number of combustion cycles for engine cylinder 10 with reference to the crank angle.  When the combustion happens after the TDC (Top Dead Center) of this cylinder, the timing is referred in ...";
CM_ SG_ 2498779134 EngCyl10IndctdMeanEffectivePress "Average cylinder pressure calculated over defined number of combustion cycles for engine cylinder 10.  Negative range is to cover thermodynamic behavior during misfire.";
CM_ BO_ 2498778878 "Engine Cylinder 9 Combustion Average Information
Used to transmit the average of combustion parameters of Engine Cylinder 9.
This PGN is transmitted at a defined ratio of the engine speed. The transmission rate is dependent on
SPN 6394 - Number ...";
CM_ SG_ 2498778878 EngCyl9AverageCombustionDuration "Average duration of combustion calculated over defined number of combustion cycles for engine cylinder 9 with reference to the crank angle.  Combustion duration is the difference between end of combustion and start of combustion expressed, in this ...";
CM_ SG_ 2498778878 EngCyl9AvrgCntrOfCmbustionTiming "Average timing calculated over defined number of combustion cycles for the center of combustion in engine cylinder 9 with reference to the crank angle.  Center of Combustion is used to indicate the combustion efficiency.  When the combustion happens ...";
CM_ SG_ 2498778878 EngCyl9AvrgStrtOfCmbustionTiming "Average start of combustion timing calculated over defined number of combustion cycles for engine cylinder 9 with reference to the crank angle.  When the combustion happens after the TDC (Top Dead Center) of this cylinder, the timing is referred in ...";
CM_ SG_ 2498778878 EngCyl9IndctedMeanEffectivePress "Average cylinder pressure calculated over defined number of combustion cycles for engine cylinder 9.  Negative range is to cover thermodynamic behavior during misfire.";
CM_ BO_ 2566757118 "Electronic Brake System #2/4
Message to transmit data of the towed vehicle to the towing vehicle. See ISO 11992-3.";
CM_ BO_ 2559246078 "Running Gear Equipment #1/2
Message to transmit data of the towing vehicle to the towed vehicle. See ISO 11992-2.";
CM_ BO_ 2559180542 "Running Gear Equipment #2/4
Message to transmit data of the towed vehicle to the towing vehicle. See ISO 11992-2.";
CM_ BO_ 2365428734 "Generator Control 1
Message for the generator set control to change or report the status of the generator system.";
CM_ SG_ 2365428734 GenFrequencySelection "Command from user and/or generator control system for the genset (engine) to target operations for 50 Hz, 60 Hz, or 400 Hz.

0000 = 50 Hz
0001 = 60 Hz
0010 = 400 Hz
0011 - 1101 = SAE Reserved
1110 = Unknown
1111= Don't care /take no action";
CM_ SG_ 2365428734 GenGoverningSpeedCommand "Command from user and/or generator control system for the genset (engine) to govern to low idle or rated base speed setpoints.  If this method of engine control is used, then the PGN 0 (TSC1) is not expected to be received by the engine controller ...";
CM_ SG_ 2365428734 GenAlternatorEfficiency "Measured, calculated, and/or estimated operating efficiency of the generator alternator.  Percentage reflects ratio of power output divided by power input, multiplied by 100.";
CM_ SG_ 2365428734 GenNotReadyToAutoParaState "This parameter indicates whether or not all systems required to start the engine and close to the bus are prepared to operate automatically. If not, the generator is not ready to automatically parallel, and the status parameter is in the ACTIVE ...";
CM_ SG_ 2365428734 GenCtrlNotInAutoStartState "This parameter indicates whether or not the generator set is in a condition to automatically start up and provide power. If not, this status parameter is in the ACTIVE state.
00 = inactive (ready to start automatically)
01 = active (not ready to ...";
CM_ SG_ 2365428734 RequestedEngineControlMode "This parameter is used to request a change to the engine control mode.  This is a status parameter.
Bit state 0000 = Normal Engine Shutdown
Bit state 0001 = Rapid Engine Shutdown
Bit state 0010 = Emergency Engine Shutdown
Bit state 0011 = Normal ...";
CM_ SG_ 2365428734 EngSpeedGovernorDroop "This is the percent speed droop adjustment relative to rated speed setpoint. The Engine Speed Droop is equal to the following equation:
100*[(Engine Speed at no load - Engine Speed at full rated load)/ (Engine Speed at full rated load)].
The ...";
CM_ SG_ 2365428734 EngSpeedGovernorGainAdjust "This parameter is used to adjust multiple gains at same time to attain engine stability across a broader range of applications.  

-32128 is least responsive
0 is normal
+32127 is most responsive";
CM_ BO_ 2566702846 "OBD Information";
CM_ SG_ 2566702846 EngOBDWarmUpSequence "Engine warm-up as defined by the applicable region's regulatory agency.  In the US, \"Engine OBD Warm-up\" or “Warm-up cycle” means sufficient vehicle operation such that coolant temperature rises by at least 22.2 °C (40 °F) from engine starting and ...";
CM_ BO_ 2566703102 "Engine Emissions Certification Information";
CM_ SG_ 2566703102 CertificationEngineFamilyName "The regulated family name per the applicable region's certification agency.  For engines certified in the US, this shall be the 12-character engine family name or test group as defined by EPA.  Up to 200 characters may be used.  The characters are ...";
CM_ SG_ 2566703102 ModelYear "The compliance model year of the OBD system of the engine and or vehicle.  For example in the US, this is associated with either a vehicle model year or an engine model year, depending on how the emissions and OBD are certified.  This message shall ...";
CM_ BO_ 2566705918 "Previously Active Service Only DTCs";
CM_ SG_ 2566705918 DTC1 "Diagnostic Trouble Code";
CM_ SG_ 2566705918 FlashProtectLamp "This parameter provides the capability to flash the engine protect lamp


00 - Slow Flash (1 Hz, 50 % duty cycle)
01 - Fast Flash (2 Hz or faster, 50% duty cycle)
10 - Reserved
11 - Unavailable / Do Not Flash";
CM_ SG_ 2566705918 FlashAmberWarningLamp "This parameter provides the capability to flash the AWL

00 - Slow Flash (1 Hz, 50 % duty cycle)
01 - Fast Flash (2 Hz or faster, 50% duty cycle)
10 - Reserved
11 - Unavailable / Do Not Flash";
CM_ SG_ 2566705918 FlashRedStopLamp "This parameter provides the capability to flash the RSL


00 - Slow Flash (1 Hz, 50 % duty cycle)
01 - Fast Flash (2 Hz or faster, 50% duty cycle)
10 - Reserved
11 - Unavailable / Do Not Flash";
CM_ SG_ 2566705918 FlashMalfuncIndicatorLamp "This parameter provides the capability to flash the MIL
00 - Slow Flash (1 Hz, 50 % duty cycle)
01 - Fast Flash (2 Hz or faster, 50% duty cycle)
10 - Class C DTC
11 - Unavailable / Do Not Flash
Note:  State 10 is for WWH OBD discriminatory ...";
CM_ SG_ 2566705918 ProtectLampStatus "This lamp is used to relay trouble code information that is reporting a problem with a vehicle system that is most probably not electronic subsystem related. For instance, engine coolant temperature is exceeding its prescribed temperature range.
00 ...";
CM_ SG_ 2566705918 AmberWarningLampStatus "This lamp is used to relay trouble code information that is reporting a problem with the vehicle system but the vehicle need not be immediately stopped. 

00     Lamp Off
01     Lamp On
10     Reserved
11     Not available";
CM_ SG_ 2566705918 RedStopLampState "This lamp is used to relay trouble code information that is of a severe enough condition that it warrants stopping the vehicle.

00     Lamp Off
01     Lamp On
10     Reserved
11     Not available";
CM_ SG_ 2566705918 MalfunctionIndicatorLampStatus "A lamp used to relay only emissions-related trouble code information. This lamp is only illuminated when there is an emission-related trouble code active.
00     Lamp Off
01     Lamp On
10     Short MIL for WWH OBD
11     Not available
Note ...";
CM_ SG_ 2566705918 DTC5 "Diagnostic Trouble Code";
CM_ SG_ 2566705918 DTC4 "Diagnostic Trouble Code";
CM_ SG_ 2566705918 DTC3 "Diagnostic Trouble Code";
CM_ SG_ 2566705918 DTC2 "Diagnostic Trouble Code";
CM_ BO_ 2566705662 "Active Service Only DTCs";
CM_ SG_ 2566705662 DTC1 "Diagnostic Trouble Code";
CM_ SG_ 2566705662 FlashProtectLamp "This parameter provides the capability to flash the engine protect lamp


00 - Slow Flash (1 Hz, 50 % duty cycle)
01 - Fast Flash (2 Hz or faster, 50% duty cycle)
10 - Reserved
11 - Unavailable / Do Not Flash";
CM_ SG_ 2566705662 FlashAmberWarningLamp "This parameter provides the capability to flash the AWL

00 - Slow Flash (1 Hz, 50 % duty cycle)
01 - Fast Flash (2 Hz or faster, 50% duty cycle)
10 - Reserved
11 - Unavailable / Do Not Flash";
CM_ SG_ 2566705662 FlashRedStopLamp "This parameter provides the capability to flash the RSL


00 - Slow Flash (1 Hz, 50 % duty cycle)
01 - Fast Flash (2 Hz or faster, 50% duty cycle)
10 - Reserved
11 - Unavailable / Do Not Flash";
CM_ SG_ 2566705662 FlashMalfuncIndicatorLamp "This parameter provides the capability to flash the MIL
00 - Slow Flash (1 Hz, 50 % duty cycle)
01 - Fast Flash (2 Hz or faster, 50% duty cycle)
10 - Class C DTC
11 - Unavailable / Do Not Flash
Note:  State 10 is for WWH OBD discriminatory ...";
CM_ SG_ 2566705662 ProtectLampStatus "This lamp is used to relay trouble code information that is reporting a problem with a vehicle system that is most probably not electronic subsystem related. For instance, engine coolant temperature is exceeding its prescribed temperature range.
00 ...";
CM_ SG_ 2566705662 AmberWarningLampStatus "This lamp is used to relay trouble code information that is reporting a problem with the vehicle system but the vehicle need not be immediately stopped. 

00     Lamp Off
01     Lamp On
10     Reserved
11     Not available";
CM_ SG_ 2566705662 RedStopLampState "This lamp is used to relay trouble code information that is of a severe enough condition that it warrants stopping the vehicle.

00     Lamp Off
01     Lamp On
10     Reserved
11     Not available";
CM_ SG_ 2566705662 MalfunctionIndicatorLampStatus "A lamp used to relay only emissions-related trouble code information. This lamp is only illuminated when there is an emission-related trouble code active.
00     Lamp Off
01     Lamp On
10     Short MIL for WWH OBD
11     Not available
Note ...";
CM_ SG_ 2566705662 DTC5 "Diagnostic Trouble Code";
CM_ SG_ 2566705662 DTC4 "Diagnostic Trouble Code";
CM_ SG_ 2566705662 DTC3 "Diagnostic Trouble Code";
CM_ SG_ 2566705662 DTC2 "Diagnostic Trouble Code";
CM_ BO_ 2566706174 "Diagnostic Data Clear/Reset for All Service Only DTCs
All of the diagnostic information pertaining to the active service only diagnostic trouble codes and previously active diagnostic trouble codes should be erased as well as the DTCs.";
CM_ BO_ 2349465342 "Static Roll Angle Sensor Information
Contains Static Roll Angle Data and Status of the Static Roll Angle Sensor";
CM_ SG_ 2349465342 StaticRollAngleStatus "Status of the transmitted roll angle data.

000 = Sensor Busy
001 = Sensor OK
010 = Sensor Defect
011 = Sensor Reboots
100 = Angle Data Invalid
101 = Reserved
110 = Error
111 = Not available";
CM_ SG_ 2349465342 StaticRollAngle "The measured static roll angle between the vehicle y-axis and the ground plane about the X-axis.  The sign of the roll angle is determined in accordance to the right-hand rule about the X-axis, as specified in SAE J670.  Roll angle is the same for ...";
CM_ BO_ 2498777086 "Engine Cylinder 2 Combustion Average Information
Used to transmit the average of combustion parameters of Engine Cylinder 2.
This PGN is transmitted at a defined ratio of the engine speed. The transmission rate is dependent on
SPN 6394 - Number ...";
CM_ SG_ 2498777086 EngCyl2AverageCombustionDuration "Average duration of combustion calculated over defined number of combustion cycles for engine cylinder 2 with reference to the crank angle.  Combustion duration is the difference between end of combustion and start of combustion expressed, in this ...";
CM_ SG_ 2498777086 EngCyl2AvrgCntrOfCmbustionTiming "Average timing calculated over defined number of combustion cycles for the center of combustion in engine cylinder 2 with reference to the crank angle.  Center of Combustion is used to indicate the combustion efficiency.  When the combustion happens ...";
CM_ SG_ 2498777086 EngCyl2AvrgStrtOfCmbustionTiming "Average start of combustion timing calculated over defined number of combustion cycles for engine cylinder 2 with reference to the crank angle.  When the combustion happens after the TDC (Top Dead Center) of this cylinder, the timing is referred in ...";
CM_ SG_ 2498777086 EngCyl2IndctedMeanEffectivePress "Average cylinder pressure calculated over defined number of combustion cycles for engine cylinder 2.  Negative range is to cover thermodynamic behavior during misfire.";
CM_ BO_ 2498776830 "Engine Cylinder 1 Combustion Average Information
Used to transmit the average of combustion parameters of Engine Cylinder 1.
This PGN is transmitted at a defined ratio of the engine speed. The transmission rate is dependent on
SPN 6394 - Number ...";
CM_ SG_ 2498776830 EngCyl1AverageCombustionDuration "Average duration of combustion calculated over defined number of combustion cycles for engine cylinder 1 with reference to the crank angle.  Combustion duration is the difference between end of combustion and start of combustion expressed, in this ...";
CM_ SG_ 2498776830 EngCyl1AvrgCntrOfCmbustionTiming "Average timing calculated over defined number of combustion cycles for the center of combustion in engine cylinder 1 with reference to the crank angle.  Center of Combustion is used to indicate the combustion efficiency.  When the combustion happens ...";
CM_ SG_ 2498776830 EngCyl1AvrgStrtOfCmbustionTiming "Average start of combustion timing calculated over defined number of combustion cycles for engine cylinder 1 with reference to the crank angle.  When the combustion happens after the TDC (Top Dead Center) of this cylinder, the timing is referred in ...";
CM_ SG_ 2498776830 EngCyl1IndctedMeanEffectivePress "Average cylinder pressure calculated over defined number of combustion cycles for engine cylinder 1.   Negative range is to cover thermodynamic behavior during misfire.";
CM_ BO_ 2364558846 "Engine Cylinder 20 Combustion Information
Used to communicate combustion information of Engine Cylinder 20. The PGN is transmitted at the end of every combustion in Cylinder 20.";
CM_ SG_ 2364558846 MaxPressIncreaseRate "The maximum slope, in degrees of crank angle, of the pressure increase in engine cylinder 20 during the combustion cycle.";
CM_ SG_ 2364558846 LowFreqKnockLvl "Indicates the level of low frequency knock for engine cylinder 20. This knock occurs at frequencies below the typical knock level reported on SPNs 1371 & 6474.  The level of low frequency knock is reported using a relative scale where 0% is least ...";
CM_ SG_ 2364558846 EngCyl20PrssSensorPreliminaryFMI "Used to identify the applicable J1939-73 FMI detected in the engine cylinder 20 pressure sensor.  When there is no failure FMI 31 is sent. In the case of multiple failures the most severe is communicated.";
CM_ SG_ 2364558846 EngCyl20SynchronousKnockLevel "Used to indicate the level of knock for engine cylinder 20. The level of knock is reported using a relative scale where 0% is least level of knock, and increasing levels indicate more knock until 100% indicates the most severe level of knock allowed ...";
CM_ SG_ 2364558846 EngCyl20PeakPress "Peak pressure in engine cylinder 20 in combustion cycle.";
CM_ SG_ 2364558846 EngCyl20HeatRelease "The amount of heat produced during combustion in engine cylinder 20.  The negative range is to cover thermodynamic behavior during misfire.";
CM_ BO_ 2364558590 "Engine Cylinder 19 Combustion Information
Used to communicate combustion information of Engine Cylinder 19. The PGN is transmitted at the end of every combustion in Cylinder 19.";
CM_ SG_ 2364558590 MaxPressIncreaseRate "The maximum slope, in degrees of crank angle, of the pressure increase in engine cylinder 19 during the combustion cycle.";
CM_ SG_ 2364558590 LowFreqKnockLvl "Indicates the level of low frequency knock for engine cylinder 19. This knock occurs at frequencies below the typical knock level reported on SPNs 1370 & 6470.  The level of low frequency knock is reported using a relative scale where 0% is least ...";
CM_ SG_ 2364558590 EngCyl19PrssSensorPreliminaryFMI "Used to identify the applicable J1939-73 FMI detected in the engine cylinder 19 pressure sensor.  When there is no failure FMI 31 is sent. In the case of multiple failures the most severe is communicated.";
CM_ SG_ 2364558590 EngCyl19SynchronousKnockLevel "Used to indicate the level of knock for engine cylinder 19. The level of knock is reported using a relative scale where 0% is least level of knock, and increasing levels indicate more knock until 100% indicates the most severe level of knock allowed ...";
CM_ SG_ 2364558590 EngCyl19PeakPress "Peak pressure in engine cylinder 19 in combustion cycle.";
CM_ SG_ 2364558590 EngCyl19HeatRelease "The amount of heat produced during combustion in engine cylinder 19.  The negative range is to cover thermodynamic behavior during misfire.";
CM_ BO_ 2364558334 "Engine Cylinder 18 Combustion Information
Used to communicate combustion information of Engine Cylinder 18. The PGN is transmitted at the end of every combustion in Cylinder 18.";
CM_ SG_ 2364558334 MaxPressIncreaseRate "The maximum slope, in degrees of crank angle, of the pressure increase in engine cylinder 18 during the combustion cycle.";
CM_ SG_ 2364558334 LowFreqKnockLvl "Indicates the level of low frequency knock for engine cylinder 18. This knock occurs at frequencies below the typical knock level reported on SPNs 1369 & 6466.  The level of low frequency knock is reported using a relative scale where 0% is least ...";
CM_ SG_ 2364558334 EngCyl18PrssSensorPreliminaryFMI "Used to identify the applicable J1939-73 FMI detected in the engine cylinder 18 pressure sensor.  When there is no failure FMI 31 is sent. In the case of multiple failures the most severe is communicated.";
CM_ SG_ 2364558334 EngCyl18SynchronousKnockLevel "Used to indicate the level of knock for engine cylinder 18. The level of knock is reported using a relative scale where 0% is least level of knock, and increasing levels indicate more knock until 100% indicates the most severe level of knock allowed ...";
CM_ SG_ 2364558334 EngCyl18PeakPress "Peak pressure in engine cylinder 18 in combustion cycle.";
CM_ SG_ 2364558334 EngCyl18HeatRelease "The amount of heat produced during combustion in engine cylinder 18.  The negative range is to cover thermodynamic behavior during misfire.";
CM_ BO_ 2364558078 "Engine Cylinder 17 Combustion Information
Used to communicate combustion information of Engine Cylinder 17. The PGN is transmitted at the end of every combustion in Cylinder 17.";
CM_ SG_ 2364558078 MaxPressIncreaseRate "The maximum slope, in degrees of crank angle, of the pressure increase in engine cylinder 17 during the combustion cycle.";
CM_ SG_ 2364558078 LowFreqKnockLvl "Indicates the level of low frequency knock for engine cylinder 17. This knock occurs at frequencies below the typical knock level reported on SPNs 1368 & 6462.  The level of low frequency knock is reported using a relative scale where 0% is least ...";
CM_ SG_ 2364558078 EngCyl17PrssSensorPreliminaryFMI "Used to identify the applicable J1939-73 FMI detected in the engine cylinder 17 pressure sensor.  When there is no failure FMI 31 is sent. In the case of multiple failures the most severe is communicated.";
CM_ SG_ 2364558078 EngCyl17SynchronousKnockLevel "Used to indicate the level of knock for engine cylinder 17. The level of knock is reported using a relative scale where 0% is least level of knock, and increasing levels indicate more knock until 100% indicates the most severe level of knock allowed ...";
CM_ SG_ 2364558078 EngCyl17PeakPress "Peak pressure in engine cylinder 17 in combustion cycle.";
CM_ SG_ 2364558078 EngCyl17HeatRelease "The amount of heat produced during combustion in engine cylinder 17.  The negative range is to cover thermodynamic behavior during misfire.";
CM_ BO_ 2364557822 "Engine Cylinder 16 Combustion Information
Used to communicate combustion information of Engine Cylinder 16. The PGN is transmitted at the end of every combustion in Cylinder 16.";
CM_ SG_ 2364557822 MaxPressIncreaseRate "The maximum slope, in degrees of crank angle, of the pressure increase in engine cylinder 16 during the combustion cycle.";
CM_ SG_ 2364557822 LowFreqKnockLvl "Indicates the level of low frequency knock for engine cylinder 16. This knock occurs at frequencies below the typical knock level reported on SPNs 1367 & 6458.  The level of low frequency knock is reported using a relative scale where 0% is least ...";
CM_ SG_ 2364557822 EngCyl16PrssSensorPreliminaryFMI "Used to identify the applicable J1939-73 FMI detected in the engine cylinder 16 pressure sensor.  When there is no failure FMI 31 is sent. In the case of multiple failures the most severe is communicated.";
CM_ SG_ 2364557822 EngCyl16SynchronousKnockLevel "Used to indicate the level of knock for engine cylinder 16. The level of knock is reported using a relative scale where 0% is least level of knock, and increasing levels indicate more knock until 100% indicates the most severe level of knock allowed ...";
CM_ SG_ 2364557822 EngCyl16PeakPress "Peak pressure in engine cylinder 16 in combustion cycle.";
CM_ SG_ 2364557822 EngCyl16HeatRelease "The amount of heat produced during combustion in engine cylinder 16.  The negative range is to cover thermodynamic behavior during misfire.";
BA_DEF_ SG_  "SigType" ENUM  "Default","Range","RangeSigned","ASCII","Discrete","Control","ReferencePGN","DTC","StringDelimiter","StringLength","StringLengthControl","MessageCounter","MessageChecksum";
BA_DEF_ SG_  "GenSigStartValue" INT 0 2147483647;
BA_DEF_ SG_  "GenSigSendType" ENUM  "Cyclic","OnWrite","OnWriteWithRepetition","OnChange","OnChangeWithRepetition","IfActive","IfActiveWithRepetition","NoSigSendType";
BA_DEF_ SG_  "GenSigILSupport" ENUM  "No","Yes";
BA_DEF_ SG_  "GenSigEVName" STRING ;
BA_DEF_ SG_  "SPN" INT 0 524287;
BA_DEF_ BO_  "TpJ1939VarDlc" ENUM  "No","Yes";
BA_DEF_ BO_  "GenMsgStartDelayTime" INT 0 100000;
BA_DEF_ BO_  "GenMsgILSupport" ENUM  "No","Yes";
BA_DEF_ BO_  "GenMsgDelayTime" INT 0 1000;
BA_DEF_ BO_  "GenMsgRequestable" INT 0 1;
BA_DEF_ BO_  "GenMsgSendType" ENUM  "cyclic","NotUsed","NotUsed","NotUsed","NotUsed","NotUsed","NotUsed","IfActive","noMsgSendType";
BA_DEF_ BO_  "VFrameFormat" ENUM  "StandardCAN","ExtendedCAN","reserved","J1939PG";
BA_DEF_ BO_  "GenMsgCycleTime" INT 0 3600000;
BA_DEF_ SG_  "SystemSignalLongSymbol" STRING ;
BA_DEF_DEF_  "SigType" "Default";
BA_DEF_DEF_  "GenSigStartValue" 0;
BA_DEF_DEF_  "GenSigSendType" "NoSigSendType";
BA_DEF_DEF_  "GenSigILSupport" "Yes";
BA_DEF_DEF_  "GenSigEVName" "Env@Nodename_@Signame";
BA_DEF_DEF_  "SPN" 0;
BA_DEF_DEF_  "TpJ1939VarDlc" "No";
BA_DEF_DEF_  "GenMsgStartDelayTime" 0;
BA_DEF_DEF_  "GenMsgILSupport" "Yes";
BA_DEF_DEF_  "GenMsgDelayTime" 0;
BA_DEF_DEF_  "GenMsgRequestable" 1;
BA_DEF_DEF_  "GenMsgSendType" "noMsgSendType";
BA_DEF_DEF_  "VFrameFormat" "J1939PG";
BA_DEF_DEF_  "GenMsgCycleTime" 0;
BA_DEF_DEF_  "SystemSignalLongSymbol" "";
BA_ "GenMsgSendType" BO_ 2566697470 0;
BA_ "GenMsgCycleTime" BO_ 2566697470 100;
BA_ "GenMsgSendType" BO_ 2566692862 0;
BA_ "GenMsgCycleTime" BO_ 2566692862 1000;
BA_ "GenMsgDelayTime" BO_ 2499583742 100;
BA_ "GenMsgSendType" BO_ 2499583742 0;
BA_ "GenMsgCycleTime" BO_ 2499583742 1000;
BA_ "GenMsgDelayTime" BO_ 2499583486 100;
BA_ "GenMsgSendType" BO_ 2499583486 0;
BA_ "GenMsgCycleTime" BO_ 2499583486 1000;
BA_ "TpJ1939VarDlc" BO_ 2566691326 1;
BA_ "GenMsgSendType" BO_ 2499582206 0;
BA_ "GenMsgCycleTime" BO_ 2499582206 500;
BA_ "GenMsgDelayTime" BO_ 2566690814 20;
BA_ "GenMsgSendType" BO_ 2566690814 0;
BA_ "GenMsgCycleTime" BO_ 2566690814 500;
BA_ "GenMsgSendType" BO_ 2566690558 0;
BA_ "GenMsgCycleTime" BO_ 2566690558 100;
BA_ "GenMsgSendType" BO_ 2365363710 0;
BA_ "GenMsgCycleTime" BO_ 2365363710 100;
BA_ "GenMsgSendType" BO_ 2566690046 0;
BA_ "GenMsgCycleTime" BO_ 2566690046 1000;
BA_ "GenMsgSendType" BO_ 2499580158 0;
BA_ "GenMsgCycleTime" BO_ 2499580158 500;
BA_ "GenMsgSendType" BO_ 2432471038 0;
BA_ "GenMsgCycleTime" BO_ 2432471038 100;
BA_ "TpJ1939VarDlc" BO_ 2566688254 1;
BA_ "GenMsgSendType" BO_ 2297455358 0;
BA_ "GenMsgCycleTime" BO_ 2297455358 10;
BA_ "GenMsgSendType" BO_ 2365428734 0;
BA_ "GenMsgCycleTime" BO_ 2365428734 100;
BA_ "TpJ1939VarDlc" BO_ 2566702846 1;
BA_ "TpJ1939VarDlc" BO_ 2566703102 1;
BA_ "TpJ1939VarDlc" BO_ 2566705918 1;
BA_ "TpJ1939VarDlc" BO_ 2566705662 1;
BA_ "GenMsgSendType" BO_ 2349465342 0;
BA_ "GenMsgCycleTime" BO_ 2349465342 100;
BA_ "SigType" SG_ 2566697982 FusedOutput32Current 1;
BA_ "SPN" SG_ 2566697982 FusedOutput32Current 6111;
BA_ "SigType" SG_ 2566697982 FusedOutput31Current 1;
BA_ "SPN" SG_ 2566697982 FusedOutput31Current 6110;
BA_ "SigType" SG_ 2566697982 FusedOutput30Current 1;
BA_ "SPN" SG_ 2566697982 FusedOutput30Current 6109;
BA_ "SigType" SG_ 2566697982 FusedOutput29Current 1;
BA_ "SPN" SG_ 2566697982 FusedOutput29Current 6108;
BA_ "SigType" SG_ 2566697982 FusedOutput28Current 1;
BA_ "SPN" SG_ 2566697982 FusedOutput28Current 6107;
BA_ "SigType" SG_ 2566697982 FusedOutput27Current 1;
BA_ "SPN" SG_ 2566697982 FusedOutput27Current 6106;
BA_ "SigType" SG_ 2566697982 FusedOutput26Current 1;
BA_ "SPN" SG_ 2566697982 FusedOutput26Current 6105;
BA_ "SigType" SG_ 2566697982 FusedOutput25Current 1;
BA_ "SPN" SG_ 2566697982 FusedOutput25Current 6104;
BA_ "SigType" SG_ 2566697982 FusedOutput24Current 1;
BA_ "SPN" SG_ 2566697982 FusedOutput24Current 6103;
BA_ "SigType" SG_ 2566697982 FusedOutput23Current 1;
BA_ "SPN" SG_ 2566697982 FusedOutput23Current 6102;
BA_ "SigType" SG_ 2566697982 FusedOutput22Current 1;
BA_ "SPN" SG_ 2566697982 FusedOutput22Current 6101;
BA_ "SigType" SG_ 2566697982 FusedOutput21Current 1;
BA_ "SPN" SG_ 2566697982 FusedOutput21Current 6100;
BA_ "SigType" SG_ 2566697982 FusedOutput20Current 1;
BA_ "SPN" SG_ 2566697982 FusedOutput20Current 6099;
BA_ "SigType" SG_ 2566697982 FusedOutput19Current 1;
BA_ "SPN" SG_ 2566697982 FusedOutput19Current 6098;
BA_ "SigType" SG_ 2566697982 FusedOutput18Current 1;
BA_ "SPN" SG_ 2566697982 FusedOutput18Current 6097;
BA_ "SigType" SG_ 2566697982 FusedOutput17Current 1;
BA_ "SPN" SG_ 2566697982 FusedOutput17Current 6096;
BA_ "SigType" SG_ 2566697982 FusedOutput16Current 1;
BA_ "SPN" SG_ 2566697982 FusedOutput16Current 6095;
BA_ "SigType" SG_ 2566697982 FusedOutput15Current 1;
BA_ "SPN" SG_ 2566697982 FusedOutput15Current 6094;
BA_ "SigType" SG_ 2566697982 FusedOutput14Current 1;
BA_ "SPN" SG_ 2566697982 FusedOutput14Current 6093;
BA_ "SigType" SG_ 2566697982 FusedOutput13Current 1;
BA_ "SPN" SG_ 2566697982 FusedOutput13Current 6092;
BA_ "SigType" SG_ 2566697982 FusedOutput12Current 1;
BA_ "SPN" SG_ 2566697982 FusedOutput12Current 6091;
BA_ "SigType" SG_ 2566697982 FusedOutput11Current 1;
BA_ "SPN" SG_ 2566697982 FusedOutput11Current 6090;
BA_ "SigType" SG_ 2566697982 FusedOutput10Current 1;
BA_ "SPN" SG_ 2566697982 FusedOutput10Current 6089;
BA_ "SigType" SG_ 2566697982 FusedOutput9Current 1;
BA_ "SPN" SG_ 2566697982 FusedOutput9Current 6088;
BA_ "SigType" SG_ 2566697982 FusedOutput8Current 1;
BA_ "SPN" SG_ 2566697982 FusedOutput8Current 6087;
BA_ "SigType" SG_ 2566697982 FusedOutput7Current 1;
BA_ "SPN" SG_ 2566697982 FusedOutput7Current 6086;
BA_ "SigType" SG_ 2566697982 FusedOutput6Current 1;
BA_ "SPN" SG_ 2566697982 FusedOutput6Current 6085;
BA_ "SigType" SG_ 2566697982 FusedOutput5Current 1;
BA_ "SPN" SG_ 2566697982 FusedOutput5Current 6084;
BA_ "SigType" SG_ 2566697982 FusedOutput4Current 1;
BA_ "SPN" SG_ 2566697982 FusedOutput4Current 6083;
BA_ "SigType" SG_ 2566697982 FusedOutput3Current 1;
BA_ "SPN" SG_ 2566697982 FusedOutput3Current 6082;
BA_ "SigType" SG_ 2566697982 FusedOutput2Current 1;
BA_ "SPN" SG_ 2566697982 FusedOutput2Current 6081;
BA_ "SigType" SG_ 2566697982 FusedOutput1Current 1;
BA_ "SPN" SG_ 2566697982 FusedOutput1Current 6080;
BA_ "SigType" SG_ 2566697726 SwitchedOutput32Current 1;
BA_ "SPN" SG_ 2566697726 SwitchedOutput32Current 6143;
BA_ "SigType" SG_ 2566697726 SwitchedOutput31Current 1;
BA_ "SPN" SG_ 2566697726 SwitchedOutput31Current 6142;
BA_ "SigType" SG_ 2566697726 SwitchedOutput30Current 1;
BA_ "SPN" SG_ 2566697726 SwitchedOutput30Current 6141;
BA_ "SigType" SG_ 2566697726 SwitchedOutput29Current 1;
BA_ "SPN" SG_ 2566697726 SwitchedOutput29Current 6140;
BA_ "SigType" SG_ 2566697726 SwitchedOutput28Current 1;
BA_ "SPN" SG_ 2566697726 SwitchedOutput28Current 6139;
BA_ "SigType" SG_ 2566697726 SwitchedOutput27Current 1;
BA_ "SPN" SG_ 2566697726 SwitchedOutput27Current 6138;
BA_ "SigType" SG_ 2566697726 SwitchedOutput26Current 1;
BA_ "SPN" SG_ 2566697726 SwitchedOutput26Current 6137;
BA_ "SigType" SG_ 2566697726 SwitchedOutput25Current 1;
BA_ "SPN" SG_ 2566697726 SwitchedOutput25Current 6136;
BA_ "SigType" SG_ 2566697726 SwitchedOutput24Current 1;
BA_ "SPN" SG_ 2566697726 SwitchedOutput24Current 6135;
BA_ "SigType" SG_ 2566697726 SwitchedOutput23Current 1;
BA_ "SPN" SG_ 2566697726 SwitchedOutput23Current 6134;
BA_ "SigType" SG_ 2566697726 SwitchedOutput22Current 1;
BA_ "SPN" SG_ 2566697726 SwitchedOutput22Current 6133;
BA_ "SigType" SG_ 2566697726 SwitchedOutput21Current 1;
BA_ "SPN" SG_ 2566697726 SwitchedOutput21Current 6132;
BA_ "SigType" SG_ 2566697726 SwitchedOutput20Current 1;
BA_ "SPN" SG_ 2566697726 SwitchedOutput20Current 6131;
BA_ "SigType" SG_ 2566697726 SwitchedOutput19Current 1;
BA_ "SPN" SG_ 2566697726 SwitchedOutput19Current 6130;
BA_ "SigType" SG_ 2566697726 SwitchedOutput18Current 1;
BA_ "SPN" SG_ 2566697726 SwitchedOutput18Current 6129;
BA_ "SigType" SG_ 2566697726 SwitchedOutput17Current 1;
BA_ "SPN" SG_ 2566697726 SwitchedOutput17Current 6128;
BA_ "SigType" SG_ 2566697726 SwitchedOutput16Current 1;
BA_ "SPN" SG_ 2566697726 SwitchedOutput16Current 6127;
BA_ "SigType" SG_ 2566697726 SwitchedOutput15Current 1;
BA_ "SPN" SG_ 2566697726 SwitchedOutput15Current 6126;
BA_ "SigType" SG_ 2566697726 SwitchedOutput14Current 1;
BA_ "SPN" SG_ 2566697726 SwitchedOutput14Current 6125;
BA_ "SigType" SG_ 2566697726 SwitchedOutput13Current 1;
BA_ "SPN" SG_ 2566697726 SwitchedOutput13Current 6124;
BA_ "SigType" SG_ 2566697726 SwitchedOutput12Current 1;
BA_ "SPN" SG_ 2566697726 SwitchedOutput12Current 6123;
BA_ "SigType" SG_ 2566697726 SwitchedOutput11Current 1;
BA_ "SPN" SG_ 2566697726 SwitchedOutput11Current 6122;
BA_ "SigType" SG_ 2566697726 SwitchedOutput10Current 1;
BA_ "SPN" SG_ 2566697726 SwitchedOutput10Current 6121;
BA_ "SigType" SG_ 2566697726 SwitchedOutput9Current 1;
BA_ "SPN" SG_ 2566697726 SwitchedOutput9Current 6120;
BA_ "SigType" SG_ 2566697726 SwitchedOutput8Current 1;
BA_ "SPN" SG_ 2566697726 SwitchedOutput8Current 6119;
BA_ "SigType" SG_ 2566697726 SwitchedOutput7Current 1;
BA_ "SPN" SG_ 2566697726 SwitchedOutput7Current 6118;
BA_ "SigType" SG_ 2566697726 SwitchedOutput6Current 1;
BA_ "SPN" SG_ 2566697726 SwitchedOutput6Current 6117;
BA_ "SigType" SG_ 2566697726 SwitchedOutput5Current 1;
BA_ "SPN" SG_ 2566697726 SwitchedOutput5Current 6116;
BA_ "SigType" SG_ 2566697726 SwitchedOutput4Current 1;
BA_ "SPN" SG_ 2566697726 SwitchedOutput4Current 6115;
BA_ "SigType" SG_ 2566697726 SwitchedOutput3Current 1;
BA_ "SPN" SG_ 2566697726 SwitchedOutput3Current 6114;
BA_ "SigType" SG_ 2566697726 SwitchedOutput2Current 1;
BA_ "SPN" SG_ 2566697726 SwitchedOutput2Current 6113;
BA_ "SigType" SG_ 2566697726 SwitchedOutput1Current 1;
BA_ "SPN" SG_ 2566697726 SwitchedOutput1Current 6112;
BA_ "SPN" SG_ 2566697470 EngIgntCtrlModule2State 6217;
BA_ "SPN" SG_ 2566697470 EngIgntCtrlModule1State 6216;
BA_ "SigType" SG_ 2566697470 EngIgntCtrlModule2Temp 1;
BA_ "SPN" SG_ 2566697470 EngIgntCtrlModule2Temp 6215;
BA_ "SigType" SG_ 2566697470 EngIgntCtrlModule1Temp 1;
BA_ "SPN" SG_ 2566697470 EngIgntCtrlModule1Temp 6214;
BA_ "SigType" SG_ 2633806078 EngIgntCtrlModule2TimeRemaining 1;
BA_ "SPN" SG_ 2633806078 EngIgntCtrlModule2TimeRemaining 6221;
BA_ "SigType" SG_ 2633806078 EngIgntCtrlModule1TimeRemaining 1;
BA_ "SPN" SG_ 2633806078 EngIgntCtrlModule1TimeRemaining 6220;
BA_ "SigType" SG_ 2633805822 EngSparkPlug4MinVoltage 1;
BA_ "SPN" SG_ 2633805822 EngSparkPlug4MinVoltage 6225;
BA_ "SigType" SG_ 2633805822 EngSparkPlug3MinVoltage 1;
BA_ "SPN" SG_ 2633805822 EngSparkPlug3MinVoltage 6224;
BA_ "SigType" SG_ 2633805822 EngSparkPlug2MinVoltage 1;
BA_ "SPN" SG_ 2633805822 EngSparkPlug2MinVoltage 6223;
BA_ "SigType" SG_ 2633805822 EngSparkPlug1MinVoltage 1;
BA_ "SPN" SG_ 2633805822 EngSparkPlug1MinVoltage 6222;
BA_ "SigType" SG_ 2633805566 EngSparkPlug8MinVoltage 1;
BA_ "SPN" SG_ 2633805566 EngSparkPlug8MinVoltage 6229;
BA_ "SigType" SG_ 2633805566 EngSparkPlug7MinVoltage 1;
BA_ "SPN" SG_ 2633805566 EngSparkPlug7MinVoltage 6228;
BA_ "SigType" SG_ 2633805566 EngSparkPlug6MinVoltage 1;
BA_ "SPN" SG_ 2633805566 EngSparkPlug6MinVoltage 6227;
BA_ "SigType" SG_ 2633805566 EngSparkPlug5MinVoltage 1;
BA_ "SPN" SG_ 2633805566 EngSparkPlug5MinVoltage 6226;
BA_ "SigType" SG_ 2633805310 EngSparkPlug12MinVoltage 1;
BA_ "SPN" SG_ 2633805310 EngSparkPlug12MinVoltage 6233;
BA_ "SigType" SG_ 2633805310 EngSparkPlug11MinVoltage 1;
BA_ "SPN" SG_ 2633805310 EngSparkPlug11MinVoltage 6232;
BA_ "SigType" SG_ 2633805310 EngSparkPlug10MinVoltage 1;
BA_ "SPN" SG_ 2633805310 EngSparkPlug10MinVoltage 6231;
BA_ "SigType" SG_ 2633805310 EngSparkPlug9MinVoltage 1;
BA_ "SPN" SG_ 2633805310 EngSparkPlug9MinVoltage 6230;
BA_ "SigType" SG_ 2633805054 EngSparkPlug16MinVoltage 1;
BA_ "SPN" SG_ 2633805054 EngSparkPlug16MinVoltage 6237;
BA_ "SigType" SG_ 2633805054 EngSparkPlug15MinVoltage 1;
BA_ "SPN" SG_ 2633805054 EngSparkPlug15MinVoltage 6236;
BA_ "SigType" SG_ 2633805054 EngSparkPlug14MinVoltage 1;
BA_ "SPN" SG_ 2633805054 EngSparkPlug14MinVoltage 6235;
BA_ "SigType" SG_ 2633805054 EngSparkPlug13MinVoltage 1;
BA_ "SPN" SG_ 2633805054 EngSparkPlug13MinVoltage 6234;
BA_ "SigType" SG_ 2633804798 EngSparkPlug20MinVoltage 1;
BA_ "SPN" SG_ 2633804798 EngSparkPlug20MinVoltage 6241;
BA_ "SigType" SG_ 2633804798 EngSparkPlug19MinVoltage 1;
BA_ "SPN" SG_ 2633804798 EngSparkPlug19MinVoltage 6240;
BA_ "SigType" SG_ 2633804798 EngSparkPlug18MinVoltage 1;
BA_ "SPN" SG_ 2633804798 EngSparkPlug18MinVoltage 6239;
BA_ "SigType" SG_ 2633804798 EngSparkPlug17MinVoltage 1;
BA_ "SPN" SG_ 2633804798 EngSparkPlug17MinVoltage 6238;
BA_ "SigType" SG_ 2633804542 EngSparkPlug24MinVoltage 1;
BA_ "SPN" SG_ 2633804542 EngSparkPlug24MinVoltage 6245;
BA_ "SigType" SG_ 2633804542 EngSparkPlug23MinVoltage 1;
BA_ "SPN" SG_ 2633804542 EngSparkPlug23MinVoltage 6244;
BA_ "SigType" SG_ 2633804542 EngSparkPlug22MinVoltage 1;
BA_ "SPN" SG_ 2633804542 EngSparkPlug22MinVoltage 6243;
BA_ "SigType" SG_ 2633804542 EngSparkPlug21MinVoltage 1;
BA_ "SPN" SG_ 2633804542 EngSparkPlug21MinVoltage 6242;
BA_ "SigType" SG_ 2633804286 EngSparkPlug4MaxVoltage 1;
BA_ "SPN" SG_ 2633804286 EngSparkPlug4MaxVoltage 6249;
BA_ "SigType" SG_ 2633804286 EngSparkPlug3MaxVoltage 1;
BA_ "SPN" SG_ 2633804286 EngSparkPlug3MaxVoltage 6248;
BA_ "SigType" SG_ 2633804286 EngSparkPlug2MaxVoltage 1;
BA_ "SPN" SG_ 2633804286 EngSparkPlug2MaxVoltage 6247;
BA_ "SigType" SG_ 2633804286 EngSparkPlug1MaxVoltage 1;
BA_ "SPN" SG_ 2633804286 EngSparkPlug1MaxVoltage 6246;
BA_ "SigType" SG_ 2633804030 EngSparkPlug8MaxVoltage 1;
BA_ "SPN" SG_ 2633804030 EngSparkPlug8MaxVoltage 6253;
BA_ "SigType" SG_ 2633804030 EngSparkPlug7MaxVoltage 1;
BA_ "SPN" SG_ 2633804030 EngSparkPlug7MaxVoltage 6252;
BA_ "SigType" SG_ 2633804030 EngSparkPlug6MaxVoltage 1;
BA_ "SPN" SG_ 2633804030 EngSparkPlug6MaxVoltage 6251;
BA_ "SigType" SG_ 2633804030 EngSparkPlug5MaxVoltage 1;
BA_ "SPN" SG_ 2633804030 EngSparkPlug5MaxVoltage 6250;
BA_ "SigType" SG_ 2633803774 EngSparkPlug12MaxVoltage 1;
BA_ "SPN" SG_ 2633803774 EngSparkPlug12MaxVoltage 6257;
BA_ "SigType" SG_ 2633803774 EngSparkPlug11MaxVoltage 1;
BA_ "SPN" SG_ 2633803774 EngSparkPlug11MaxVoltage 6256;
BA_ "SigType" SG_ 2633803774 EngSparkPlug10MaxVoltage 1;
BA_ "SPN" SG_ 2633803774 EngSparkPlug10MaxVoltage 6255;
BA_ "SigType" SG_ 2633803774 EngSparkPlug9MaxVoltage 1;
BA_ "SPN" SG_ 2633803774 EngSparkPlug9MaxVoltage 6254;
BA_ "SigType" SG_ 2633803518 EngSparkPlug16MaxVoltage 1;
BA_ "SPN" SG_ 2633803518 EngSparkPlug16MaxVoltage 6261;
BA_ "SigType" SG_ 2633803518 EngSparkPlug15MaxVoltage 1;
BA_ "SPN" SG_ 2633803518 EngSparkPlug15MaxVoltage 6260;
BA_ "SigType" SG_ 2633803518 EngSparkPlug14MaxVoltage 1;
BA_ "SPN" SG_ 2633803518 EngSparkPlug14MaxVoltage 6259;
BA_ "SigType" SG_ 2633803518 EngSparkPlug13MaxVoltage 1;
BA_ "SPN" SG_ 2633803518 EngSparkPlug13MaxVoltage 6258;
BA_ "SigType" SG_ 2633803262 EngSparkPlug20MaxVoltage 1;
BA_ "SPN" SG_ 2633803262 EngSparkPlug20MaxVoltage 6265;
BA_ "SigType" SG_ 2633803262 EngSparkPlug19MaxVoltage 1;
BA_ "SPN" SG_ 2633803262 EngSparkPlug19MaxVoltage 6264;
BA_ "SigType" SG_ 2633803262 EngSparkPlug18MaxVoltage 1;
BA_ "SPN" SG_ 2633803262 EngSparkPlug18MaxVoltage 6263;
BA_ "SigType" SG_ 2633803262 EngSparkPlug17MaxVoltage 1;
BA_ "SPN" SG_ 2633803262 EngSparkPlug17MaxVoltage 6262;
BA_ "SigType" SG_ 2633803006 EngSparkPlug24MaxVoltage 1;
BA_ "SPN" SG_ 2633803006 EngSparkPlug24MaxVoltage 6269;
BA_ "SigType" SG_ 2633803006 EngSparkPlug23MaxVoltage 1;
BA_ "SPN" SG_ 2633803006 EngSparkPlug23MaxVoltage 6268;
BA_ "SigType" SG_ 2633803006 EngSparkPlug22MaxVoltage 1;
BA_ "SPN" SG_ 2633803006 EngSparkPlug22MaxVoltage 6267;
BA_ "SigType" SG_ 2633803006 EngSparkPlug21MaxVoltage 1;
BA_ "SPN" SG_ 2633803006 EngSparkPlug21MaxVoltage 6266;
BA_ "SigType" SG_ 2633802750 EngSparkPlug8MisfireRate 1;
BA_ "SPN" SG_ 2633802750 EngSparkPlug8MisfireRate 6277;
BA_ "SigType" SG_ 2633802750 EngSparkPlug7MisfireRate 1;
BA_ "SPN" SG_ 2633802750 EngSparkPlug7MisfireRate 6276;
BA_ "SigType" SG_ 2633802750 EngSparkPlug6MisfireRate 1;
BA_ "SPN" SG_ 2633802750 EngSparkPlug6MisfireRate 6275;
BA_ "SigType" SG_ 2633802750 EngSparkPlug5MisfireRate 1;
BA_ "SPN" SG_ 2633802750 EngSparkPlug5MisfireRate 6274;
BA_ "SigType" SG_ 2633802750 EngSparkPlug4MisfireRate 1;
BA_ "SPN" SG_ 2633802750 EngSparkPlug4MisfireRate 6273;
BA_ "SigType" SG_ 2633802750 EngSparkPlug3MisfireRate 1;
BA_ "SPN" SG_ 2633802750 EngSparkPlug3MisfireRate 6272;
BA_ "SigType" SG_ 2633802750 EngSparkPlug2MisfireRate 1;
BA_ "SPN" SG_ 2633802750 EngSparkPlug2MisfireRate 6271;
BA_ "SigType" SG_ 2633802750 EngSparkPlug1MisfireRate 1;
BA_ "SPN" SG_ 2633802750 EngSparkPlug1MisfireRate 6270;
BA_ "SigType" SG_ 2633802494 EngSparkPlug16MisfireRate 1;
BA_ "SPN" SG_ 2633802494 EngSparkPlug16MisfireRate 6285;
BA_ "SigType" SG_ 2633802494 EngSparkPlug15MisfireRate 1;
BA_ "SPN" SG_ 2633802494 EngSparkPlug15MisfireRate 6284;
BA_ "SigType" SG_ 2633802494 EngSparkPlug14MisfireRate 1;
BA_ "SPN" SG_ 2633802494 EngSparkPlug14MisfireRate 6283;
BA_ "SigType" SG_ 2633802494 EngSparkPlug13MisfireRate 1;
BA_ "SPN" SG_ 2633802494 EngSparkPlug13MisfireRate 6282;
BA_ "SigType" SG_ 2633802494 EngSparkPlug12MisfireRate 1;
BA_ "SPN" SG_ 2633802494 EngSparkPlug12MisfireRate 6281;
BA_ "SigType" SG_ 2633802494 EngSparkPlug11MisfireRate 1;
BA_ "SPN" SG_ 2633802494 EngSparkPlug11MisfireRate 6280;
BA_ "SigType" SG_ 2633802494 EngSparkPlug10MisfireRate 1;
BA_ "SPN" SG_ 2633802494 EngSparkPlug10MisfireRate 6279;
BA_ "SigType" SG_ 2633802494 EngSparkPlug9MisfireRate 1;
BA_ "SPN" SG_ 2633802494 EngSparkPlug9MisfireRate 6278;
BA_ "SigType" SG_ 2633802238 EngSparkPlug24MisfireRate 1;
BA_ "SPN" SG_ 2633802238 EngSparkPlug24MisfireRate 6293;
BA_ "SigType" SG_ 2633802238 EngSparkPlug23MisfireRate 1;
BA_ "SPN" SG_ 2633802238 EngSparkPlug23MisfireRate 6292;
BA_ "SigType" SG_ 2633802238 EngSparkPlug22MisfireRate 1;
BA_ "SPN" SG_ 2633802238 EngSparkPlug22MisfireRate 6291;
BA_ "SigType" SG_ 2633802238 EngSparkPlug21MisfireRate 1;
BA_ "SPN" SG_ 2633802238 EngSparkPlug21MisfireRate 6290;
BA_ "SigType" SG_ 2633802238 EngSparkPlug20MisfireRate 1;
BA_ "SPN" SG_ 2633802238 EngSparkPlug20MisfireRate 6289;
BA_ "SigType" SG_ 2633802238 EngSparkPlug19MisfireRate 1;
BA_ "SPN" SG_ 2633802238 EngSparkPlug19MisfireRate 6288;
BA_ "SigType" SG_ 2633802238 EngSparkPlug18MisfireRate 1;
BA_ "SPN" SG_ 2633802238 EngSparkPlug18MisfireRate 6287;
BA_ "SigType" SG_ 2633802238 EngSparkPlug17MisfireRate 1;
BA_ "SPN" SG_ 2633802238 EngSparkPlug17MisfireRate 6286;
BA_ "SigType" SG_ 2633801982 EngTtlHoursOfDieselFuelOperation 1;
BA_ "SPN" SG_ 2633801982 EngTtlHoursOfDieselFuelOperation 6320;
BA_ "SigType" SG_ 2633801982 EngTotalHoursOfGasFuelOperation 1;
BA_ "SPN" SG_ 2633801982 EngTotalHoursOfGasFuelOperation 6319;
BA_ "SigType" SG_ 2566692862 DisplayRemainPowered 5;
BA_ "SPN" SG_ 2566692862 DisplayRemainPowered 6846;
BA_ "SigType" SG_ 2566692862 Fuel2Tank4Level 1;
BA_ "SPN" SG_ 2566692862 Fuel2Tank4Level 6645;
BA_ "SigType" SG_ 2566692862 Fuel2Tank3Level 1;
BA_ "SPN" SG_ 2566692862 Fuel2Tank3Level 6644;
BA_ "SigType" SG_ 2566692862 Fuel2Tank2Level 1;
BA_ "SPN" SG_ 2566692862 Fuel2Tank2Level 6643;
BA_ "SigType" SG_ 2566692862 Fuel2Tank1Level 1;
BA_ "SPN" SG_ 2566692862 Fuel2Tank1Level 6642;
BA_ "SigType" SG_ 2566692862 EngExRangeOilFilterDiffPress 1;
BA_ "SPN" SG_ 2566692862 EngExRangeOilFilterDiffPress 6321;
BA_ "SPN" SG_ 2499583742 EngTimingActuator2RequestedPos 6335;
BA_ "SPN" SG_ 2499583742 EngTimingActuator1RequestedPos 6334;
BA_ "SPN" SG_ 2499583742 EngTimingActuator2 1245;
BA_ "SPN" SG_ 2499583742 EngTimingActuator1 635;
BA_ "SPN" SG_ 2499583486 EngTimingActuator2PosCmd 6337;
BA_ "SPN" SG_ 2499583486 EngTimingActuator1PosCmd 6336;
BA_ "SigType" SG_ 2566692094 Joystick1Lamp10Status 5;
BA_ "SPN" SG_ 2566692094 Joystick1Lamp10Status 6347;
BA_ "SigType" SG_ 2566692094 Joystick1Lamp9Status 5;
BA_ "SPN" SG_ 2566692094 Joystick1Lamp9Status 6346;
BA_ "SigType" SG_ 2566692094 Joystick1Lamp8Status 5;
BA_ "SPN" SG_ 2566692094 Joystick1Lamp8Status 6345;
BA_ "SigType" SG_ 2566692094 Joystick1Lamp7Status 5;
BA_ "SPN" SG_ 2566692094 Joystick1Lamp7Status 6344;
BA_ "SigType" SG_ 2566692094 Joystick1Lamp6Status 5;
BA_ "SPN" SG_ 2566692094 Joystick1Lamp6Status 6343;
BA_ "SigType" SG_ 2566692094 Joystick1Lamp5Status 5;
BA_ "SPN" SG_ 2566692094 Joystick1Lamp5Status 6342;
BA_ "SigType" SG_ 2566692094 Joystick1Lamp4Status 5;
BA_ "SPN" SG_ 2566692094 Joystick1Lamp4Status 6341;
BA_ "SigType" SG_ 2566692094 Joystick1Lamp3Status 5;
BA_ "SPN" SG_ 2566692094 Joystick1Lamp3Status 6340;
BA_ "SigType" SG_ 2566692094 Joystick1Lamp2Status 5;
BA_ "SPN" SG_ 2566692094 Joystick1Lamp2Status 6339;
BA_ "SigType" SG_ 2566692094 Joystick1Lamp1Status 5;
BA_ "SPN" SG_ 2566692094 Joystick1Lamp1Status 6338;
BA_ "SigType" SG_ 2566691838 Joystick2Lamp10Status 5;
BA_ "SPN" SG_ 2566691838 Joystick2Lamp10Status 6357;
BA_ "SigType" SG_ 2566691838 Joystick2Lamp9Status 5;
BA_ "SPN" SG_ 2566691838 Joystick2Lamp9Status 6356;
BA_ "SigType" SG_ 2566691838 Joystick2Lamp8Status 5;
BA_ "SPN" SG_ 2566691838 Joystick2Lamp8Status 6355;
BA_ "SigType" SG_ 2566691838 Joystick2Lamp7Status 5;
BA_ "SPN" SG_ 2566691838 Joystick2Lamp7Status 6354;
BA_ "SigType" SG_ 2566691838 Joystick2Lamp6Status 5;
BA_ "SPN" SG_ 2566691838 Joystick2Lamp6Status 6353;
BA_ "SigType" SG_ 2566691838 Joystick2Lamp5Status 5;
BA_ "SPN" SG_ 2566691838 Joystick2Lamp5Status 6352;
BA_ "SigType" SG_ 2566691838 Joystick2Lamp4Status 5;
BA_ "SPN" SG_ 2566691838 Joystick2Lamp4Status 6351;
BA_ "SigType" SG_ 2566691838 Joystick2Lamp3Status 5;
BA_ "SPN" SG_ 2566691838 Joystick2Lamp3Status 6350;
BA_ "SigType" SG_ 2566691838 Joystick2Lamp2Status 5;
BA_ "SPN" SG_ 2566691838 Joystick2Lamp2Status 6349;
BA_ "SigType" SG_ 2566691838 Joystick2Lamp1Status 5;
BA_ "SPN" SG_ 2566691838 Joystick2Lamp1Status 6348;
BA_ "SigType" SG_ 2566691582 Joystick3Lamp10Status 5;
BA_ "SPN" SG_ 2566691582 Joystick3Lamp10Status 6367;
BA_ "SigType" SG_ 2566691582 Joystick3Lamp9Status 5;
BA_ "SPN" SG_ 2566691582 Joystick3Lamp9Status 6366;
BA_ "SigType" SG_ 2566691582 Joystick3Lamp8Status 5;
BA_ "SPN" SG_ 2566691582 Joystick3Lamp8Status 6365;
BA_ "SigType" SG_ 2566691582 Joystick3Lamp7Status 5;
BA_ "SPN" SG_ 2566691582 Joystick3Lamp7Status 6364;
BA_ "SigType" SG_ 2566691582 Joystick3Lamp6Status 5;
BA_ "SPN" SG_ 2566691582 Joystick3Lamp6Status 6363;
BA_ "SigType" SG_ 2566691582 Joystick3Lamp5Status 5;
BA_ "SPN" SG_ 2566691582 Joystick3Lamp5Status 6362;
BA_ "SigType" SG_ 2566691582 Joystick3Lamp4Status 5;
BA_ "SPN" SG_ 2566691582 Joystick3Lamp4Status 6361;
BA_ "SigType" SG_ 2566691582 Joystick3Lamp3Status 5;
BA_ "SPN" SG_ 2566691582 Joystick3Lamp3Status 6360;
BA_ "SigType" SG_ 2566691582 Joystick3Lamp2Status 5;
BA_ "SPN" SG_ 2566691582 Joystick3Lamp2Status 6359;
BA_ "SigType" SG_ 2566691582 Joystick3Lamp1Status 5;
BA_ "SPN" SG_ 2566691582 Joystick3Lamp1Status 6358;
BA_ "SigType" SG_ 2566691326 AssemblyUnitIdentification 8;
BA_ "SPN" SG_ 2566691326 AssemblyUnitIdentification 6369;
BA_ "SigType" SG_ 2566691326 NmbrOfAssmblyUntIdntfctionFields 1;
BA_ "SPN" SG_ 2566691326 NmbrOfAssmblyUntIdntfctionFields 6368;
BA_ "SigType" SG_ 2499582206 SftTpSpdLmtRmnngCntnsIntrvlDstnc 1;
BA_ "SPN" SG_ 2499582206 SftTpSpdLmtRmnngCntnsIntrvlDstnc 6914;
BA_ "SigType" SG_ 2499582206 SoftTopSpeedLimitResetDistance 1;
BA_ "SPN" SG_ 2499582206 SoftTopSpeedLimitResetDistance 6373;
BA_ "SigType" SG_ 2499582206 SftTpSpeedLimitRemainingDistance 1;
BA_ "SPN" SG_ 2499582206 SftTpSpeedLimitRemainingDistance 6372;
BA_ "SigType" SG_ 2499582206 SoftTopLifetimeLimitExceeded 5;
BA_ "SPN" SG_ 2499582206 SoftTopLifetimeLimitExceeded 6371;
BA_ "SigType" SG_ 2499582206 SoftTopSpeedLimitActive 5;
BA_ "SPN" SG_ 2499582206 SoftTopSpeedLimitActive 6370;
BA_ "SigType" SG_ 2566690814 CrabSteerModeActuatorState 4;
BA_ "SPN" SG_ 2566690814 CrabSteerModeActuatorState 6381;
BA_ "SigType" SG_ 2566690814 CircleSteerModeActuatorState 4;
BA_ "SPN" SG_ 2566690814 CircleSteerModeActuatorState 6380;
BA_ "SigType" SG_ 2566690814 VourWheelSteerActuatorState 4;
BA_ "SPN" SG_ 2566690814 VourWheelSteerActuatorState 6379;
BA_ "SigType" SG_ 2566690814 TwoWheelSteerActuatorState 4;
BA_ "SPN" SG_ 2566690814 TwoWheelSteerActuatorState 6378;
BA_ "SigType" SG_ 2566690814 RearSteerAxleCenteredStatus 5;
BA_ "SPN" SG_ 2566690814 RearSteerAxleCenteredStatus 6377;
BA_ "SigType" SG_ 2566690814 FrontSteerAxleCenteredStatus 5;
BA_ "SPN" SG_ 2566690814 FrontSteerAxleCenteredStatus 6376;
BA_ "SPN" SG_ 2566690814 SteerModeSwitch 6375;
BA_ "SigType" SG_ 2566690558 CommonRailOilAbsPress 1;
BA_ "SPN" SG_ 2566690558 CommonRailOilAbsPress 7721;
BA_ "SigType" SG_ 2566690558 CommonRailOilPress 1;
BA_ "SPN" SG_ 2566690558 CommonRailOilPress 7720;
BA_ "SigType" SG_ 2566690558 EngPreFilterOilPress 1;
BA_ "SPN" SG_ 2566690558 EngPreFilterOilPress 7470;
BA_ "SigType" SG_ 2566690558 EngExhaustPress1ExRange 1;
BA_ "SPN" SG_ 2566690558 EngExhaustPress1ExRange 6384;
BA_ "SPN" SG_ 2365363710 EngCylPrssMonitor2PreliminaryFMI 6391;
BA_ "SPN" SG_ 2365363710 EngCylPrssMonitor1PreliminaryFMI 6390;
BA_ "SigType" SG_ 2566690046 AfterrunCompleteThisCycle 4;
BA_ "SPN" SG_ 2566690046 AfterrunCompleteThisCycle 6482;
BA_ "SigType" SG_ 2566690046 DEFDoserPurgeCompleteLastCycle 4;
BA_ "SPN" SG_ 2566690046 DEFDoserPurgeCompleteLastCycle 6481;
BA_ "SigType" SG_ 2566690046 DEFDoserPurgeCompleteThisCycle 4;
BA_ "SPN" SG_ 2566690046 DEFDoserPurgeCompleteThisCycle 6480;
BA_ "SigType" SG_ 2566690046 DEFDoserCldnCompleteLastCycle 4;
BA_ "SPN" SG_ 2566690046 DEFDoserCldnCompleteLastCycle 6479;
BA_ "SigType" SG_ 2566690046 DEFDoserCldnCompleteThisCycle 4;
BA_ "SPN" SG_ 2566690046 DEFDoserCldnCompleteThisCycle 6478;
BA_ "SigType" SG_ 2566690046 DEFDoserPurgeInterruptCount 1;
BA_ "SPN" SG_ 2566690046 DEFDoserPurgeInterruptCount 6477;
BA_ "SigType" SG_ 2566690046 DEFDoserCldnInterruptCount 1;
BA_ "SPN" SG_ 2566690046 DEFDoserCldnInterruptCount 6476;
BA_ "SigType" SG_ 2566689790 EngPrechamberFuelDesiredAbsPress 1;
BA_ "SPN" SG_ 2566689790 EngPrechamberFuelDesiredAbsPress 6574;
BA_ "SigType" SG_ 2566689790 EngPrechamberFuelAbsPress 1;
BA_ "SPN" SG_ 2566689790 EngPrechamberFuelAbsPress 6573;
BA_ "SigType" SG_ 2566689790 EngMinChamberFuelDesiredAbsPress 1;
BA_ "SPN" SG_ 2566689790 EngMinChamberFuelDesiredAbsPress 6572;
BA_ "SigType" SG_ 2566689790 EngMainChamberFuelAbsPress 1;
BA_ "SPN" SG_ 2566689790 EngMainChamberFuelAbsPress 6571;
BA_ "SigType" SG_ 2566689534 EngPrechamberDesiredAirFuelRatio 1;
BA_ "SPN" SG_ 2566689534 EngPrechamberDesiredAirFuelRatio 6578;
BA_ "SigType" SG_ 2566689534 EngPrechamberAirFuelRatio 1;
BA_ "SPN" SG_ 2566689534 EngPrechamberAirFuelRatio 6577;
BA_ "SigType" SG_ 2566689534 EngMinChamberDesiredAirFuelRatio 1;
BA_ "SPN" SG_ 2566689534 EngMinChamberDesiredAirFuelRatio 6576;
BA_ "SigType" SG_ 2566689534 EngMainChamberAirFuelRatio 1;
BA_ "SPN" SG_ 2566689534 EngMainChamberAirFuelRatio 6575;
BA_ "SigType" SG_ 2566689278 EngExhaustDesiredNOx 1;
BA_ "SPN" SG_ 2566689278 EngExhaustDesiredNOx 6580;
BA_ "SigType" SG_ 2566689278 EngExhaustNOx 1;
BA_ "SPN" SG_ 2566689278 EngExhaustNOx 6579;
BA_ "SigType" SG_ 2499580158 EngInjectorMeteringRail2Press2 1;
BA_ "SPN" SG_ 2499580158 EngInjectorMeteringRail2Press2 6592;
BA_ "SigType" SG_ 2499580158 EngInjectorMeteringRail2Press1 1;
BA_ "SPN" SG_ 2499580158 EngInjectorMeteringRail2Press1 6591;
BA_ "SigType" SG_ 2499580158 EngInjectorMeteringRail1Press2 1;
BA_ "SPN" SG_ 2499580158 EngInjectorMeteringRail1Press2 6590;
BA_ "SigType" SG_ 2499580158 EngInjectorMeteringRail1Press1 1;
BA_ "SPN" SG_ 2499580158 EngInjectorMeteringRail1Press1 6589;
BA_ "SigType" SG_ 2432471038 GasFuelAccumulatorTemp 1;
BA_ "SPN" SG_ 2432471038 GasFuelAccumulatorTemp 6815;
BA_ "SigType" SG_ 2432471038 EngFuelVaporizer1DischargeTemp 1;
BA_ "SPN" SG_ 2432471038 EngFuelVaporizer1DischargeTemp 6610;
BA_ "SigType" SG_ 2432471038 EngGasFuelSupplyPress 1;
BA_ "SPN" SG_ 2432471038 EngGasFuelSupplyPress 6646;
BA_ "SigType" SG_ 2566688254 ProductIdentificationModel 8;
BA_ "SPN" SG_ 2566688254 ProductIdentificationModel 6701;
BA_ "SigType" SG_ 2566688254 ProductIdentificationBrand 8;
BA_ "SPN" SG_ 2566688254 ProductIdentificationBrand 6700;
BA_ "SigType" SG_ 2566688254 ProductIdentificationCode 8;
BA_ "SPN" SG_ 2566688254 ProductIdentificationCode 6699;
BA_ "SigType" SG_ 2364567038 EngGsFlVlve20StartOfActuationCmd 1;
BA_ "SPN" SG_ 2364567038 EngGsFlVlve20StartOfActuationCmd 6697;
BA_ "SigType" SG_ 2364567038 EngGsFlVlve19StartOfActuationCmd 1;
BA_ "SPN" SG_ 2364567038 EngGsFlVlve19StartOfActuationCmd 6696;
BA_ "SigType" SG_ 2364567038 EngGsFlVlve18StartOfActuationCmd 1;
BA_ "SPN" SG_ 2364567038 EngGsFlVlve18StartOfActuationCmd 6695;
BA_ "SigType" SG_ 2364567038 EngGsFlVlve17StartOfActuationCmd 1;
BA_ "SPN" SG_ 2364567038 EngGsFlVlve17StartOfActuationCmd 6694;
BA_ "SigType" SG_ 2364566782 EngGsFlVlve16StartOfActuationCmd 1;
BA_ "SPN" SG_ 2364566782 EngGsFlVlve16StartOfActuationCmd 6693;
BA_ "SigType" SG_ 2364566782 EngGsFlVlve15StartOfActuationCmd 1;
BA_ "SPN" SG_ 2364566782 EngGsFlVlve15StartOfActuationCmd 6692;
BA_ "SigType" SG_ 2364566782 EngGsFlVlve14StartOfActuationCmd 1;
BA_ "SPN" SG_ 2364566782 EngGsFlVlve14StartOfActuationCmd 6691;
BA_ "SigType" SG_ 2364566782 EngGsFlVlve13StartOfActuationCmd 1;
BA_ "SPN" SG_ 2364566782 EngGsFlVlve13StartOfActuationCmd 6690;
BA_ "SigType" SG_ 2364566526 EngGsFlVlve12StartOfActuationCmd 1;
BA_ "SPN" SG_ 2364566526 EngGsFlVlve12StartOfActuationCmd 6689;
BA_ "SigType" SG_ 2364566526 EngGsFlVlve11StartOfActuationCmd 1;
BA_ "SPN" SG_ 2364566526 EngGsFlVlve11StartOfActuationCmd 6688;
BA_ "SigType" SG_ 2364566526 EngGsFlVlve10StartOfActuationCmd 1;
BA_ "SPN" SG_ 2364566526 EngGsFlVlve10StartOfActuationCmd 6687;
BA_ "SigType" SG_ 2364566526 EngGsFlValve9StartOfActuationCmd 1;
BA_ "SPN" SG_ 2364566526 EngGsFlValve9StartOfActuationCmd 6686;
BA_ "SigType" SG_ 2364566270 EngGsFlValve8StartOfActuationCmd 1;
BA_ "SPN" SG_ 2364566270 EngGsFlValve8StartOfActuationCmd 6685;
BA_ "SigType" SG_ 2364566270 EngGsFlValve7StartOfActuationCmd 1;
BA_ "SPN" SG_ 2364566270 EngGsFlValve7StartOfActuationCmd 6684;
BA_ "SigType" SG_ 2364566270 EngGsFlValve6StartOfActuationCmd 1;
BA_ "SPN" SG_ 2364566270 EngGsFlValve6StartOfActuationCmd 6683;
BA_ "SigType" SG_ 2364566270 EngGsFlValve5StartOfActuationCmd 1;
BA_ "SPN" SG_ 2364566270 EngGsFlValve5StartOfActuationCmd 6682;
BA_ "SigType" SG_ 2364566014 EngGsFlValve4StartOfActuationCmd 1;
BA_ "SPN" SG_ 2364566014 EngGsFlValve4StartOfActuationCmd 6681;
BA_ "SigType" SG_ 2364566014 EngGsFlValve3StartOfActuationCmd 1;
BA_ "SPN" SG_ 2364566014 EngGsFlValve3StartOfActuationCmd 6680;
BA_ "SigType" SG_ 2364566014 EngGsFlValve2StartOfActuationCmd 1;
BA_ "SPN" SG_ 2364566014 EngGsFlValve2StartOfActuationCmd 6679;
BA_ "SigType" SG_ 2364566014 EngGsFlValve1StartOfActuationCmd 1;
BA_ "SPN" SG_ 2364566014 EngGsFlValve1StartOfActuationCmd 6678;
BA_ "SigType" SG_ 2364565758 EngGasFuelValve20DurationCmd 1;
BA_ "SPN" SG_ 2364565758 EngGasFuelValve20DurationCmd 6677;
BA_ "SigType" SG_ 2364565758 EngGasFuelValve19DurationCmd 1;
BA_ "SPN" SG_ 2364565758 EngGasFuelValve19DurationCmd 6676;
BA_ "SigType" SG_ 2364565758 EngGasFuelValve18DurationCmd 1;
BA_ "SPN" SG_ 2364565758 EngGasFuelValve18DurationCmd 6675;
BA_ "SigType" SG_ 2364565758 EngGasFuelValve17DurationCmd 1;
BA_ "SPN" SG_ 2364565758 EngGasFuelValve17DurationCmd 6674;
BA_ "SigType" SG_ 2364565502 EngGasFuelValve16DurationCmd 1;
BA_ "SPN" SG_ 2364565502 EngGasFuelValve16DurationCmd 6673;
BA_ "SigType" SG_ 2364565502 EngGasFuelValve15DurationCmd 1;
BA_ "SPN" SG_ 2364565502 EngGasFuelValve15DurationCmd 6672;
BA_ "SigType" SG_ 2364565502 EngGasFuelValve14DurationCmd 1;
BA_ "SPN" SG_ 2364565502 EngGasFuelValve14DurationCmd 6671;
BA_ "SigType" SG_ 2364565502 EngGasFuelValve13DurationCmd 1;
BA_ "SPN" SG_ 2364565502 EngGasFuelValve13DurationCmd 6670;
BA_ "SigType" SG_ 2364565246 EngGasFuelValve12DurationCmd 1;
BA_ "SPN" SG_ 2364565246 EngGasFuelValve12DurationCmd 6669;
BA_ "SigType" SG_ 2364565246 EngGasFuelValve11DurationCmd 1;
BA_ "SPN" SG_ 2364565246 EngGasFuelValve11DurationCmd 6668;
BA_ "SigType" SG_ 2364565246 EngGasFuelValve10DurationCmd 1;
BA_ "SPN" SG_ 2364565246 EngGasFuelValve10DurationCmd 6667;
BA_ "SigType" SG_ 2364565246 EngGasFuelValve9DurationCmd 1;
BA_ "SPN" SG_ 2364565246 EngGasFuelValve9DurationCmd 6666;
BA_ "SigType" SG_ 2364564990 EngGasFuelValve8DurationCmd 1;
BA_ "SPN" SG_ 2364564990 EngGasFuelValve8DurationCmd 6665;
BA_ "SigType" SG_ 2364564990 EngGasFuelValve7DurationCmd 1;
BA_ "SPN" SG_ 2364564990 EngGasFuelValve7DurationCmd 6664;
BA_ "SigType" SG_ 2364564990 EngGasFuelValve6DurationCmd 1;
BA_ "SPN" SG_ 2364564990 EngGasFuelValve6DurationCmd 6663;
BA_ "SigType" SG_ 2364564990 EngGasFuelValve5DurationCmd 1;
BA_ "SPN" SG_ 2364564990 EngGasFuelValve5DurationCmd 6662;
BA_ "SigType" SG_ 2364564734 EngGasFuelValve4DurationCmd 1;
BA_ "SPN" SG_ 2364564734 EngGasFuelValve4DurationCmd 6661;
BA_ "SigType" SG_ 2364564734 EngGasFuelValve3DurationCmd 1;
BA_ "SPN" SG_ 2364564734 EngGasFuelValve3DurationCmd 6660;
BA_ "SigType" SG_ 2364564734 EngGasFuelValve2DurationCmd 1;
BA_ "SPN" SG_ 2364564734 EngGasFuelValve2DurationCmd 6659;
BA_ "SigType" SG_ 2364564734 EngGasFuelValve1DurationCmd 1;
BA_ "SPN" SG_ 2364564734 EngGasFuelValve1DurationCmd 6658;
BA_ "SigType" SG_ 2364564478 EngGsFlVlvNmnlStrtOfActuationCmd 1;
BA_ "SPN" SG_ 2364564478 EngGsFlVlvNmnlStrtOfActuationCmd 6657;
BA_ "SigType" SG_ 2364564478 EngGsFuelValveNominalDurationCmd 1;
BA_ "SPN" SG_ 2364564478 EngGsFuelValveNominalDurationCmd 6656;
BA_ "SigType" SG_ 2297455358 TransDirectionalOutputShaftSpeed 1;
BA_ "SPN" SG_ 2297455358 TransDirectionalOutputShaftSpeed 6585;
BA_ "SigType" SG_ 2297455358 TransHydrostaticLoop2Press 1;
BA_ "SPN" SG_ 2297455358 TransHydrostaticLoop2Press 6584;
BA_ "SigType" SG_ 2297455358 TransHydrostaticLoop1Press 1;
BA_ "SPN" SG_ 2297455358 TransHydrostaticLoop1Press 6583;
BA_ "SigType" SG_ 2498781694 EngCyl20AvrageCombustionDuration 1;
BA_ "SPN" SG_ 2498781694 EngCyl20AvrageCombustionDuration 6562;
BA_ "SigType" SG_ 2498781694 EngCyl20AvrgCntrOfCmbstionTiming 1;
BA_ "SPN" SG_ 2498781694 EngCyl20AvrgCntrOfCmbstionTiming 6561;
BA_ "SigType" SG_ 2498781694 EngCyl20AvrgStrtOfCmbstionTiming 1;
BA_ "SPN" SG_ 2498781694 EngCyl20AvrgStrtOfCmbstionTiming 6560;
BA_ "SigType" SG_ 2498781694 EngCyl20IndctdMeanEffectivePress 1;
BA_ "SPN" SG_ 2498781694 EngCyl20IndctdMeanEffectivePress 6559;
BA_ "SigType" SG_ 2498781438 EngCyl19AvrageCombustionDuration 1;
BA_ "SPN" SG_ 2498781438 EngCyl19AvrageCombustionDuration 6558;
BA_ "SigType" SG_ 2498781438 EngCyl19AvrgCntrOfCmbstionTiming 1;
BA_ "SPN" SG_ 2498781438 EngCyl19AvrgCntrOfCmbstionTiming 6557;
BA_ "SigType" SG_ 2498781438 EngCyl19AvrgStrtOfCmbstionTiming 1;
BA_ "SPN" SG_ 2498781438 EngCyl19AvrgStrtOfCmbstionTiming 6556;
BA_ "SigType" SG_ 2498781438 EngCyl19IndctdMeanEffectivePress 1;
BA_ "SPN" SG_ 2498781438 EngCyl19IndctdMeanEffectivePress 6555;
BA_ "SigType" SG_ 2498781182 EngCyl18AvrageCombustionDuration 1;
BA_ "SPN" SG_ 2498781182 EngCyl18AvrageCombustionDuration 6554;
BA_ "SigType" SG_ 2498781182 EngCyl18AvrgCntrOfCmbstionTiming 1;
BA_ "SPN" SG_ 2498781182 EngCyl18AvrgCntrOfCmbstionTiming 6553;
BA_ "SigType" SG_ 2498781182 EngCyl18AvrgStrtOfCmbstionTiming 1;
BA_ "SPN" SG_ 2498781182 EngCyl18AvrgStrtOfCmbstionTiming 6552;
BA_ "SigType" SG_ 2498781182 EngCyl18IndctdMeanEffectivePress 1;
BA_ "SPN" SG_ 2498781182 EngCyl18IndctdMeanEffectivePress 6551;
BA_ "SigType" SG_ 2498780926 EngCyl17AvrageCombustionDuration 1;
BA_ "SPN" SG_ 2498780926 EngCyl17AvrageCombustionDuration 6550;
BA_ "SigType" SG_ 2498780926 EngCyl17AvrgCntrOfCmbstionTiming 1;
BA_ "SPN" SG_ 2498780926 EngCyl17AvrgCntrOfCmbstionTiming 6549;
BA_ "SigType" SG_ 2498780926 EngCyl17AvrgStrtOfCmbstionTiming 1;
BA_ "SPN" SG_ 2498780926 EngCyl17AvrgStrtOfCmbstionTiming 6548;
BA_ "SigType" SG_ 2498780926 EngCyl17IndctdMeanEffectivePress 1;
BA_ "SPN" SG_ 2498780926 EngCyl17IndctdMeanEffectivePress 6547;
BA_ "SigType" SG_ 2498780670 EngCyl16AvrageCombustionDuration 1;
BA_ "SPN" SG_ 2498780670 EngCyl16AvrageCombustionDuration 6546;
BA_ "SigType" SG_ 2498780670 EngCyl16AvrgCntrOfCmbstionTiming 1;
BA_ "SPN" SG_ 2498780670 EngCyl16AvrgCntrOfCmbstionTiming 6545;
BA_ "SigType" SG_ 2498780670 EngCyl16AvrgStrtOfCmbstionTiming 1;
BA_ "SPN" SG_ 2498780670 EngCyl16AvrgStrtOfCmbstionTiming 6544;
BA_ "SigType" SG_ 2498780670 EngCyl16IndctdMeanEffectivePress 1;
BA_ "SPN" SG_ 2498780670 EngCyl16IndctdMeanEffectivePress 6543;
BA_ "SigType" SG_ 2498780414 EngCyl15AvrageCombustionDuration 1;
BA_ "SPN" SG_ 2498780414 EngCyl15AvrageCombustionDuration 6542;
BA_ "SigType" SG_ 2498780414 EngCyl15AvrgCntrOfCmbstionTiming 1;
BA_ "SPN" SG_ 2498780414 EngCyl15AvrgCntrOfCmbstionTiming 6541;
BA_ "SigType" SG_ 2498780414 EngCyl15AvrgStrtOfCmbstionTiming 1;
BA_ "SPN" SG_ 2498780414 EngCyl15AvrgStrtOfCmbstionTiming 6540;
BA_ "SigType" SG_ 2498780414 EngCyl15IndctdMeanEffectivePress 1;
BA_ "SPN" SG_ 2498780414 EngCyl15IndctdMeanEffectivePress 6539;
BA_ "SigType" SG_ 2498780158 EngCyl14AvrageCombustionDuration 1;
BA_ "SPN" SG_ 2498780158 EngCyl14AvrageCombustionDuration 6538;
BA_ "SigType" SG_ 2498780158 EngCyl14AvrgCntrOfCmbstionTiming 1;
BA_ "SPN" SG_ 2498780158 EngCyl14AvrgCntrOfCmbstionTiming 6537;
BA_ "SigType" SG_ 2498780158 EngCyl14AvrgStrtOfCmbstionTiming 1;
BA_ "SPN" SG_ 2498780158 EngCyl14AvrgStrtOfCmbstionTiming 6536;
BA_ "SigType" SG_ 2498780158 EngCyl14IndctdMeanEffectivePress 1;
BA_ "SPN" SG_ 2498780158 EngCyl14IndctdMeanEffectivePress 6535;
BA_ "SigType" SG_ 2498779902 EngCyl13AvrageCombustionDuration 1;
BA_ "SPN" SG_ 2498779902 EngCyl13AvrageCombustionDuration 6534;
BA_ "SigType" SG_ 2498779902 EngCyl13AvrgCntrOfCmbstionTiming 1;
BA_ "SPN" SG_ 2498779902 EngCyl13AvrgCntrOfCmbstionTiming 6533;
BA_ "SigType" SG_ 2498779902 EngCyl13AvrgStrtOfCmbstionTiming 1;
BA_ "SPN" SG_ 2498779902 EngCyl13AvrgStrtOfCmbstionTiming 6532;
BA_ "SigType" SG_ 2498779902 EngCyl13IndctdMeanEffectivePress 1;
BA_ "SPN" SG_ 2498779902 EngCyl13IndctdMeanEffectivePress 6531;
BA_ "SigType" SG_ 2498779646 EngCyl12AvrageCombustionDuration 1;
BA_ "SPN" SG_ 2498779646 EngCyl12AvrageCombustionDuration 6530;
BA_ "SigType" SG_ 2498779646 EngCyl12AvrgCntrOfCmbstionTiming 1;
BA_ "SPN" SG_ 2498779646 EngCyl12AvrgCntrOfCmbstionTiming 6529;
BA_ "SigType" SG_ 2498779646 EngCyl12AvrgStrtOfCmbstionTiming 1;
BA_ "SPN" SG_ 2498779646 EngCyl12AvrgStrtOfCmbstionTiming 6528;
BA_ "SigType" SG_ 2498779646 EngCyl12IndctdMeanEffectivePress 1;
BA_ "SPN" SG_ 2498779646 EngCyl12IndctdMeanEffectivePress 6527;
BA_ "SigType" SG_ 2498779390 EngCyl11AvrageCombustionDuration 1;
BA_ "SPN" SG_ 2498779390 EngCyl11AvrageCombustionDuration 6526;
BA_ "SigType" SG_ 2498779390 EngCyl11AvrgCntrOfCmbstionTiming 1;
BA_ "SPN" SG_ 2498779390 EngCyl11AvrgCntrOfCmbstionTiming 6525;
BA_ "SigType" SG_ 2498779390 EngCyl11AvrgStrtOfCmbstionTiming 1;
BA_ "SPN" SG_ 2498779390 EngCyl11AvrgStrtOfCmbstionTiming 6524;
BA_ "SigType" SG_ 2498779390 EngCyl11IndctdMeanEffectivePress 1;
BA_ "SPN" SG_ 2498779390 EngCyl11IndctdMeanEffectivePress 6523;
BA_ "SigType" SG_ 2498779134 EngCyl10AvrageCombustionDuration 1;
BA_ "SPN" SG_ 2498779134 EngCyl10AvrageCombustionDuration 6522;
BA_ "SigType" SG_ 2498779134 EngCyl10AvrgCntrOfCmbstionTiming 1;
BA_ "SPN" SG_ 2498779134 EngCyl10AvrgCntrOfCmbstionTiming 6521;
BA_ "SigType" SG_ 2498779134 EngCyl10AvrgStrtOfCmbstionTiming 1;
BA_ "SPN" SG_ 2498779134 EngCyl10AvrgStrtOfCmbstionTiming 6520;
BA_ "SigType" SG_ 2498779134 EngCyl10IndctdMeanEffectivePress 1;
BA_ "SPN" SG_ 2498779134 EngCyl10IndctdMeanEffectivePress 6519;
BA_ "SigType" SG_ 2498778878 EngCyl9AverageCombustionDuration 1;
BA_ "SPN" SG_ 2498778878 EngCyl9AverageCombustionDuration 6518;
BA_ "SigType" SG_ 2498778878 EngCyl9AvrgCntrOfCmbustionTiming 1;
BA_ "SPN" SG_ 2498778878 EngCyl9AvrgCntrOfCmbustionTiming 6517;
BA_ "SigType" SG_ 2498778878 EngCyl9AvrgStrtOfCmbustionTiming 1;
BA_ "SPN" SG_ 2498778878 EngCyl9AvrgStrtOfCmbustionTiming 6516;
BA_ "SigType" SG_ 2498778878 EngCyl9IndctedMeanEffectivePress 1;
BA_ "SPN" SG_ 2498778878 EngCyl9IndctedMeanEffectivePress 6515;
BA_ "SPN" SG_ 2365428734 GenFrequencySelection 4080;
BA_ "SigType" SG_ 2365428734 GenGoverningSpeedCommand 5;
BA_ "SPN" SG_ 2365428734 GenGoverningSpeedCommand 4079;
BA_ "SigType" SG_ 2365428734 GenAlternatorEfficiency 1;
BA_ "SPN" SG_ 2365428734 GenAlternatorEfficiency 4078;
BA_ "SigType" SG_ 2365428734 GenNotReadyToAutoParaState 5;
BA_ "SPN" SG_ 2365428734 GenNotReadyToAutoParaState 3568;
BA_ "SigType" SG_ 2365428734 GenCtrlNotInAutoStartState 5;
BA_ "SPN" SG_ 2365428734 GenCtrlNotInAutoStartState 3567;
BA_ "SigType" SG_ 2365428734 RequestedEngineControlMode 4;
BA_ "SPN" SG_ 2365428734 RequestedEngineControlMode 3542;
BA_ "SigType" SG_ 2365428734 EngSpeedGovernorDroop 1;
BA_ "SPN" SG_ 2365428734 EngSpeedGovernorDroop 5568;
BA_ "SigType" SG_ 2365428734 EngSpeedGovernorGainAdjust 1;
BA_ "SPN" SG_ 2365428734 EngSpeedGovernorGainAdjust 5567;
BA_ "SigType" SG_ 2566702846 EngOBDWarmUpSequence 5;
BA_ "SPN" SG_ 2566702846 EngOBDWarmUpSequence 5843;
BA_ "SPN" SG_ 2566703102 CertificationEngineFamilyName 5845;
BA_ "SigType" SG_ 2566703102 ModelYear 3;
BA_ "SPN" SG_ 2566703102 ModelYear 5844;
BA_ "SigType" SG_ 2566705918 DTC1 7;
BA_ "SigType" SG_ 2566705918 FlashProtectLamp 5;
BA_ "SPN" SG_ 2566705918 FlashProtectLamp 3041;
BA_ "SigType" SG_ 2566705918 FlashAmberWarningLamp 5;
BA_ "SPN" SG_ 2566705918 FlashAmberWarningLamp 3040;
BA_ "SigType" SG_ 2566705918 FlashRedStopLamp 5;
BA_ "SPN" SG_ 2566705918 FlashRedStopLamp 3039;
BA_ "SigType" SG_ 2566705918 FlashMalfuncIndicatorLamp 5;
BA_ "SPN" SG_ 2566705918 FlashMalfuncIndicatorLamp 3038;
BA_ "SigType" SG_ 2566705918 ProtectLampStatus 5;
BA_ "SPN" SG_ 2566705918 ProtectLampStatus 987;
BA_ "SigType" SG_ 2566705918 AmberWarningLampStatus 5;
BA_ "SPN" SG_ 2566705918 AmberWarningLampStatus 624;
BA_ "SigType" SG_ 2566705918 RedStopLampState 4;
BA_ "SPN" SG_ 2566705918 RedStopLampState 623;
BA_ "SigType" SG_ 2566705918 MalfunctionIndicatorLampStatus 5;
BA_ "SPN" SG_ 2566705918 MalfunctionIndicatorLampStatus 1213;
BA_ "SigType" SG_ 2566705918 DTC5 7;
BA_ "SigType" SG_ 2566705918 DTC4 7;
BA_ "SigType" SG_ 2566705918 DTC3 7;
BA_ "SigType" SG_ 2566705918 DTC2 7;
BA_ "SigType" SG_ 2566705662 DTC1 7;
BA_ "SigType" SG_ 2566705662 FlashProtectLamp 5;
BA_ "SPN" SG_ 2566705662 FlashProtectLamp 3041;
BA_ "SigType" SG_ 2566705662 FlashAmberWarningLamp 5;
BA_ "SPN" SG_ 2566705662 FlashAmberWarningLamp 3040;
BA_ "SigType" SG_ 2566705662 FlashRedStopLamp 5;
BA_ "SPN" SG_ 2566705662 FlashRedStopLamp 3039;
BA_ "SigType" SG_ 2566705662 FlashMalfuncIndicatorLamp 5;
BA_ "SPN" SG_ 2566705662 FlashMalfuncIndicatorLamp 3038;
BA_ "SigType" SG_ 2566705662 ProtectLampStatus 5;
BA_ "SPN" SG_ 2566705662 ProtectLampStatus 987;
BA_ "SigType" SG_ 2566705662 AmberWarningLampStatus 5;
BA_ "SPN" SG_ 2566705662 AmberWarningLampStatus 624;
BA_ "SigType" SG_ 2566705662 RedStopLampState 4;
BA_ "SPN" SG_ 2566705662 RedStopLampState 623;
BA_ "SigType" SG_ 2566705662 MalfunctionIndicatorLampStatus 5;
BA_ "SPN" SG_ 2566705662 MalfunctionIndicatorLampStatus 1213;
BA_ "SigType" SG_ 2566705662 DTC5 7;
BA_ "SigType" SG_ 2566705662 DTC4 7;
BA_ "SigType" SG_ 2566705662 DTC3 7;
BA_ "SigType" SG_ 2566705662 DTC2 7;
BA_ "SPN" SG_ 2349465342 StaticRollAngleStatus 5583;
BA_ "SigType" SG_ 2349465342 StaticRollAngle 1;
BA_ "GenSigStartValue" SG_ 2349465342 StaticRollAngle 35;
BA_ "SPN" SG_ 2349465342 StaticRollAngle 5582;
BA_ "SigType" SG_ 2498777086 EngCyl2AverageCombustionDuration 1;
BA_ "SPN" SG_ 2498777086 EngCyl2AverageCombustionDuration 6490;
BA_ "SigType" SG_ 2498777086 EngCyl2AvrgCntrOfCmbustionTiming 1;
BA_ "SPN" SG_ 2498777086 EngCyl2AvrgCntrOfCmbustionTiming 6489;
BA_ "SigType" SG_ 2498777086 EngCyl2AvrgStrtOfCmbustionTiming 1;
BA_ "SPN" SG_ 2498777086 EngCyl2AvrgStrtOfCmbustionTiming 6488;
BA_ "SigType" SG_ 2498777086 EngCyl2IndctedMeanEffectivePress 1;
BA_ "SPN" SG_ 2498777086 EngCyl2IndctedMeanEffectivePress 6487;
BA_ "SigType" SG_ 2498776830 EngCyl1AverageCombustionDuration 1;
BA_ "SPN" SG_ 2498776830 EngCyl1AverageCombustionDuration 6486;
BA_ "SigType" SG_ 2498776830 EngCyl1AvrgCntrOfCmbustionTiming 1;
BA_ "SPN" SG_ 2498776830 EngCyl1AvrgCntrOfCmbustionTiming 6485;
BA_ "SigType" SG_ 2498776830 EngCyl1AvrgStrtOfCmbustionTiming 1;
BA_ "SPN" SG_ 2498776830 EngCyl1AvrgStrtOfCmbustionTiming 6484;
BA_ "SigType" SG_ 2498776830 EngCyl1IndctedMeanEffectivePress 1;
BA_ "SPN" SG_ 2498776830 EngCyl1IndctedMeanEffectivePress 6483;
BA_ "SigType" SG_ 2364558846 MaxPressIncreaseRate 1;
BA_ "SPN" SG_ 2364558846 MaxPressIncreaseRate 7648;
BA_ "SigType" SG_ 2364558846 LowFreqKnockLvl 1;
BA_ "SPN" SG_ 2364558846 LowFreqKnockLvl 7628;
BA_ "SPN" SG_ 2364558846 EngCyl20PrssSensorPreliminaryFMI 6475;
BA_ "SigType" SG_ 2364558846 EngCyl20SynchronousKnockLevel 1;
BA_ "SPN" SG_ 2364558846 EngCyl20SynchronousKnockLevel 6474;
BA_ "SigType" SG_ 2364558846 EngCyl20PeakPress 1;
BA_ "SPN" SG_ 2364558846 EngCyl20PeakPress 6473;
BA_ "SigType" SG_ 2364558846 EngCyl20HeatRelease 1;
BA_ "SPN" SG_ 2364558846 EngCyl20HeatRelease 6472;
BA_ "SigType" SG_ 2364558590 MaxPressIncreaseRate 1;
BA_ "SPN" SG_ 2364558590 MaxPressIncreaseRate 7647;
BA_ "SigType" SG_ 2364558590 LowFreqKnockLvl 1;
BA_ "SPN" SG_ 2364558590 LowFreqKnockLvl 7627;
BA_ "SPN" SG_ 2364558590 EngCyl19PrssSensorPreliminaryFMI 6471;
BA_ "SigType" SG_ 2364558590 EngCyl19SynchronousKnockLevel 1;
BA_ "SPN" SG_ 2364558590 EngCyl19SynchronousKnockLevel 6470;
BA_ "SigType" SG_ 2364558590 EngCyl19PeakPress 1;
BA_ "SPN" SG_ 2364558590 EngCyl19PeakPress 6469;
BA_ "SigType" SG_ 2364558590 EngCyl19HeatRelease 1;
BA_ "SPN" SG_ 2364558590 EngCyl19HeatRelease 6468;
BA_ "SigType" SG_ 2364558334 MaxPressIncreaseRate 1;
BA_ "SPN" SG_ 2364558334 MaxPressIncreaseRate 7646;
BA_ "SigType" SG_ 2364558334 LowFreqKnockLvl 1;
BA_ "SPN" SG_ 2364558334 LowFreqKnockLvl 7626;
BA_ "SPN" SG_ 2364558334 EngCyl18PrssSensorPreliminaryFMI 6467;
BA_ "SigType" SG_ 2364558334 EngCyl18SynchronousKnockLevel 1;
BA_ "SPN" SG_ 2364558334 EngCyl18SynchronousKnockLevel 6466;
BA_ "SigType" SG_ 2364558334 EngCyl18PeakPress 1;
BA_ "SPN" SG_ 2364558334 EngCyl18PeakPress 6465;
BA_ "SigType" SG_ 2364558334 EngCyl18HeatRelease 1;
BA_ "SPN" SG_ 2364558334 EngCyl18HeatRelease 6464;
BA_ "SigType" SG_ 2364558078 MaxPressIncreaseRate 1;
BA_ "SPN" SG_ 2364558078 MaxPressIncreaseRate 7645;
BA_ "SigType" SG_ 2364558078 LowFreqKnockLvl 1;
BA_ "SPN" SG_ 2364558078 LowFreqKnockLvl 7625;
BA_ "SPN" SG_ 2364558078 EngCyl17PrssSensorPreliminaryFMI 6463;
BA_ "SigType" SG_ 2364558078 EngCyl17SynchronousKnockLevel 1;
BA_ "SPN" SG_ 2364558078 EngCyl17SynchronousKnockLevel 6462;
BA_ "SigType" SG_ 2364558078 EngCyl17PeakPress 1;
BA_ "SPN" SG_ 2364558078 EngCyl17PeakPress 6461;
BA_ "SigType" SG_ 2364558078 EngCyl17HeatRelease 1;
BA_ "SPN" SG_ 2364558078 EngCyl17HeatRelease 6460;
BA_ "SigType" SG_ 2364557822 MaxPressIncreaseRate 1;
BA_ "SPN" SG_ 2364557822 MaxPressIncreaseRate 7644;
BA_ "SigType" SG_ 2364557822 LowFreqKnockLvl 1;
BA_ "SPN" SG_ 2364557822 LowFreqKnockLvl 7624;
BA_ "SPN" SG_ 2364557822 EngCyl16PrssSensorPreliminaryFMI 6459;
BA_ "SigType" SG_ 2364557822 EngCyl16SynchronousKnockLevel 1;
BA_ "SPN" SG_ 2364557822 EngCyl16SynchronousKnockLevel 6458;
BA_ "SigType" SG_ 2364557822 EngCyl16PeakPress 1;
BA_ "SPN" SG_ 2364557822 EngCyl16PeakPress 6457;
BA_ "SigType" SG_ 2364557822 EngCyl16HeatRelease 1;
BA_ "SPN" SG_ 2364557822 EngCyl16HeatRelease 6456;
VAL_ 2566697470 EngIgntCtrlModule2State 7 "Not available" 6 "Error" 5 "Reserved" 4 "Firing Ignition in Normal Mode" 3 "Firing Ignition in Test Mode" 2 "Stalled" 1 "Shutdown" 0 "Disabled" ;
VAL_ 2566697470 EngIgntCtrlModule1State 7 "Not available" 6 "Error" 5 "Reserved" 4 "Firing Ignition in Normal Mode" 3 "Firing Ignition in Test Mode" 2 "Stalled" 1 "Shutdown" 0 "Disabled" ;
VAL_ 2566692862 DisplayRemainPowered 3 "Don't care" 2 "Reserved" 1 "Remain Powered" 0 "OK to Shutoff" ;
VAL_ 2499583742 EngTimingActuator2RequestedPos 7 "Not Available" 4 "Diesel Part Load / Gas Mode Position" 3 "Gas Mode Position" 2 "Diesel Part Load Position" 1 "Diesel Mode Position" 0 "Position Not Requested" ;
VAL_ 2499583742 EngTimingActuator1RequestedPos 7 "Not Available" 4 "Diesel Part Load / Gas Mode Position" 3 "Gas Mode Position" 2 "Diesel Part Load Position" 1 "Diesel Mode Position" 0 "Position Not Requested" ;
VAL_ 2499583742 EngTimingActuator2 7 "Not Available" 4 "Diesel Part Load / Gas Mode Position" 3 "Gas Mode Position" 2 "Diesel Part Load Position" 1 "Diesel Mode Position" 0 "Unknown Position" ;
VAL_ 2499583742 EngTimingActuator1 7 "Not Available" 4 "Diesel Part Load / Gas Mode Position" 3 "Gas Mode Position" 2 "Diesel Part Load Position" 1 "Diesel Mode Position" 0 "Unknown Position" ;
VAL_ 2499583486 EngTimingActuator2PosCmd 7 "Not Available" 4 "Diesel Part Load / Gas Mode Position" 3 "Gas Mode Position" 2 "Diesel Part Load Position" 1 "Diesel Mode Position" 0 "Reserved" ;
VAL_ 2499583486 EngTimingActuator1PosCmd 7 "Not Available" 4 "Diesel Part Load / Gas Mode Position" 3 "Gas Mode Position" 2 "Diesel Part Load Position" 1 "Diesel Mode Position" 0 "Reserved" ;
VAL_ 2566692094 Joystick1Lamp10Status 3 "Not available" 2 "Flashing" 1 "On" 0 "Off" ;
VAL_ 2566692094 Joystick1Lamp9Status 3 "Not available" 2 "Flashing" 1 "On" 0 "Off" ;
VAL_ 2566692094 Joystick1Lamp8Status 3 "Not available" 2 "Flashing" 1 "On" 0 "Off" ;
VAL_ 2566692094 Joystick1Lamp7Status 3 "Not available" 2 "Flashing" 1 "On" 0 "Off" ;
VAL_ 2566692094 Joystick1Lamp6Status 3 "Not available" 2 "Flashing" 1 "On" 0 "Off" ;
VAL_ 2566692094 Joystick1Lamp5Status 3 "Not available" 2 "Flashing" 1 "On" 0 "Off" ;
VAL_ 2566692094 Joystick1Lamp4Status 3 "Not available" 2 "Flashing" 1 "On" 0 "Off" ;
VAL_ 2566692094 Joystick1Lamp3Status 3 "Not available" 2 "Flashing" 1 "On" 0 "Off" ;
VAL_ 2566692094 Joystick1Lamp2Status 3 "Not available" 2 "Flashing" 1 "On" 0 "Off" ;
VAL_ 2566692094 Joystick1Lamp1Status 3 "Not available" 2 "Flashing" 1 "On" 0 "Off" ;
VAL_ 2566691838 Joystick2Lamp10Status 3 "Not available" 2 "Flashing" 1 "On" 0 "Off" ;
VAL_ 2566691838 Joystick2Lamp9Status 3 "Not available" 2 "Flashing" 1 "On" 0 "Off" ;
VAL_ 2566691838 Joystick2Lamp8Status 3 "Not available" 2 "Flashing" 1 "On" 0 "Off" ;
VAL_ 2566691838 Joystick2Lamp7Status 3 "Not available" 2 "Flashing" 1 "On" 0 "Off" ;
VAL_ 2566691838 Joystick2Lamp6Status 3 "Not available" 2 "Flashing" 1 "On" 0 "Off" ;
VAL_ 2566691838 Joystick2Lamp5Status 1 "On" 0 "Off" 3 "Not available" 2 "Flashing" ;
VAL_ 2566691838 Joystick2Lamp4Status 3 "Not available" 2 "Flashing" 1 "On" 0 "Off" ;
VAL_ 2566691838 Joystick2Lamp3Status 3 "Not available" 2 "Flashing" 1 "On" 0 "Off" ;
VAL_ 2566691838 Joystick2Lamp2Status 3 "Not available" 2 "Flashing" 1 "On" 0 "Off" ;
VAL_ 2566691838 Joystick2Lamp1Status 3 "Not available" 2 "Flashing" 1 "On" 0 "Off" ;
VAL_ 2566691582 Joystick3Lamp10Status 3 "Not available" 2 "Flashing" 1 "On" 0 "Off" ;
VAL_ 2566691582 Joystick3Lamp9Status 3 "Not available" 2 "Flashing" 1 "On" 0 "Off" ;
VAL_ 2566691582 Joystick3Lamp8Status 3 "Not available" 2 "Flashing" 1 "On" 0 "Off" ;
VAL_ 2566691582 Joystick3Lamp7Status 3 "Not available" 2 "Flashing" 1 "On" 0 "Off" ;
VAL_ 2566691582 Joystick3Lamp6Status 3 "Not available" 2 "Flashing" 1 "On" 0 "Off" ;
VAL_ 2566691582 Joystick3Lamp5Status 3 "Not available" 2 "Flashing" 1 "On" 0 "Off" ;
VAL_ 2566691582 Joystick3Lamp4Status 3 "Not available" 2 "Flashing" 1 "On" 0 "Off" ;
VAL_ 2566691582 Joystick3Lamp3Status 3 "Not available" 2 "Flashing" 1 "On" 0 "Off" ;
VAL_ 2566691582 Joystick3Lamp2Status 3 "Not available" 2 "Flashing" 1 "On" 0 "Off" ;
VAL_ 2566691582 Joystick3Lamp1Status 3 "Not available" 2 "Flashing" 1 "On" 0 "Off" ;
VAL_ 2499582206 SoftTopLifetimeLimitExceeded 3 "Not Available" 2 "Reserved" 1 "Soft top ratio limit has been exceeded" 0 "Soft top ratio limit has not been exceeded" ;
VAL_ 2499582206 SoftTopSpeedLimitActive 3 "Not Available" 2 "Reserved" 1 "Soft Top Speed Limit is Active" 0 "Soft Top Speed Limit is Inactive" ;
VAL_ 2566690814 CrabSteerModeActuatorState 3 "Not Available" 2 "Error" 1 "Crab Steer Mode actuator active" 0 "Crab Steer Mode actuator inactive" ;
VAL_ 2566690814 CircleSteerModeActuatorState 3 "Not Available" 2 "Error" 1 "Circle Steer Mode actuator active" 0 "Circle Steer Mode actuator inactive" ;
VAL_ 2566690814 VourWheelSteerActuatorState 3 "Not Available" 2 "Error" 1 "4 Wheel Steer actuator active" 0 "4 Wheel Steer actuator inactive" ;
VAL_ 2566690814 TwoWheelSteerActuatorState 3 "Not Available" 2 "Error" 1 "2 Wheel Steer actuator active" 0 "2 Wheel Steer actuator inactive" ;
VAL_ 2566690814 RearSteerAxleCenteredStatus 3 "Not Available" 2 "Error" 1 "Rear Axle Not Centered" 0 "Rear Axle Centered" ;
VAL_ 2566690814 FrontSteerAxleCenteredStatus 3 "Not Available" 2 "Error" 1 "Front Axle Not Centered" 0 "Front Axle Centered" ;
VAL_ 2566690814 SteerModeSwitch 7 "Not Available" 6 "Error" 3 "Crab Steer Mode" 1 "Circle Steer Mode" 0 "2 Wheel Steer Mode" ;
VAL_ 2566690046 AfterrunCompleteThisCycle 3 "Not Supported" 2 "Error" 1 "Complete" 0 "Not complete" ;
VAL_ 2566690046 DEFDoserPurgeCompleteLastCycle 3 "Not Supported" 2 "Error" 1 "Complete" 0 "Not complete" ;
VAL_ 2566690046 DEFDoserPurgeCompleteThisCycle 3 "Not Supported" 2 "Error" 1 "Complete" 0 "Not complete" ;
VAL_ 2566690046 DEFDoserCldnCompleteLastCycle 3 "Not Supported" 2 "Error" 1 "Complete" 0 "Not complete" ;
VAL_ 2566690046 DEFDoserCldnCompleteThisCycle 3 "Not Supported" 2 "Error" 1 "Complete" 0 "Not complete" ;
VAL_ 2365428734 GenFrequencySelection 14 "Unknown" 2 "400 Hz" 1 "60 Hz" 0 "50 Hz" ;
VAL_ 2365428734 GenGoverningSpeedCommand 3 "Don't care / take no action" 2 "Reserved" 1 "Low Idle Speed" 0 "Rated Speed" ;
VAL_ 2365428734 GenNotReadyToAutoParaState 3 "not available" 2 "error" 1 "active" 0 "inactive" ;
VAL_ 2365428734 GenCtrlNotInAutoStartState 3 "not available" 2 "error" 1 "active" 0 "inactive" ;
VAL_ 2566702846 EngOBDWarmUpSequence 3 "Not supported or not available" 2 "SAE reserved" 1 "A warm-up cycle has occurred on this engine start" 0 "A warm-up cycle has not occurred on this engine start" ;
VAL_ 2566705918 FlashProtectLamp 3 "Unavailable / Do Not Flash" 2 "Reserved" 1 "Fast Flash" 0 "Slow Flash" ;
VAL_ 2566705918 FlashAmberWarningLamp 3 "Unavailable / Do Not Flash" 2 "Reserved" 1 "Fast Flash" 0 "Slow Flash" ;
VAL_ 2566705918 FlashRedStopLamp 3 "Unavailable / Do Not Flash" 2 "Reserved" 1 "Fast Flash" 0 "Slow Flash" ;
VAL_ 2566705918 FlashMalfuncIndicatorLamp 3 "Unavailable / Do Not Flash" 2 "Class C DTC  " 1 "Fast Flash" 0 "Slow Flash" ;
VAL_ 2566705918 ProtectLampStatus 3 "Not available" 2 "Reserved" 1 "Lamp On" 0 "Lamp Off" ;
VAL_ 2566705918 AmberWarningLampStatus 3 "Not available" 2 "Reserved" 1 "Lamp On" 0 "Lamp Off" ;
VAL_ 2566705918 RedStopLampState 3 "Not available" 2 "Reserved" 1 "Lamp On" 0 "Lamp Off" ;
VAL_ 2566705918 MalfunctionIndicatorLampStatus 3 "Not available" 2 "Short MIL for WWH OBD" 1 "Lamp On" 0 "Lamp Off" ;
VAL_ 2566705662 FlashProtectLamp 3 "Unavailable / Do Not Flash" 2 "Reserved" 1 "Fast Flash" 0 "Slow Flash" ;
VAL_ 2566705662 FlashAmberWarningLamp 3 "Unavailable / Do Not Flash" 2 "Reserved" 1 "Fast Flash" 0 "Slow Flash" ;
VAL_ 2566705662 FlashRedStopLamp 3 "Unavailable / Do Not Flash" 2 "Reserved" 1 "Fast Flash" 0 "Slow Flash" ;
VAL_ 2566705662 FlashMalfuncIndicatorLamp 3 "Unavailable / Do Not Flash" 2 "Class C DTC  " 1 "Fast Flash" 0 "Slow Flash" ;
VAL_ 2566705662 ProtectLampStatus 3 "Not available" 2 "Reserved" 1 "Lamp On" 0 "Lamp Off" ;
VAL_ 2566705662 AmberWarningLampStatus 3 "Not available" 2 "Reserved" 1 "Lamp On" 0 "Lamp Off" ;
VAL_ 2566705662 RedStopLampState 3 "Not available" 2 "Reserved" 1 "Lamp On" 0 "Lamp Off" ;
VAL_ 2566705662 MalfunctionIndicatorLampStatus 3 "Not available" 2 "Short MIL for WWH OBD" 1 "Lamp On" 0 "Lamp Off" ;
VAL_ 2349465342 StaticRollAngleStatus 7 "Not available" 6 "Error" 5 "Reserved" 4 "Angle Data Invalid" 3 "Sensor Reboots" 2 "Sensor Defect" 1 "Sensor OK" 0 "Sensor Busy" ;
